VERSION "DNNBNNNYNNNNNNNNNNNNNNNNNNNNNNNNNNNNNNNNNN/4/%%%/4/'%**4NNN///"

NS_ :

BS_:

BU_: Vector__XXX xSolarWave xSolarSurveyor xSolarStorm xNova xMiata_SCP xMiata_AGS UI INV_CHG INV GATEWAY EMS DIAG CHG BMS BATTMON AGS

BO_ 2147554560 IntTempCfgUt: 223 AGS
 SG_ UtLvlMin : 88|32@1- (0.001,0) [-2.14748E+06|2.14748E+06] "°K" AGS,BATTMON,CHG,DIAG,GATEWAY,INV,INV_CHG,UI,xSolarSurveyor
 SG_ UtLvlMax : 120|32@1- (0.001,0) [-2.14748E+06|2.14748E+06] "°K" AGS,BATTMON,CHG,DIAG,GATEWAY,INV,INV_CHG,UI,xSolarSurveyor
 SG_ UtLvl : 56|32@1- (0.001,0) [-2.14748E+06|2.14748E+06] "°K" AGS,BATTMON,CHG,DIAG,GATEWAY,INV,INV_CHG,UI,xSolarSurveyor
 SG_ UtIntvlMin : 168|16@1+ (0.01,0) [0|655.32] "seconds" AGS,BATTMON,CHG,DIAG,GATEWAY,INV,INV_CHG,UI,xSolarSurveyor
 SG_ UtIntvlMax : 184|16@1+ (0.01,0) [0|655.32] "seconds" AGS,BATTMON,CHG,DIAG,GATEWAY,INV,INV_CHG,UI,xSolarSurveyor
 SG_ UtIntvl : 152|16@1+ (0.01,0) [0|655.32] "seconds" AGS,BATTMON,CHG,DIAG,GATEWAY,INV,INV_CHG,UI,xSolarSurveyor
 SG_ TempSensId : 16|8@1+ (1,0) [0|252] "" AGS,BATTMON,CHG,DIAG,GATEWAY,INV,INV_CHG,UI,xSolarSurveyor
 SG_ RefEvtId : 40|16@1+ (1,0) [0|65532] "" AGS,BATTMON,CHG,DIAG,GATEWAY,INV,INV_CHG,UI,xSolarSurveyor
 SG_ MsgCount : 2|6@1+ (1,0) [0|0] "" AGS,BATTMON,CHG,DIAG,GATEWAY,INV,INV_CHG,UI,xSolarSurveyor
 SG_ EvtId : 24|16@1+ (1,0) [0|65532] "" AGS,BATTMON,CHG,DIAG,GATEWAY,INV,INV_CHG,UI,xSolarSurveyor
 SG_ ConcurAccCtr : 8|8@1+ (1,0) [0|252] "" AGS,BATTMON,CHG,DIAG,GATEWAY,INV,INV_CHG,UI,xSolarSurveyor
 SG_ CfgType : 0|2@1+ (1,0) [0|0] "" AGS,BATTMON,CHG,DIAG,GATEWAY,INV,INV_CHG,UI,xSolarSurveyor

BO_ 2147554816 IntTempCfgOt: 223 AGS
 SG_ TempSensId : 16|8@1+ (1,0) [0|252] "" AGS,BATTMON,BMS,CHG,DIAG,GATEWAY,INV,INV_CHG,UI,xNova,xSolarSurveyor,xSolarWave
 SG_ RefEvtId : 40|16@1+ (1,0) [0|65532] "" AGS,BATTMON,BMS,CHG,DIAG,GATEWAY,INV,INV_CHG,UI,xNova,xSolarSurveyor,xSolarWave
 SG_ OtLvlMin : 88|32@1- (0.001,0) [-2.14748E+06|2.14748E+06] "°K" AGS,BATTMON,BMS,CHG,DIAG,GATEWAY,INV,INV_CHG,UI,xNova,xSolarSurveyor,xSolarWave
 SG_ OtLvlMax : 120|32@1- (0.001,0) [-2.14748E+06|2.14748E+06] "°K" AGS,BATTMON,BMS,CHG,DIAG,GATEWAY,INV,INV_CHG,UI,xNova,xSolarSurveyor,xSolarWave
 SG_ OtLvl : 56|32@1- (0.001,0) [-2.14748E+06|2.14748E+06] "°K" AGS,BATTMON,BMS,CHG,DIAG,GATEWAY,INV,INV_CHG,UI,xNova,xSolarSurveyor,xSolarWave
 SG_ OtIntvlMin : 168|16@1+ (0.01,0) [0|655.32] "seconds" AGS,BATTMON,BMS,CHG,DIAG,GATEWAY,INV,INV_CHG,UI,xNova,xSolarSurveyor,xSolarWave
 SG_ OtIntvlMax : 184|16@1+ (0.01,0) [0|655.32] "seconds" AGS,BATTMON,BMS,CHG,DIAG,GATEWAY,INV,INV_CHG,UI,xNova,xSolarSurveyor,xSolarWave
 SG_ OtIntvl : 152|16@1+ (0.01,0) [0|655.32] "seconds" AGS,BATTMON,BMS,CHG,DIAG,GATEWAY,INV,INV_CHG,UI,xNova,xSolarSurveyor,xSolarWave
 SG_ MsgCount : 2|6@1+ (1,0) [0|0] "" AGS,BATTMON,BMS,CHG,DIAG,GATEWAY,INV,INV_CHG,UI,xNova,xSolarSurveyor,xSolarWave
 SG_ EvtId : 24|16@1+ (1,0) [0|65532] "" AGS,BATTMON,BMS,CHG,DIAG,GATEWAY,INV,INV_CHG,UI,xNova,xSolarSurveyor,xSolarWave
 SG_ ConcurAccCtr : 8|8@1+ (1,0) [0|252] "" AGS,BATTMON,BMS,CHG,DIAG,GATEWAY,INV,INV_CHG,UI,xNova,xSolarSurveyor,xSolarWave
 SG_ CfgType : 0|2@1+ (1,0) [0|0] "" AGS,BATTMON,BMS,CHG,DIAG,GATEWAY,INV,INV_CHG,UI,xNova,xSolarSurveyor,xSolarWave

BO_ 2147612688 HwRevSts: 223 AGS
 SG_ RsvBits2 : 29|3@1+ (1,0) [0|0] "" DIAG,UI
 SG_ RsvBits1 : 0|2@1+ (1,0) [0|0] "" DIAG,UI
 SG_ MsgCount : 2|6@1+ (1,0) [0|0] "" DIAG,UI
 SG_ ModelNum : 8|16@1+ (1,0) [0|65532] "" DIAG,UI
 SG_ HwModSerNum : 48|128@1+ (1,0) [0|1785] "characters" DIAG,UI
 SG_ HwModRev : 32|16@1+ (1,0) [0|65532] "" DIAG,UI
 SG_ HwModInst : 24|5@1+ (1,0) [0|0] "" DIAG,UI

BO_ 2147610635 HvDcBusSts: 10 CHG
 SG_ Voltage : 16|32@1- (0.001,0) [-2.14748E+06|2.14748E+06] "V" CHG,DIAG,INV,INV_CHG
 SG_ RsvBits : 0|2@1+ (1,0) [0|0] "" CHG,DIAG,INV,INV_CHG
 SG_ OutputId : 8|8@1+ (1,0) [0|252] "" CHG,DIAG,INV,INV_CHG
 SG_ MsgCount : 2|6@1+ (1,0) [0|0] "" CHG,DIAG,INV,INV_CHG
 SG_ Current : 48|32@1- (0.001,0) [-2.14748E+06|2.14748E+06] "Amps" CHG,DIAG,INV,INV_CHG

BO_ 2147553536 HvDcBusCfgUv: 223 CHG
 SG_ UvLvlMin : 88|32@1- (0.001,0) [-2.14748E+06|2.14748E+06] "V" CHG,DIAG,INV,INV_CHG
 SG_ UvLvlMax : 120|32@1- (0.001,0) [-2.14748E+06|2.14748E+06] "V" CHG,DIAG,INV,INV_CHG
 SG_ UvLvl : 56|32@1- (0.001,0) [-2.14748E+06|2.14748E+06] "V" CHG,DIAG,INV,INV_CHG
 SG_ UvIntvlMin : 168|16@1+ (0.01,0) [0|655.32] "seconds" CHG,DIAG,INV,INV_CHG
 SG_ UvIntvlMax : 184|16@1+ (0.01,0) [0|655.32] "seconds" CHG,DIAG,INV,INV_CHG
 SG_ UvIntvl : 152|16@1+ (0.01,0) [0|655.32] "seconds" CHG,DIAG,INV,INV_CHG
 SG_ RefEvtId : 40|16@1+ (1,0) [0|65532] "" CHG,DIAG,INV,INV_CHG
 SG_ OutputId : 16|8@1+ (1,0) [0|252] "" CHG,DIAG,INV,INV_CHG
 SG_ MsgCount : 2|6@1+ (1,0) [0|0] "" CHG,DIAG,INV,INV_CHG
 SG_ EvtId : 24|16@1+ (1,0) [0|65532] "" CHG,DIAG,INV,INV_CHG
 SG_ ConcurAccCtr : 8|8@1+ (1,0) [0|252] "" CHG,DIAG,INV,INV_CHG
 SG_ CfgType : 0|2@1+ (1,0) [0|0] "" CHG,DIAG,INV,INV_CHG

BO_ 2147553792 HvDcBusCfgOv: 223 CHG
 SG_ RefEvtId : 40|16@1+ (1,0) [0|65532] "" CHG,DIAG,INV,INV_CHG
 SG_ OvLvlMin : 88|32@1- (0.001,0) [-2.14748E+06|2.14748E+06] "V" CHG,DIAG,INV,INV_CHG
 SG_ OvLvlMax : 120|32@1- (0.001,0) [-2.14748E+06|2.14748E+06] "V" CHG,DIAG,INV,INV_CHG
 SG_ OvLvl : 56|32@1- (0.001,0) [-2.14748E+06|2.14748E+06] "V" CHG,DIAG,INV,INV_CHG
 SG_ OvIntvlMin : 168|16@1+ (0.01,0) [0|655.32] "seconds" CHG,DIAG,INV,INV_CHG
 SG_ OvIntvlMax : 184|16@1+ (0.01,0) [0|655.32] "seconds" CHG,DIAG,INV,INV_CHG
 SG_ OvIntvl : 152|16@1+ (0.01,0) [0|655.32] "seconds" CHG,DIAG,INV,INV_CHG
 SG_ OutputId : 16|8@1+ (1,0) [0|252] "" CHG,DIAG,INV,INV_CHG
 SG_ MsgCount : 2|6@1+ (1,0) [0|0] "" CHG,DIAG,INV,INV_CHG
 SG_ EvtId : 24|16@1+ (1,0) [0|65532] "" CHG,DIAG,INV,INV_CHG
 SG_ ConcurAccCtr : 8|8@1+ (1,0) [0|252] "" CHG,DIAG,INV,INV_CHG
 SG_ CfgType : 0|2@1+ (1,0) [0|0] "" CHG,DIAG,INV,INV_CHG

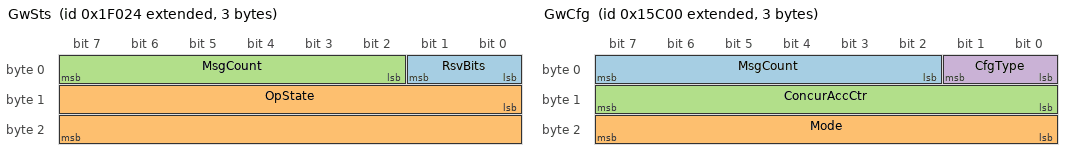
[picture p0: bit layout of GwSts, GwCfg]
BO_ 2147610660 GwSts: 3 GATEWAY
 SG_ RsvBits : 0|2@1+ (1,0) [0|0] "" DIAG,UI
 SG_ OpState : 8|16@1+ (1,0) [0|65532] "" DIAG,UI
 SG_ MsgCount : 2|6@1+ (1,0) [0|0] "" DIAG,UI

BO_ 2147610661 GwStats: 1 GATEWAY
 SG_ RsvBits : 0|2@1+ (1,0) [0|0] "" DIAG,UI
 SG_ MsgCount : 2|6@1+ (1,0) [0|0] "" DIAG,UI

BO_ 2147571968 GwCfgMsgFiltersXbIntf: 223 DIAG
 SG_ RsvBits : 42|6@1+ (1,0) [0|0] "" DIAG,GATEWAY
 SG_ Pgn : 16|24@1+ (1,0) [0|0] "" DIAG,GATEWAY
 SG_ MsgCount : 2|6@1+ (1,0) [0|0] "" DIAG,GATEWAY
 SG_ ConcurAccCtr : 8|8@1+ (1,0) [0|252] "" DIAG,GATEWAY
 SG_ CfgType : 0|2@1+ (1,0) [0|0] "" DIAG,GATEWAY
 SG_ AllowedEnDis : 40|2@1+ (1,0) [0|0] "" DIAG,GATEWAY

BO_ 2147572224 GwCfgMsgFiltersOthIntf: 223 DIAG
 SG_ RsvBits : 42|6@1+ (1,0) [0|0] "" DIAG,GATEWAY
 SG_ Pgn : 16|24@1+ (1,0) [0|0] "" DIAG,GATEWAY
 SG_ MsgCount : 2|6@1+ (1,0) [0|0] "" DIAG,GATEWAY
 SG_ ConcurAccCtr : 8|8@1+ (1,0) [0|252] "" DIAG,GATEWAY
 SG_ CfgType : 0|2@1+ (1,0) [0|0] "" DIAG,GATEWAY
 SG_ AllowedEnDis : 40|2@1+ (1,0) [0|0] "" DIAG,GATEWAY

BO_ 2147572992 GwCfgIdTrans: 223 DIAG
 SG_ XbId : 24|8@1+ (1,0) [0|252] "" DIAG,GATEWAY
 SG_ SrcType : 16|8@1+ (1,0) [0|252] "" DIAG,GATEWAY
 SG_ OthId : 32|8@1+ (1,0) [0|252] "" DIAG,GATEWAY
 SG_ MsgCount : 2|6@1+ (1,0) [0|0] "" DIAG,GATEWAY
 SG_ ConcurAccCtr : 8|8@1+ (1,0) [0|252] "" DIAG,GATEWAY
 SG_ CfgType : 0|2@1+ (1,0) [0|0] "" DIAG,GATEWAY

BO_ 2147571712 GwCfgAddrTransXbIntf: 223 DIAG
 SG_ XbSystemInstance : 40|4@1+ (1,0) [0|0] "" DIAG,GATEWAY
 SG_ XbDeviceInstanceUpper : 19|5@1+ (1,0) [0|0] "" DIAG,GATEWAY
 SG_ XbDeviceInstanceLower : 16|3@1+ (1,0) [0|0] "" DIAG,GATEWAY
 SG_ XbDeviceFunction : 24|8@1+ (1,0) [0|252] "" DIAG,GATEWAY
 SG_ XbDeviceClass : 33|7@1+ (1,0) [0|0] "" DIAG,GATEWAY
 SG_ RsvBits4 : 76|4@1+ (1,0) [0|0] "" DIAG,GATEWAY
 SG_ RsvBits3 : 64|1@1+ (1,0) [0|0] "" DIAG,GATEWAY
 SG_ RsvBits2 : 44|4@1+ (1,0) [0|0] "" DIAG,GATEWAY
 SG_ RsvBits1 : 32|1@1+ (1,0) [0|0] "" DIAG,GATEWAY
 SG_ OthSystemInstance : 72|4@1+ (1,0) [0|0] "" DIAG,GATEWAY
 SG_ OthDeviceInstanceUpper : 51|5@1+ (1,0) [0|0] "" DIAG,GATEWAY
 SG_ OthDeviceInstanceLower : 48|3@1+ (1,0) [0|0] "" DIAG,GATEWAY
 SG_ OthDeviceFunction : 56|8@1+ (1,0) [0|252] "" DIAG,GATEWAY
 SG_ OthDeviceClass : 65|7@1+ (1,0) [0|0] "" DIAG,GATEWAY
 SG_ MsgCount : 2|6@1+ (1,0) [0|0] "" DIAG,GATEWAY
 SG_ LoAddr : 80|8@1+ (1,0) [0|252] "" DIAG,GATEWAY
 SG_ HiAddr : 88|8@1+ (1,0) [0|252] "" DIAG,GATEWAY
 SG_ ConcurAccCtr : 8|8@1+ (1,0) [0|252] "" DIAG,GATEWAY
 SG_ CfgType : 0|2@1+ (1,0) [0|0] "" DIAG,GATEWAY

BO_ 2147572480 GwCfgAddrTransOthIntf: 223 DIAG
 SG_ XbSystemInstance : 72|4@1+ (1,0) [0|0] "" DIAG,GATEWAY
 SG_ XbDeviceInstanceUpper : 51|5@1+ (1,0) [0|0] "" DIAG,GATEWAY
 SG_ XbDeviceInstanceLower : 48|3@1+ (1,0) [0|0] "" DIAG,GATEWAY
 SG_ XbDeviceFunction : 56|8@1+ (1,0) [0|252] "" DIAG,GATEWAY
 SG_ XbDeviceClass : 65|7@1+ (1,0) [0|0] "" DIAG,GATEWAY
 SG_ RsvBits4 : 76|4@1+ (1,0) [0|0] "" DIAG,GATEWAY
 SG_ RsvBits3 : 64|1@1+ (1,0) [0|0] "" DIAG,GATEWAY
 SG_ RsvBits2 : 44|4@1+ (1,0) [0|0] "" DIAG,GATEWAY
 SG_ RsvBits1 : 32|1@1+ (1,0) [0|0] "" DIAG,GATEWAY
 SG_ OthSystemInstance : 40|4@1+ (1,0) [0|0] "" DIAG,GATEWAY
 SG_ OthDeviceInstanceUpper : 19|5@1+ (1,0) [0|0] "" DIAG,GATEWAY
 SG_ OthDeviceInstanceLower : 16|3@1+ (1,0) [0|0] "" DIAG,GATEWAY
 SG_ OthDeviceFunction : 24|8@1+ (1,0) [0|252] "" DIAG,GATEWAY
 SG_ OthDeviceClass : 33|7@1+ (1,0) [0|0] "" DIAG,GATEWAY
 SG_ MsgCount : 2|6@1+ (1,0) [0|0] "" DIAG,GATEWAY
 SG_ ConcurAccCtr : 8|8@1+ (1,0) [0|252] "" DIAG,GATEWAY
 SG_ CfgType : 0|2@1+ (1,0) [0|0] "" DIAG,GATEWAY

BO_ 2147572736 GwCfg: 3 DIAG
 SG_ MsgCount : 2|6@1+ (1,0) [0|0] "" DIAG,GATEWAY
 SG_ Mode : 16|8@1+ (1,0) [0|252] "" DIAG,GATEWAY
 SG_ ConcurAccCtr : 8|8@1+ (1,0) [0|252] "" DIAG,GATEWAY
 SG_ CfgType : 0|2@1+ (1,0) [0|0] "" DIAG,GATEWAY

BO_ 2147576320 GvsCfg: 52 DIAG
 SG_ VThresholdMin : 336|16@1+ (0.01,0) [0|655.32] "V" DIAG,UI,xSolarWave
 SG_ VThresholdMax : 352|16@1+ (0.01,0) [0|655.32] "V" DIAG,UI,xSolarWave
 SG_ VThreshold : 320|16@1+ (0.01,0) [0|655.32] "V" DIAG,UI,xSolarWave
 SG_ VSetLowMin : 288|16@1+ (0.01,0) [0|655.32] "V" DIAG,UI,xSolarWave
 SG_ VSetLowMax : 304|16@1+ (0.01,0) [0|655.32] "V" DIAG,UI,xSolarWave
 SG_ VSetLow : 272|16@1+ (0.01,0) [0|655.32] "V" DIAG,UI,xSolarWave
 SG_ VSetHighMin : 240|16@1+ (0.01,0) [0|655.32] "V" DIAG,UI,xSolarWave
 SG_ VSetHighMax : 256|16@1+ (0.01,0) [0|655.32] "V" DIAG,UI,xSolarWave
 SG_ VSetHigh : 224|16@1+ (0.01,0) [0|655.32] "V" DIAG,UI,xSolarWave
 SG_ RsvBits : 26|6@1+ (1,0) [0|0] "" DIAG,UI,xSolarWave
 SG_ MsgCount : 2|6@1+ (1,0) [0|0] "" DIAG,UI,xSolarWave
 SG_ MinVGridMin : 192|16@1+ (0.01,0) [0|655.32] "V" DIAG,UI,xSolarWave
 SG_ MinVGridMax : 208|16@1+ (0.01,0) [0|655.32] "V" DIAG,UI,xSolarWave
 SG_ MinVGrid : 176|16@1+ (0.01,0) [0|655.32] "V" DIAG,UI,xSolarWave
 SG_ MaxVGridMin : 144|16@1+ (0.01,0) [0|655.32] "V" DIAG,UI,xSolarWave
 SG_ MaxVGridMax : 160|16@1+ (0.01,0) [0|655.32] "V" DIAG,UI,xSolarWave
 SG_ MaxVGrid : 128|16@1+ (0.01,0) [0|655.32] "V" DIAG,UI,xSolarWave
 SG_ MaxQIndMin : 96|16@1+ (0.01,0) [0|655.32] "%" DIAG,UI,xSolarWave
 SG_ MaxQIndMax : 112|16@1+ (0.01,0) [0|655.32] "%" DIAG,UI,xSolarWave
 SG_ MaxQInd : 80|16@1+ (0.01,0) [0|655.32] "%" DIAG,UI,xSolarWave
 SG_ MaxQCapMin : 48|16@1+ (0.01,0) [0|655.32] "%" DIAG,UI,xSolarWave
 SG_ MaxQCapMax : 64|16@1+ (0.01,0) [0|655.32] "%" DIAG,UI,xSolarWave
 SG_ MaxQCap : 32|16@1+ (0.01,0) [0|655.32] "%" DIAG,UI,xSolarWave
 SG_ GvsEnDis : 24|2@1+ (1,0) [0|0] "" DIAG,UI,xSolarWave
 SG_ DelayTimeMin : 384|16@1+ (0.01,0) [0|655.32] "seconds" DIAG,UI,xSolarWave
 SG_ DelayTimeMax : 400|16@1+ (0.01,0) [0|655.32] "seconds" DIAG,UI,xSolarWave
 SG_ DelayTime : 368|16@1+ (0.01,0) [0|655.32] "seconds" DIAG,UI,xSolarWave
 SG_ ConcurAccCtr : 8|8@1+ (1,0) [0|252] "" DIAG,UI,xSolarWave
 SG_ CfgType : 0|2@1+ (1,0) [0|0] "" DIAG,UI,xSolarWave
 SG_ AcSrcId : 16|8@1+ (1,0) [0|252] "" DIAG,UI,xSolarWave

BO_ 2147575296 GridTieCtrlCmd: 3 DIAG
 SG_ MaxSellScalePrcnt : 8|16@1+ (0.01,0) [0|655.32] "%" INV,INV_CHG,xSolarWave
 SG_ AcSrcId : 0|8@1+ (1,0) [0|252] "" INV,INV_CHG,xSolarWave

BO_ 2147576576 GridTieCfgBattSoc: 22 DIAG
 SG_ TimeIntStopMin : 144|16@1+ (1,0) [0|65532] "seconds" DIAG,UI,xSolarWave
 SG_ TimeIntStopMax : 160|16@1+ (1,0) [0|65532] "seconds" DIAG,UI,xSolarWave
 SG_ TimeIntStop : 128|16@1+ (1,0) [0|65532] "seconds" DIAG,UI,xSolarWave
 SG_ TimeIntStartMin : 96|16@1+ (1,0) [0|65532] "seconds" DIAG,UI,xSolarWave
 SG_ TimeIntStartMax : 112|16@1+ (1,0) [0|65532] "seconds" DIAG,UI,xSolarWave
 SG_ TimeIntStart : 80|16@1+ (1,0) [0|65532] "seconds" DIAG,UI,xSolarWave
 SG_ SocLvlStopMin : 64|8@1+ (1,0) [0|252] "%" DIAG,UI,xSolarWave
 SG_ SocLvlStopMax : 72|8@1+ (1,0) [0|252] "%" DIAG,UI,xSolarWave
 SG_ SocLvlStop : 56|8@1+ (1,0) [0|252] "%" DIAG,UI,xSolarWave
 SG_ SocLvlStartMin : 40|8@1+ (1,0) [0|252] "%" DIAG,UI,xSolarWave
 SG_ SocLvlStartMax : 48|8@1+ (1,0) [0|252] "%" DIAG,UI,xSolarWave
 SG_ SocLvlStart : 32|8@1+ (1,0) [0|252] "%" DIAG,UI,xSolarWave
 SG_ RsvBits : 26|6@1+ (1,0) [0|0] "" DIAG,UI,xSolarWave
 SG_ MsgCount : 2|6@1+ (1,0) [0|0] "" DIAG,UI,xSolarWave
 SG_ GridTieSocEnDis : 24|2@1+ (1,0) [0|0] "" DIAG,UI,xSolarWave
 SG_ ConcurAccCtr : 8|8@1+ (1,0) [0|252] "" DIAG,UI,xSolarWave
 SG_ CfgType : 0|2@1+ (1,0) [0|0] "" DIAG,UI,xSolarWave
 SG_ AcSrcId : 16|8@1+ (1,0) [0|252] "" DIAG,UI,xSolarWave

BO_ 2147598336 GridTieCfg: 72 DIAG
 SG_ SellMode : 32|8@1+ (1,0) [0|252] "" DIAG,UI,xSolarWave
 SG_ SellDuration : 40|16@1+ (1,0) [0|65532] "minutes" DIAG,UI,xSolarWave
 SG_ RsvBits : 30|2@1+ (1,0) [0|0] "" DIAG,UI,xSolarWave
 SG_ PeakLoadShavingIMin : 192|32@1+ (0.001,0) [0|4.29497E+06] "Amps" DIAG,UI,xSolarWave
 SG_ PeakLoadShavingIMax : 224|32@1+ (0.001,0) [0|4.29497E+06] "Amps" DIAG,UI,xSolarWave
 SG_ PeakLoadShavingI : 160|32@1+ (0.001,0) [0|4.29497E+06] "Amps" DIAG,UI,xSolarWave
 SG_ PeakLoadShavingEnDis : 26|2@1+ (1,0) [0|0] "" DIAG,UI,xSolarWave
 SG_ MsgCount : 2|6@1+ (1,0) [0|0] "" DIAG,UI,xSolarWave
 SG_ MaxSellScalePrcnt : 56|8@1+ (1,0) [0|252] "%" DIAG,UI,xSolarWave
 SG_ MaxSellIMin : 96|32@1+ (0.001,0) [0|4.29497E+06] "Amps" DIAG,UI,xSolarWave
 SG_ MaxSellIMax : 128|32@1+ (0.001,0) [0|4.29497E+06] "Amps" DIAG,UI,xSolarWave
 SG_ MaxSellI : 64|32@1+ (0.001,0) [0|4.29497E+06] "Amps" DIAG,UI,xSolarWave
 SG_ GridTieEnDis : 28|2@1+ (1,0) [0|0] "" DIAG,UI,xSolarWave
 SG_ ConcurAccCtr : 8|8@1+ (1,0) [0|252] "" DIAG,UI,xSolarWave
 SG_ CfgType : 0|2@1+ (1,0) [0|0] "" DIAG,UI,xSolarWave
 SG_ AntiIslandingEnDis : 24|2@1+ (1,0) [0|0] "" DIAG,UI,xSolarWave
 SG_ AIReconnect : 256|16@1+ (1,0) [0|65532] "seconds" DIAG,UI,xSolarWave
 SG_ AIDisconUvLNSlow : 480|32@1+ (0.001,0) [0|4.29497E+06] "V" DIAG,UI,xSolarWave
 SG_ AIDisconUvLNFast : 448|32@1+ (0.001,0) [0|4.29497E+06] "V" DIAG,UI,xSolarWave
 SG_ AIDisconUvL1L2Slow : 512|32@1+ (0.001,0) [0|4.29497E+06] "V" DIAG,UI,xSolarWave
 SG_ AIDisconUvL1L2Fast : 544|32@1+ (0.001,0) [0|4.29497E+06] "V" DIAG,UI,xSolarWave
 SG_ AIDisconUf : 304|16@1+ (0.01,0) [0|655.32] "Hz" DIAG,UI,xSolarWave
 SG_ AIDisconSlowDelay : 272|16@1+ (0.001,0) [0|65.532] "seconds" DIAG,UI,xSolarWave
 SG_ AIDisconOvLNSlow : 352|32@1+ (0.001,0) [0|4.29497E+06] "V" DIAG,UI,xSolarWave
 SG_ AIDisconOvLNFast : 320|32@1+ (0.001,0) [0|4.29497E+06] "V" DIAG,UI,xSolarWave
 SG_ AIDisconOvL1L2Slow : 416|32@1+ (0.001,0) [0|4.29497E+06] "V" DIAG,UI,xSolarWave
 SG_ AIDisconOvL1L2Fast : 384|32@1+ (0.001,0) [0|4.29497E+06] "V" DIAG,UI,xSolarWave
 SG_ AIDisconOf : 288|16@1+ (0.01,0) [0|655.32] "Hz" DIAG,UI,xSolarWave
 SG_ AcSrcId : 16|8@1+ (1,0) [0|252] "" DIAG,UI,xSolarWave

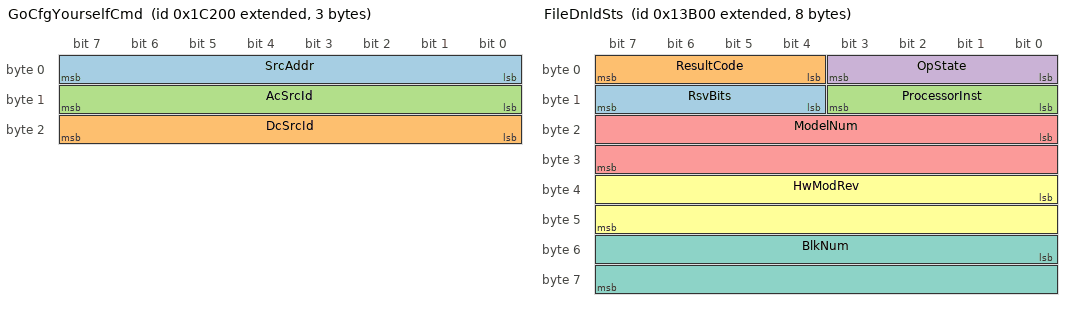
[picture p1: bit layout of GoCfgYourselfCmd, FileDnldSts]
BO_ 2147598848 GoCfgYourselfCmd: 3 DIAG
 SG_ SrcAddr : 0|8@1+ (1,0) [0|252] "" AGS,BATTMON,CHG,INV,INV_CHG,xSolarSurveyor,xSolarWave
 SG_ DcSrcId : 16|8@1+ (1,0) [0|252] "" AGS,BATTMON,CHG,INV,INV_CHG,xSolarSurveyor,xSolarWave
 SG_ AcSrcId : 8|8@1+ (1,0) [0|252] "" AGS,BATTMON,CHG,INV,INV_CHG,xSolarSurveyor,xSolarWave

BO_ 2147574016 GfsCfg: 58 DIAG
 SG_ RsvBits : 26|6@1+ (1,0) [0|0] "" DIAG,UI,xSolarWave
 SG_ MsgCount : 2|6@1+ (1,0) [0|0] "" DIAG,UI,xSolarWave
 SG_ GfsEnDis : 24|2@1+ (1,0) [0|0] "" DIAG,UI,xSolarWave
 SG_ ConcurAccCtr : 8|8@1+ (1,0) [0|252] "" DIAG,UI,xSolarWave
 SG_ CfgType : 0|2@1+ (1,0) [0|0] "" DIAG,UI,xSolarWave
 SG_ AprPtGradientMin : 432|16@1+ (1,0) [0|65532] "%" DIAG,UI,xSolarWave
 SG_ AprPtGradientMax : 448|16@1+ (1,0) [0|65532] "%" DIAG,UI,xSolarWave
 SG_ AprPtGradient : 416|16@1+ (1,0) [0|65532] "%" DIAG,UI,xSolarWave
 SG_ AprPfGradientMin : 384|16@1+ (1,0) [0|65532] "%" DIAG,UI,xSolarWave
 SG_ AprPfGradientMax : 400|16@1+ (1,0) [0|65532] "%" DIAG,UI,xSolarWave
 SG_ AprPfGradient : 368|16@1+ (1,0) [0|65532] "%" DIAG,UI,xSolarWave
 SG_ AprFreqStopLvlMin : 288|16@1+ (0.01,0) [0|655.32] "Hz" DIAG,UI,xSolarWave
 SG_ AprFreqStopLvlMax : 304|16@1+ (0.01,0) [0|655.32] "Hz" DIAG,UI,xSolarWave
 SG_ AprFreqStopLvl : 272|16@1+ (0.01,0) [0|655.32] "Hz" DIAG,UI,xSolarWave
 SG_ AprFreqStartLvlMin : 240|16@1+ (0.01,0) [0|655.32] "Hz" DIAG,UI,xSolarWave
 SG_ AprFreqStartLvlMax : 256|16@1+ (0.01,0) [0|655.32] "Hz" DIAG,UI,xSolarWave
 SG_ AprFreqStartLvl : 224|16@1+ (0.01,0) [0|655.32] "Hz" DIAG,UI,xSolarWave
 SG_ AprFreqRecoverLvlMin : 336|16@1+ (0.01,0) [0|655.32] "Hz" DIAG,UI,xSolarWave
 SG_ AprFreqRecoverLvlMax : 352|16@1+ (0.01,0) [0|655.32] "Hz" DIAG,UI,xSolarWave
 SG_ AprFreqRecoverLvl : 320|16@1+ (0.01,0) [0|655.32] "Hz" DIAG,UI,xSolarWave
 SG_ ApiPtGradientMin : 192|16@1+ (1,0) [0|65532] "%" DIAG,UI,xSolarWave
 SG_ ApiPtGradientMax : 208|16@1+ (1,0) [0|65532] "%" DIAG,UI,xSolarWave
 SG_ ApiPtGradient : 176|16@1+ (1,0) [0|65532] "%" DIAG,UI,xSolarWave
 SG_ ApiFreqStopLvlMin : 96|16@1+ (0.01,0) [0|655.32] "Hz" DIAG,UI,xSolarWave
 SG_ ApiFreqStopLvlMax : 112|16@1+ (0.01,0) [0|655.32] "Hz" DIAG,UI,xSolarWave
 SG_ ApiFreqStopLvl : 80|16@1+ (0.01,0) [0|655.32] "Hz" DIAG,UI,xSolarWave
 SG_ ApiFreqStartLvlMin : 48|16@1+ (0.01,0) [0|655.32] "Hz" DIAG,UI,xSolarWave
 SG_ ApiFreqStartLvlMax : 64|16@1+ (0.01,0) [0|655.32] "Hz" DIAG,UI,xSolarWave
 SG_ ApiFreqStartLvl : 32|16@1+ (0.01,0) [0|655.32] "Hz" DIAG,UI,xSolarWave
 SG_ ApiFreqRecoverLvlMin : 144|16@1+ (0.01,0) [0|655.32] "Hz" DIAG,UI,xSolarWave
 SG_ ApiFreqRecoverLvlMax : 160|16@1+ (0.01,0) [0|655.32] "Hz" DIAG,UI,xSolarWave
 SG_ ApiFreqRecoverLvl : 128|16@1+ (0.01,0) [0|655.32] "Hz" DIAG,UI,xSolarWave
 SG_ AcSrcId : 16|8@1+ (1,0) [0|252] "" DIAG,UI,xSolarWave

BO_ 2147564288 FileDnldSts: 8 Vector__XXX
 SG_ RsvBits : 12|4@1+ (1,0) [0|0] "" DIAG,UI
 SG_ ResultCode : 4|4@1+ (1,0) [0|0] "" DIAG,UI
 SG_ ProcessorInst : 8|4@1+ (1,0) [0|0] "" DIAG,UI
 SG_ OpState : 0|4@1+ (1,0) [0|0] "" DIAG,UI
 SG_ ModelNum : 16|16@1+ (1,0) [0|65532] "" DIAG,UI
 SG_ HwModRev : 32|16@1+ (1,0) [0|65532] "" DIAG,UI
 SG_ BlkNum : 48|16@1+ (1,0) [0|65532] "" DIAG,UI

BO_ 2147561984 FileDnldInf: 15 DIAG
 SG_ SwVer : 24|32@1+ (1,0) [0|4.29497E+09] "" Vector__XXX
 SG_ SwModId : 16|8@1+ (1,0) [0|252] "" Vector__XXX
 SG_ RsvBits : 12|4@1+ (1,0) [0|0] "" Vector__XXX
 SG_ ProcessorInst : 8|4@1+ (1,0) [0|0] "" Vector__XXX
 SG_ FileSz : 56|32@1+ (1,0) [0|4.29497E+09] "" Vector__XXX
 SG_ ExpectNumBlks : 104|16@1+ (1,0) [0|65532] "" Vector__XXX
 SG_ DeviceFunction : 0|8@1+ (1,0) [0|252] "" Vector__XXX
 SG_ Crc : 88|16@1+ (1,0) [0|65532] "" Vector__XXX

BO_ 2147561728 FileDnldBlk: 1785 DIAG
 SG_ BlkSz : 16|16@1+ (1,0) [0|65532] "" Vector__XXX
 SG_ BlkNum : 0|16@1+ (1,0) [0|65532] "" Vector__XXX
 SG_ BlkData : 32|8@1+ (1,0) [0|1785] "8-Bit Bytes" Vector__XXX

BO_ 2147567872 FeatureEnDisCfg: 223 AGS
 SG_ RsvBits : 26|6@1+ (1,0) [0|0] "" AGS,BATTMON,BMS,CHG,DIAG,GATEWAY,INV,INV_CHG,UI,xMiata_AGS,xNova,xSolarSurveyor,xSolarWave
 SG_ MsgCount : 2|6@1+ (1,0) [0|0] "" AGS,BATTMON,BMS,CHG,DIAG,GATEWAY,INV,INV_CHG,UI,xMiata_AGS,xNova,xSolarSurveyor,xSolarWave
 SG_ FeatureName : 32|128@1+ (1,0) [0|1785] "characters" AGS,BATTMON,BMS,CHG,DIAG,GATEWAY,INV,INV_CHG,UI,xMiata_AGS,xNova,xSolarSurveyor,xSolarWave
 SG_ FeatureId : 16|8@1+ (1,0) [0|252] "" AGS,BATTMON,BMS,CHG,DIAG,GATEWAY,INV,INV_CHG,UI,xMiata_AGS,xNova,xSolarSurveyor,xSolarWave
 SG_ FeatureEnDis : 24|2@1+ (1,0) [0|0] "" AGS,BATTMON,BMS,CHG,DIAG,GATEWAY,INV,INV_CHG,UI,xMiata_AGS,xNova,xSolarSurveyor,xSolarWave
 SG_ ConcurAccCtr : 8|8@1+ (1,0) [0|252] "" AGS,BATTMON,BMS,CHG,DIAG,GATEWAY,INV,INV_CHG,UI,xMiata_AGS,xNova,xSolarSurveyor,xSolarWave
 SG_ CfgType : 0|2@1+ (1,0) [0|0] "" AGS,BATTMON,BMS,CHG,DIAG,GATEWAY,INV,INV_CHG,UI,xMiata_AGS,xNova,xSolarSurveyor,xSolarWave

BO_ 2147612872 FaultLogSts2: 223 AGS
 SG_ StringId : 56|16@1+ (1,0) [0|65532] "" DIAG,UI
 SG_ RsvBits : 0|2@1+ (1,0) [0|0] "" DIAG,UI
 SG_ MsgCount : 2|6@1+ (1,0) [0|0] "" DIAG,UI
 SG_ FaultType : 8|3@1+ (1,0) [0|0] "" DIAG,UI
 SG_ FaultTime : 24|32@1+ (1,0) [0|4.29497E+09] "seconds" DIAG,UI
 SG_ FaultId : 11|13@1+ (1,0) [0|0] "" DIAG,UI

BO_ 2147610643 FaultLogSts: 223 AGS
 SG_ RsvBits : 0|2@1+ (1,0) [0|0] "" DIAG,UI
 SG_ MsgCount : 2|6@1+ (1,0) [0|0] "" DIAG,UI
 SG_ FaultType : 8|3@1+ (1,0) [0|0] "" DIAG,UI
 SG_ FaultTime : 24|32@1+ (1,0) [0|4.29497E+09] "seconds" DIAG,UI
 SG_ FaultId : 11|13@1+ (1,0) [0|0] "" DIAG,UI

BO_ 2147610827 FanSts: 223 CHG
 SG_ RsvBits : 0|2@1+ (1,0) [0|0] "" DIAG,GATEWAY,UI
 SG_ MsgCount : 2|6@1+ (1,0) [0|0] "" DIAG,GATEWAY,UI
 SG_ FanSpeed : 16|8@1+ (1,0) [0|252] "%" DIAG,GATEWAY,UI
 SG_ FanId : 8|8@1+ (1,0) [0|252] "" DIAG,GATEWAY,UI

BO_ 2147610828 FanStats: 223 CHG
 SG_ RsvBits : 0|2@1+ (1,0) [0|0] "" DIAG,GATEWAY,UI
 SG_ MsgCount : 2|6@1+ (1,0) [0|0] "" DIAG,GATEWAY,UI
 SG_ FanRunTimeMin : 16|32@1+ (1,0) [0|4.29497E+09] "" DIAG,GATEWAY,UI
 SG_ FanId : 8|8@1+ (1,0) [0|252] "" DIAG,GATEWAY,UI

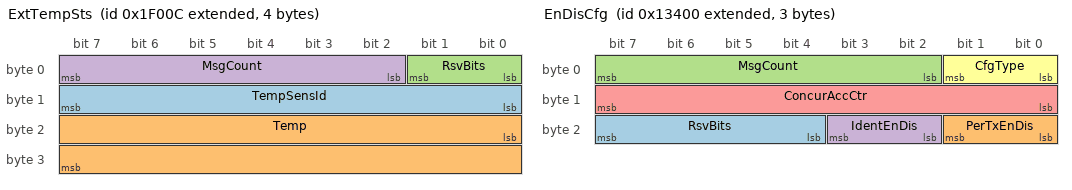
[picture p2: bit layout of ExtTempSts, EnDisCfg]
BO_ 2147610636 ExtTempSts: 4 AGS
 SG_ TempSensId : 8|8@1+ (1,0) [0|252] "" AGS,BATTMON,CHG,DIAG,INV,INV_CHG,UI
 SG_ Temp : 16|16@1+ (0.01,0) [0|655.32] "°K" AGS,BATTMON,CHG,DIAG,INV,INV_CHG,UI
 SG_ RsvBits : 0|2@1+ (1,0) [0|0] "" AGS,BATTMON,CHG,DIAG,INV,INV_CHG,UI
 SG_ MsgCount : 2|6@1+ (1,0) [0|0] "" AGS,BATTMON,CHG,DIAG,INV,INV_CHG,UI

BO_ 2147610823 ExtTempStats2: 223 AGS
 SG_ TempSensId : 8|8@1+ (1,0) [0|252] "" DIAG,UI
 SG_ TempMin : 24|16@1+ (0.01,0) [0|655.32] "°K" DIAG,UI
 SG_ TempMax : 40|16@1+ (0.01,0) [0|655.32] "°K" DIAG,UI
 SG_ RsvBits : 0|2@1+ (1,0) [0|0] "" DIAG,UI
 SG_ PreviousPeriodCount : 19|5@1+ (1,0) [0|0] "" DIAG,UI
 SG_ PreviousPeriod : 16|3@1+ (1,0) [0|0] "" DIAG,UI
 SG_ MsgCount : 2|6@1+ (1,0) [0|0] "" DIAG,UI

BO_ 2147554048 ExtTempCfgUt: 223 AGS
 SG_ UtLvlMin : 88|32@1- (0.001,0) [-2.14748E+06|2.14748E+06] "°K" AGS,BATTMON,BMS,CHG,DIAG,INV,INV_CHG,UI,xNova,xSolarSurveyor,xSolarWave
 SG_ UtLvlMax : 120|32@1- (0.001,0) [-2.14748E+06|2.14748E+06] "°K" AGS,BATTMON,BMS,CHG,DIAG,INV,INV_CHG,UI,xNova,xSolarSurveyor,xSolarWave
 SG_ UtLvl : 56|32@1- (0.001,0) [-2.14748E+06|2.14748E+06] "°K" AGS,BATTMON,BMS,CHG,DIAG,INV,INV_CHG,UI,xNova,xSolarSurveyor,xSolarWave
 SG_ UtIntvlMin : 168|16@1+ (0.01,0) [0|655.32] "seconds" AGS,BATTMON,BMS,CHG,DIAG,INV,INV_CHG,UI,xNova,xSolarSurveyor,xSolarWave
 SG_ UtIntvlMax : 184|16@1+ (0.01,0) [0|655.32] "seconds" AGS,BATTMON,BMS,CHG,DIAG,INV,INV_CHG,UI,xNova,xSolarSurveyor,xSolarWave
 SG_ UtIntvl : 152|16@1+ (0.01,0) [0|655.32] "seconds" AGS,BATTMON,BMS,CHG,DIAG,INV,INV_CHG,UI,xNova,xSolarSurveyor,xSolarWave
 SG_ TempSensId : 16|8@1+ (1,0) [0|252] "" AGS,BATTMON,BMS,CHG,DIAG,INV,INV_CHG,UI,xNova,xSolarSurveyor,xSolarWave
 SG_ RefEvtId : 40|16@1+ (1,0) [0|65532] "" AGS,BATTMON,BMS,CHG,DIAG,INV,INV_CHG,UI,xNova,xSolarSurveyor,xSolarWave
 SG_ MsgCount : 2|6@1+ (1,0) [0|0] "" AGS,BATTMON,BMS,CHG,DIAG,INV,INV_CHG,UI,xNova,xSolarSurveyor,xSolarWave
 SG_ EvtId : 24|16@1+ (1,0) [0|65532] "" AGS,BATTMON,BMS,CHG,DIAG,INV,INV_CHG,UI,xNova,xSolarSurveyor,xSolarWave
 SG_ ConcurAccCtr : 8|8@1+ (1,0) [0|252] "" AGS,BATTMON,BMS,CHG,DIAG,INV,INV_CHG,UI,xNova,xSolarSurveyor,xSolarWave
 SG_ CfgType : 0|2@1+ (1,0) [0|0] "" AGS,BATTMON,BMS,CHG,DIAG,INV,INV_CHG,UI,xNova,xSolarSurveyor,xSolarWave

BO_ 2147554304 ExtTempCfgOt: 223 AGS
 SG_ TempSensId : 16|8@1+ (1,0) [0|252] "" AGS,BATTMON,BMS,CHG,DIAG,INV,INV_CHG,UI,xNova,xSolarSurveyor,xSolarWave
 SG_ RefEvtId : 40|16@1+ (1,0) [0|65532] "" AGS,BATTMON,BMS,CHG,DIAG,INV,INV_CHG,UI,xNova,xSolarSurveyor,xSolarWave
 SG_ OtLvlMin : 88|32@1- (0.001,0) [-2.14748E+06|2.14748E+06] "°K" AGS,BATTMON,BMS,CHG,DIAG,INV,INV_CHG,UI,xNova,xSolarSurveyor,xSolarWave
 SG_ OtLvlMax : 120|32@1- (0.001,0) [-2.14748E+06|2.14748E+06] "°K" AGS,BATTMON,BMS,CHG,DIAG,INV,INV_CHG,UI,xNova,xSolarSurveyor,xSolarWave
 SG_ OtLvl : 56|32@1- (0.001,0) [-2.14748E+06|2.14748E+06] "°K" AGS,BATTMON,BMS,CHG,DIAG,INV,INV_CHG,UI,xNova,xSolarSurveyor,xSolarWave
 SG_ OtIntvlMin : 168|16@1+ (0.01,0) [0|655.32] "seconds" AGS,BATTMON,BMS,CHG,DIAG,INV,INV_CHG,UI,xNova,xSolarSurveyor,xSolarWave
 SG_ OtIntvlMax : 184|16@1+ (0.01,0) [0|655.32] "seconds" AGS,BATTMON,BMS,CHG,DIAG,INV,INV_CHG,UI,xNova,xSolarSurveyor,xSolarWave
 SG_ OtIntvl : 152|16@1+ (0.01,0) [0|655.32] "seconds" AGS,BATTMON,BMS,CHG,DIAG,INV,INV_CHG,UI,xNova,xSolarSurveyor,xSolarWave
 SG_ MsgCount : 2|6@1+ (1,0) [0|0] "" AGS,BATTMON,BMS,CHG,DIAG,INV,INV_CHG,UI,xNova,xSolarSurveyor,xSolarWave
 SG_ EvtId : 24|16@1+ (1,0) [0|65532] "" AGS,BATTMON,BMS,CHG,DIAG,INV,INV_CHG,UI,xNova,xSolarSurveyor,xSolarWave
 SG_ ConcurAccCtr : 8|8@1+ (1,0) [0|252] "" AGS,BATTMON,BMS,CHG,DIAG,INV,INV_CHG,UI,xNova,xSolarSurveyor,xSolarWave
 SG_ CfgType : 0|2@1+ (1,0) [0|0] "" AGS,BATTMON,BMS,CHG,DIAG,INV,INV_CHG,UI,xNova,xSolarSurveyor,xSolarWave

BO_ 2147598592 EnDisCfgTod: 223 DIAG
 SG_ TodEnd : 48|16@1+ (1,0) [0|65532] "minutes" DIAG,UI,xSolarWave
 SG_ TodBeg : 32|16@1+ (1,0) [0|65532] "minutes" DIAG,UI,xSolarWave
 SG_ MsgCount : 2|6@1+ (1,0) [0|0] "" DIAG,UI,xSolarWave
 SG_ FeatureOverride : 16|8@1+ (1,0) [0|252] "" DIAG,UI,xSolarWave
 SG_ EvtDowMask : 24|8@1+ (1,0) [0|252] "" DIAG,UI,xSolarWave
 SG_ ConcurAccCtr : 8|8@1+ (1,0) [0|252] "" DIAG,UI,xSolarWave
 SG_ CfgType : 0|2@1+ (1,0) [0|0] "" DIAG,UI,xSolarWave

BO_ 2147562496 EnDisCfg: 3 AGS
 SG_ RsvBits : 20|4@1+ (1,0) [0|0] "" AGS,BATTMON,BMS,CHG,DIAG,EMS,GATEWAY,INV,INV_CHG,UI,xMiata_AGS,xNova,xSolarSurveyor,xSolarWave
 SG_ PerTxEnDis : 16|2@1+ (1,0) [0|0] "" AGS,BATTMON,BMS,CHG,DIAG,EMS,GATEWAY,INV,INV_CHG,UI,xMiata_AGS,xNova,xSolarSurveyor,xSolarWave
 SG_ MsgCount : 2|6@1+ (1,0) [0|0] "" AGS,BATTMON,BMS,CHG,DIAG,EMS,GATEWAY,INV,INV_CHG,UI,xMiata_AGS,xNova,xSolarSurveyor,xSolarWave
 SG_ IdentEnDis : 18|2@1+ (1,0) [0|0] "" AGS,BATTMON,BMS,CHG,DIAG,EMS,GATEWAY,INV,INV_CHG,UI,xMiata_AGS,xNova,xSolarSurveyor,xSolarWave
 SG_ ConcurAccCtr : 8|8@1+ (1,0) [0|252] "" AGS,BATTMON,BMS,CHG,DIAG,EMS,GATEWAY,INV,INV_CHG,UI,xMiata_AGS,xNova,xSolarSurveyor,xSolarWave
 SG_ CfgType : 0|2@1+ (1,0) [0|0] "" AGS,BATTMON,BMS,CHG,DIAG,EMS,GATEWAY,INV,INV_CHG,UI,xMiata_AGS,xNova,xSolarSurveyor,xSolarWave

BO_ 2147610663 EmsSts: 223 DIAG
 SG_ RsvBits2 : 42|6@1+ (1,0) [0|0] "" DIAG,EMS,INV_CHG,UI,xSolarWave
 SG_ RsvBits1 : 0|2@1+ (1,0) [0|0] "" DIAG,EMS,INV_CHG,UI,xSolarWave
 SG_ RequestAcDisqualify : 40|2@1+ (1,0) [0|0] "" DIAG,EMS,INV_CHG,UI,xSolarWave
 SG_ MsgCount : 2|6@1+ (1,0) [0|0] "" DIAG,EMS,INV_CHG,UI,xSolarWave
 SG_ AvailableCapacity : 24|16@1- (0.01,0) [-327.68|327.68] "A" DIAG,EMS,INV_CHG,UI,xSolarWave
 SG_ AcSrcType : 8|8@1+ (1,0) [0|252] "" DIAG,EMS,INV_CHG,UI,xSolarWave
 SG_ AcLine : 16|8@1+ (1,0) [0|252] "" DIAG,EMS,INV_CHG,UI,xSolarWave

BO_ 2147610664 EmsCktSts: 223 DIAG
 SG_ RsvBits2 : 21|3@1+ (1,0) [0|0] "" DIAG,EMS,INV_CHG,UI,xSolarWave
 SG_ RsvBits1 : 0|2@1+ (1,0) [0|0] "" DIAG,EMS,INV_CHG,UI,xSolarWave
 SG_ Priority : 48|8@1+ (1,0) [0|252] "" DIAG,EMS,INV_CHG,UI,xSolarWave
 SG_ MsgCount : 2|6@1+ (1,0) [0|0] "" DIAG,EMS,INV_CHG,UI,xSolarWave
 SG_ LastLoadShed : 72|16@1+ (0.01,0) [0|655.32] "A" DIAG,EMS,INV_CHG,UI,xSolarWave
 SG_ EnDisSts : 16|2@1+ (1,0) [0|0] "" DIAG,EMS,INV_CHG,UI,xSolarWave
 SG_ DcSrcId : 40|8@1+ (1,0) [0|252] "" DIAG,EMS,INV_CHG,UI,xSolarWave
 SG_ CurrentDraw : 56|16@1+ (0.01,0) [0|655.32] "A" DIAG,EMS,INV_CHG,UI,xSolarWave
 SG_ CircuitId : 8|8@1+ (1,0) [0|252] "" DIAG,EMS,INV_CHG,UI,xSolarWave
 SG_ AssocType : 18|3@1+ (1,0) [0|0] "" DIAG,EMS,INV_CHG,UI,xSolarWave
 SG_ AcSrcId : 32|8@1+ (1,0) [0|252] "" DIAG,EMS,INV_CHG,UI,xSolarWave
 SG_ AcLine : 24|8@1+ (1,0) [0|252] "" DIAG,EMS,INV_CHG,UI,xSolarWave

BO_ 2147573504 EmsCktCfg: 50 DIAG
 SG_ StringId : 24|16@1+ (1,0) [0|65532] "" DIAG,EMS,UI
 SG_ RsvBits2 : 82|6@1+ (1,0) [0|0] "" DIAG,EMS,UI
 SG_ RsvBits1 : 45|3@1+ (1,0) [0|0] "" DIAG,EMS,UI
 SG_ RelayTimeoutMin : 152|16@1+ (1,0) [0|65532] "minutes" DIAG,EMS,UI
 SG_ RelayTimeoutMax : 168|16@1+ (1,0) [0|65532] "minutes" DIAG,EMS,UI
 SG_ RelayTimeout : 136|16@1+ (1,0) [0|65532] "minutes" DIAG,EMS,UI
 SG_ ReconnectMarginMin : 384|8@1+ (1,0) [0|252] "%" DIAG,EMS,UI
 SG_ ReconnectMarginMax : 392|8@1+ (1,0) [0|252] "%" DIAG,EMS,UI
 SG_ ReconnectMargin : 376|8@1+ (1,0) [0|252] "%" DIAG,EMS,UI
 SG_ ReconnectDelayMin : 96|8@1+ (1,0) [0|252] "seconds" DIAG,EMS,UI
 SG_ ReconnectDelayMax : 104|8@1+ (1,0) [0|252] "seconds" DIAG,EMS,UI
 SG_ ReconnectDelay : 88|8@1+ (1,0) [0|252] "seconds" DIAG,EMS,UI
 SG_ Priority : 72|8@1+ (1,0) [0|252] "" DIAG,EMS,UI
 SG_ MsgCount : 2|6@1+ (1,0) [0|0] "" DIAG,EMS,UI
 SG_ GenSoftStart : 80|2@1+ (1,0) [0|0] "" DIAG,EMS,UI
 SG_ EnDisCircuit : 40|2@1+ (1,0) [0|0] "" DIAG,EMS,UI
 SG_ DisconnectDelayMin : 120|8@1+ (1,0) [0|252] "seconds" DIAG,EMS,UI
 SG_ DisconnectDelayMax : 128|8@1+ (1,0) [0|252] "seconds" DIAG,EMS,UI
 SG_ DisconnectDelay : 112|8@1+ (1,0) [0|252] "seconds" DIAG,EMS,UI
 SG_ DcSrcId : 64|8@1+ (1,0) [0|252] "" DIAG,EMS,UI
 SG_ ConcurAccCtr : 8|8@1+ (1,0) [0|252] "" DIAG,EMS,UI
 SG_ CircuitId : 16|8@1+ (1,0) [0|252] "" DIAG,EMS,UI
 SG_ CfgType : 0|2@1+ (1,0) [0|0] "" DIAG,EMS,UI
 SG_ BattLowVTrigSetMin : 200|16@1+ (0.001,0) [0|65.532] "V" DIAG,EMS,UI
 SG_ BattLowVTrigSetMax : 216|16@1+ (0.001,0) [0|65.532] "V" DIAG,EMS,UI
 SG_ BattLowVTrigSet : 184|16@1+ (0.001,0) [0|65.532] "V" DIAG,EMS,UI
 SG_ BattLowVTrigClearMin : 248|16@1+ (0.001,0) [0|65.532] "V" DIAG,EMS,UI
 SG_ BattLowVTrigClearMax : 264|16@1+ (0.001,0) [0|65.532] "V" DIAG,EMS,UI
 SG_ BattLowVTrigClear : 232|16@1+ (0.001,0) [0|65.532] "V" DIAG,EMS,UI
 SG_ BattHighVTrigSetMin : 296|16@1+ (0.001,0) [0|65.532] "V" DIAG,EMS,UI
 SG_ BattHighVTrigSetMax : 312|16@1+ (0.001,0) [0|65.532] "V" DIAG,EMS,UI
 SG_ BattHighVTrigSet : 280|16@1+ (0.001,0) [0|65.532] "V" DIAG,EMS,UI
 SG_ BattHighVTrigClearMin : 344|16@1+ (0.001,0) [0|65.532] "V" DIAG,EMS,UI
 SG_ BattHighVTrigClearMax : 360|16@1+ (0.001,0) [0|65.532] "V" DIAG,EMS,UI
 SG_ BattHighVTrigClear : 328|16@1+ (0.001,0) [0|65.532] "V" DIAG,EMS,UI
 SG_ AssocType : 42|3@1+ (1,0) [0|0] "" DIAG,EMS,UI
 SG_ AcSrcId : 56|8@1+ (1,0) [0|252] "" DIAG,EMS,UI
 SG_ AcLine : 48|8@1+ (1,0) [0|252] "" DIAG,EMS,UI

BO_TX_BU_ 2147554560 : BATTMON,AGS,INV,CHG,UI,INV_CHG,DIAG,GATEWAY,xSolarSurveyor;
BO_TX_BU_ 2147554816 : xSolarWave,BATTMON,AGS,INV,CHG,UI,INV_CHG,DIAG,GATEWAY,xNova,xSolarSurveyor,BMS;
BO_TX_BU_ 2147612688 : xMiata_AGS,xSolarWave,BATTMON,AGS,INV,CHG,UI,INV_CHG,DIAG,GATEWAY,xNova,xSolarSurveyor,EMS,BMS;
BO_TX_BU_ 2147610635 : INV,CHG,INV_CHG,DIAG;
BO_TX_BU_ 2147553536 : INV,CHG,INV_CHG,DIAG;
BO_TX_BU_ 2147553792 : INV,CHG,INV_CHG,DIAG;
BO_TX_BU_ 2147571968 : DIAG,GATEWAY;
BO_TX_BU_ 2147572224 : DIAG,GATEWAY;
BO_TX_BU_ 2147572992 : DIAG,GATEWAY;
BO_TX_BU_ 2147571712 : DIAG,GATEWAY;
BO_TX_BU_ 2147572480 : DIAG,GATEWAY;
BO_TX_BU_ 2147572736 : DIAG,GATEWAY;
BO_TX_BU_ 2147576320 : xSolarWave,UI,DIAG;
BO_TX_BU_ 2147575296 : UI,DIAG,GATEWAY;
BO_TX_BU_ 2147576576 : xSolarWave,UI,DIAG;
BO_TX_BU_ 2147598336 : xSolarWave,UI,DIAG;
BO_TX_BU_ 2147598848 : UI,DIAG;
BO_TX_BU_ 2147574016 : xSolarWave,UI,DIAG;
BO_TX_BU_ 2147567872 : xMiata_AGS,xSolarWave,BATTMON,AGS,INV,CHG,UI,INV_CHG,DIAG,GATEWAY,xNova,xSolarSurveyor,BMS;
BO_TX_BU_ 2147612872 : xSolarWave,BATTMON,AGS,INV,CHG,UI,INV_CHG,DIAG,GATEWAY,xSolarSurveyor,EMS,BMS;
BO_TX_BU_ 2147610643 : xMiata_AGS,BATTMON,AGS,INV,CHG,UI,INV_CHG,DIAG,GATEWAY,xNova;
BO_TX_BU_ 2147610827 : xSolarWave,INV,CHG,INV_CHG,xSolarSurveyor;
BO_TX_BU_ 2147610828 : xSolarWave,INV,CHG,INV_CHG,xSolarSurveyor;
BO_TX_BU_ 2147610636 : xSolarWave,BATTMON,AGS,INV,CHG,UI,INV_CHG,DIAG,xNova;
BO_TX_BU_ 2147610823 : BATTMON,AGS,INV,CHG,UI,INV_CHG;
BO_TX_BU_ 2147554048 : xSolarWave,BATTMON,AGS,INV,CHG,UI,INV_CHG,DIAG,xNova,xSolarSurveyor,BMS;
BO_TX_BU_ 2147554304 : xSolarWave,BATTMON,AGS,INV,CHG,UI,INV_CHG,DIAG,xNova,xSolarSurveyor,BMS;
BO_TX_BU_ 2147598592 : xSolarWave,UI,DIAG;
BO_TX_BU_ 2147562496 : xMiata_AGS,xSolarWave,BATTMON,AGS,INV,CHG,UI,INV_CHG,DIAG,GATEWAY,xNova,xSolarSurveyor,EMS,BMS;
BO_TX_BU_ 2147610663 : DIAG,EMS;
BO_TX_BU_ 2147610664 : DIAG,EMS;
BO_TX_BU_ 2147573504 : UI,DIAG,EMS;
CM_ BO_ 2147554560 "Internal Temperature Configuration - Under Temp";
CM_ SG_ 2147554560 UtLvlMin "Under Temperature Level - Minimum";
CM_ SG_ 2147554560 UtLvlMax "Under Temperature Level - Maximum";
CM_ SG_ 2147554560 UtLvl "Under Temperature Level";
CM_ SG_ 2147554560 UtIntvlMin "Under Temperature Interval - Minimum";
CM_ SG_ 2147554560 UtIntvlMax "Under Temperature Interval - Maximum";
CM_ SG_ 2147554560 UtIntvl "Under Temperature Interval";
CM_ SG_ 2147554560 TempSensId "Temperature Sensor Identifier";
CM_ SG_ 2147554560 RefEvtId "Reference Event Identifier";
CM_ SG_ 2147554560 MsgCount "Message Count";
CM_ SG_ 2147554560 EvtId "Event Identifier";
CM_ SG_ 2147554560 ConcurAccCtr "Concurrent Access Counter";
CM_ SG_ 2147554560 CfgType "Configuration Type";
CM_ BO_ 2147554816 "Internal Temperature Configuration - Over Temp";
CM_ SG_ 2147554816 TempSensId "Temperature Sensor Identifier";
CM_ SG_ 2147554816 RefEvtId "Reference Event Identifier";
CM_ SG_ 2147554816 OtLvlMin "Over Temperature Level - Minimum";
CM_ SG_ 2147554816 OtLvlMax "Over Temperature Level - Maximum";
CM_ SG_ 2147554816 OtLvl "Over Temperature Level";
CM_ SG_ 2147554816 OtIntvlMin "Over Temperature Interval - Minimum";
CM_ SG_ 2147554816 OtIntvlMax "Over Temperature Interval - Maximum";
CM_ SG_ 2147554816 OtIntvl "Over Temperature Interval";
CM_ SG_ 2147554816 MsgCount "Message Count";
CM_ SG_ 2147554816 EvtId "Event Identifier";
CM_ SG_ 2147554816 ConcurAccCtr "Concurrent Access Counter";
CM_ SG_ 2147554816 CfgType "Configuration Type";
CM_ BO_ 2147612688 "Hardware Revision Status";
CM_ SG_ 2147612688 RsvBits2 "Reserved Bits 2";
CM_ SG_ 2147612688 RsvBits1 "Reserved Bits 1";
CM_ SG_ 2147612688 MsgCount "Message Count";
CM_ SG_ 2147612688 ModelNum "Model Number";
CM_ SG_ 2147612688 HwModSerNum "Hardware Module Serial Number";
CM_ SG_ 2147612688 HwModRev "Hardware Module Revision";
CM_ SG_ 2147612688 HwModInst "Hardware Module Instance";
CM_ BO_ 2147610635 "High Voltage DC Bus Status";
CM_ SG_ 2147610635 Voltage "Voltage";
CM_ SG_ 2147610635 RsvBits "Reserved Bits";
CM_ SG_ 2147610635 OutputId "Output Instance";
CM_ SG_ 2147610635 MsgCount "Message Count";
CM_ SG_ 2147610635 Current "Current";
CM_ BO_ 2147553536 "High Voltage DC Bus Configuration - Under Voltage";
CM_ SG_ 2147553536 UvLvlMin "Under Voltage Level - Minimum";
CM_ SG_ 2147553536 UvLvlMax "Under Voltage Level - Maximum";
CM_ SG_ 2147553536 UvLvl "Under Voltage Level";
CM_ SG_ 2147553536 UvIntvlMin "Under Voltage Interval - Minimum";
CM_ SG_ 2147553536 UvIntvlMax "Under Voltage Interval - Maximum";
CM_ SG_ 2147553536 UvIntvl "Under Voltage Interval";
CM_ SG_ 2147553536 RefEvtId "Reference Event Identifier";
CM_ SG_ 2147553536 OutputId "Output Identifier";
CM_ SG_ 2147553536 MsgCount "Message Count";
CM_ SG_ 2147553536 EvtId "Event Identifier";
CM_ SG_ 2147553536 ConcurAccCtr "Concurrent Access Counter";
CM_ SG_ 2147553536 CfgType "Configuration Type";
CM_ BO_ 2147553792 "High Voltage DC Bus Configuration - Over Voltage";
CM_ SG_ 2147553792 RefEvtId "Reference Event Identifier";
CM_ SG_ 2147553792 OvLvlMin "Over Voltage Level - Minimum";
CM_ SG_ 2147553792 OvLvlMax "Over Voltage Level - Maximum";
CM_ SG_ 2147553792 OvLvl "Over Voltage Level";
CM_ SG_ 2147553792 OvIntvlMin "Over Voltage Interval - Minimum";
CM_ SG_ 2147553792 OvIntvlMax "Over Voltage Interval - Maximum";
CM_ SG_ 2147553792 OvIntvl "Over Voltage Interval";
CM_ SG_ 2147553792 OutputId "Output Identifier";
CM_ SG_ 2147553792 MsgCount "Message Count";
CM_ SG_ 2147553792 EvtId "Event Identifier";
CM_ SG_ 2147553792 ConcurAccCtr "Concurrent Access Counter";
CM_ SG_ 2147553792 CfgType "Configuration Type";
CM_ BO_ 2147610660 "Gateway Status";
CM_ SG_ 2147610660 RsvBits "Reserved Bits";
CM_ SG_ 2147610660 OpState "Operating State";
CM_ SG_ 2147610660 MsgCount "Message Count";
CM_ BO_ 2147610661 "Gateway Statistics";
CM_ SG_ 2147610661 RsvBits "Reserved Bits";
CM_ SG_ 2147610661 MsgCount "Message Count";
CM_ BO_ 2147571968 "Gateway Configuration - Message Filters - XanBus I";
CM_ SG_ 2147571968 RsvBits "Reserved Bits";
CM_ SG_ 2147571968 Pgn "PGN";
CM_ SG_ 2147571968 MsgCount "Message Count";
CM_ SG_ 2147571968 ConcurAccCtr "Concurrent Access Counter";
CM_ SG_ 2147571968 CfgType "Configuration Type";
CM_ SG_ 2147571968 AllowedEnDis "Allowed Enable/Disable";
CM_ BO_ 2147572224 "Gateway Configuration - Message Filters - Other In";
CM_ SG_ 2147572224 RsvBits "Reserved Bits";
CM_ SG_ 2147572224 Pgn "PGN";
CM_ SG_ 2147572224 MsgCount "Message Count";
CM_ SG_ 2147572224 ConcurAccCtr "Concurrent Access Counter";
CM_ SG_ 2147572224 CfgType "Configuration Type";
CM_ SG_ 2147572224 AllowedEnDis "Allowed Enable/Disable";
CM_ BO_ 2147572992 "Gateway Configuration - Identifier Translation";
CM_ SG_ 2147572992 XbId "XanBus Identifier";
CM_ SG_ 2147572992 SrcType "Source Type";
CM_ SG_ 2147572992 OthId "Other Identifier";
CM_ SG_ 2147572992 MsgCount "Message Count";
CM_ SG_ 2147572992 ConcurAccCtr "Concurrent Access Counter";
CM_ SG_ 2147572992 CfgType "Configuration Type";
CM_ BO_ 2147571712 "Gateway Configuration - Address Translation - XanB";
CM_ SG_ 2147571712 XbSystemInstance "System Instance (ISO Device Class Instance)";
CM_ SG_ 2147571712 XbDeviceInstanceUpper "Device Instance Upper (ISO Function Instance)";
CM_ SG_ 2147571712 XbDeviceInstanceLower "Device Instance Lower (ISO ECU Instance)";
CM_ SG_ 2147571712 XbDeviceFunction "Device Function (ISO Function)";
CM_ SG_ 2147571712 XbDeviceClass "Device Class";
CM_ SG_ 2147571712 RsvBits4 "Reserved Bits 4";
CM_ SG_ 2147571712 RsvBits3 "Reserved Bits 3";
CM_ SG_ 2147571712 RsvBits2 "Reserved Bits 2";
CM_ SG_ 2147571712 RsvBits1 "Reserved Bits 1";
CM_ SG_ 2147571712 OthSystemInstance "System Instance (ISO Device Class Instance)";
CM_ SG_ 2147571712 OthDeviceInstanceUpper "Device Instance Upper (ISO Function Instance)";
CM_ SG_ 2147571712 OthDeviceInstanceLower "Device Instance Lower (ISO ECU Instance)";
CM_ SG_ 2147571712 OthDeviceFunction "Device Function (ISO Function)";
CM_ SG_ 2147571712 OthDeviceClass "Device Class";
CM_ SG_ 2147571712 MsgCount "Message Count";
CM_ SG_ 2147571712 LoAddr "Lo Address";
CM_ SG_ 2147571712 HiAddr "Hi Address";
CM_ SG_ 2147571712 ConcurAccCtr "Concurrent Access Counter";
CM_ SG_ 2147571712 CfgType "Configuration Type";
CM_ BO_ 2147572480 "Gateway Configuration - Address Translation - Othe";
CM_ SG_ 2147572480 XbSystemInstance "System Instance (ISO Device Class Instance)";
CM_ SG_ 2147572480 XbDeviceInstanceUpper "Device Instance Upper (ISO Function Instance)";
CM_ SG_ 2147572480 XbDeviceInstanceLower "Device Instance Lower (ISO ECU Instance)";
CM_ SG_ 2147572480 XbDeviceFunction "Device Function (ISO Function)";
CM_ SG_ 2147572480 XbDeviceClass "Device Class";
CM_ SG_ 2147572480 RsvBits4 "Reserved Bits 4";
CM_ SG_ 2147572480 RsvBits3 "Reserved Bits 3";
CM_ SG_ 2147572480 RsvBits2 "Reserved Bits 2";
CM_ SG_ 2147572480 RsvBits1 "Reserved Bits 1";
CM_ SG_ 2147572480 OthSystemInstance "System Instance (ISO Device Class Instance)";
CM_ SG_ 2147572480 OthDeviceInstanceUpper "Device Instance Upper (ISO Function Instance)";
CM_ SG_ 2147572480 OthDeviceInstanceLower "Device Instance Lower (ISO ECU Instance)";
CM_ SG_ 2147572480 OthDeviceFunction "Device Function (ISO Function)";
CM_ SG_ 2147572480 OthDeviceClass "Device Class";
CM_ SG_ 2147572480 MsgCount "Message Count";
CM_ SG_ 2147572480 ConcurAccCtr "Concurrent Access Counter";
CM_ SG_ 2147572480 CfgType "Configuration Type";
CM_ BO_ 2147572736 "Gateway Configuration";
CM_ SG_ 2147572736 MsgCount "Message Count";
CM_ SG_ 2147572736 Mode "Gateway Mode";
CM_ SG_ 2147572736 ConcurAccCtr "Concurrent Access Counter";
CM_ SG_ 2147572736 CfgType "Configuration Type";
CM_ BO_ 2147576320 "Grid Voltage Support Configuration";
CM_ SG_ 2147576320 VThresholdMin "Voltage Threshold to start/stop excitation - Minimum";
CM_ SG_ 2147576320 VThresholdMax "Voltage Threshold to start/stop excitation - Maximum";
CM_ SG_ 2147576320 VThreshold "Voltage Threshold to start/stop excitation";
CM_ SG_ 2147576320 VSetLowMin "Capacitive Voltage Set Point - Minimum";
CM_ SG_ 2147576320 VSetLowMax "Capacitive Voltage Set Point - Maximum";
CM_ SG_ 2147576320 VSetLow "Capacitive Voltage Set Point";
CM_ SG_ 2147576320 VSetHighMin "Inductive Voltage Set Point - Minimum";
CM_ SG_ 2147576320 VSetHighMax "Inductive Voltage Set Point - Maximum";
CM_ SG_ 2147576320 VSetHigh "Inductive Voltage Set Point";
CM_ SG_ 2147576320 RsvBits "Reserved Bits";
CM_ SG_ 2147576320 MsgCount "Message Count";
CM_ SG_ 2147576320 MinVGridMin "Minimum Reactive Power Grid Voltage - Minimum";
CM_ SG_ 2147576320 MinVGridMax "Minimum Reactive Power Grid Voltage - Maximum";
CM_ SG_ 2147576320 MinVGrid "Minimum Reactive Power Grid Voltage";
CM_ SG_ 2147576320 MaxVGridMin "Maximum Reactive Power Grid Voltage - Minimum";
CM_ SG_ 2147576320 MaxVGridMax "Maximum Reactive Power Grid Voltage - Maximum";
CM_ SG_ 2147576320 MaxVGrid "Maximum Reactive Power Grid Voltage";
CM_ SG_ 2147576320 MaxQIndMin "Maximum Reactive Inductive Power - Minimum";
CM_ SG_ 2147576320 MaxQIndMax "Maximum Reactive Inductive Power - Maximum";
CM_ SG_ 2147576320 MaxQInd "Maximum Reactive Inductive Power";
CM_ SG_ 2147576320 MaxQCapMin "Maximum Reactive Capacitive Power - Minimum";
CM_ SG_ 2147576320 MaxQCapMax "Maximum Reactive Capacitive Power - Maximum";
CM_ SG_ 2147576320 MaxQCap "Maximum Reactive Capacitive Power";
CM_ SG_ 2147576320 GvsEnDis "GVS Enable/Disable";
CM_ SG_ 2147576320 DelayTimeMin "Excitation Control Delay Time - Minimum";
CM_ SG_ 2147576320 DelayTimeMax "Excitation Control Delay Time - Maximum";
CM_ SG_ 2147576320 DelayTime "Excitation Control Delay Time";
CM_ SG_ 2147576320 ConcurAccCtr "Concurrent Access Counter";
CM_ SG_ 2147576320 CfgType "Configuration Type";
CM_ SG_ 2147576320 AcSrcId "AC Source Identifer";
CM_ BO_ 2147575296 "Grid Tie Control Command";
CM_ SG_ 2147575296 MaxSellScalePrcnt "Maximum Sell Scale Percentage";
CM_ SG_ 2147575296 AcSrcId "AC Source Identifier";
CM_ BO_ 2147576576 "Grid Tie Configuration - Battery SOC";
CM_ SG_ 2147576576 TimeIntStopMin "Time Interval to Stop - Min";
CM_ SG_ 2147576576 TimeIntStopMax "Time Interval to Stop - Max";
CM_ SG_ 2147576576 TimeIntStop "Time Interval to Stop";
CM_ SG_ 2147576576 TimeIntStartMin "Time Interval to Start - Min";
CM_ SG_ 2147576576 TimeIntStartMax "Time Interval to Start - Max";
CM_ SG_ 2147576576 TimeIntStart "Time Interval to Start";
CM_ SG_ 2147576576 SocLvlStopMin "State of Charge Level to Stop - Min";
CM_ SG_ 2147576576 SocLvlStopMax "State of Charge Level to Stop - Max";
CM_ SG_ 2147576576 SocLvlStop "State of Charge Level to Stop";
CM_ SG_ 2147576576 SocLvlStartMin "State of Charge Level to Start - Min";
CM_ SG_ 2147576576 SocLvlStartMax "State of Charge Level to Start - Max";
CM_ SG_ 2147576576 SocLvlStart "State of Charge Level to Start";
CM_ SG_ 2147576576 RsvBits "Reserved Bits";
CM_ SG_ 2147576576 MsgCount "Message Count";
CM_ SG_ 2147576576 GridTieSocEnDis "Grid Tie State of Charge Enable/Disable";
CM_ SG_ 2147576576 ConcurAccCtr "Concurrent Access Counter";
CM_ SG_ 2147576576 CfgType "Configuration Type";
CM_ SG_ 2147576576 AcSrcId "AC Source Identifer";
CM_ BO_ 2147598336 "Grid Tie Configuration";
CM_ SG_ 2147598336 SellMode "Grid-Tie Sell Mode";
CM_ SG_ 2147598336 SellDuration "Grid Tie Sell Duration";
CM_ SG_ 2147598336 RsvBits "Reserved Bits";
CM_ SG_ 2147598336 PeakLoadShavingIMin "Peak Load Shaving Current Minimum";
CM_ SG_ 2147598336 PeakLoadShavingIMax "Peak Load Shaving Current Maximum";
CM_ SG_ 2147598336 PeakLoadShavingI "Peak Load Shaving Current";
CM_ SG_ 2147598336 PeakLoadShavingEnDis "Peak Load Shaving Enable/Disable";
CM_ SG_ 2147598336 MsgCount "Message Count";
CM_ SG_ 2147598336 MaxSellScalePrcnt "Maximum Sell Scale Percentage";
CM_ SG_ 2147598336 MaxSellIMin "Max Sell Current Minimum";
CM_ SG_ 2147598336 MaxSellIMax "Max Sell Current Maximum";
CM_ SG_ 2147598336 MaxSellI "Max Sell Current";
CM_ SG_ 2147598336 GridTieEnDis "Grid Tie Enable/Disable";
CM_ SG_ 2147598336 ConcurAccCtr "Concurrent Access Counter";
CM_ SG_ 2147598336 CfgType "Configuration Type";
CM_ SG_ 2147598336 AntiIslandingEnDis "AntiIslanding Enable/Disable";
CM_ SG_ 2147598336 AIReconnect "Anti Islanding Reconnect";
CM_ SG_ 2147598336 AIDisconUvLNSlow "Anti Islanding Disconnect Under Voltage LN Slow";
CM_ SG_ 2147598336 AIDisconUvLNFast "Anti Islanding Disconnect Under Voltage LN Fast";
CM_ SG_ 2147598336 AIDisconUvL1L2Slow "Anti Islanding Disconnect Under Voltage L1L2 Slow";
CM_ SG_ 2147598336 AIDisconUvL1L2Fast "Anti Islanding Disconnect Under Voltage L1L2 Fast";
CM_ SG_ 2147598336 AIDisconUf "Anti Islanding Disconnect Under Frequency";
CM_ SG_ 2147598336 AIDisconSlowDelay "Anti Islanding Disconnect Slow Delay";
CM_ SG_ 2147598336 AIDisconOvLNSlow "Anti Islanding Disconnect Over Voltage LN Slow";
CM_ SG_ 2147598336 AIDisconOvLNFast "Anti Islanding Disconnect Over Voltage LN Fast";
CM_ SG_ 2147598336 AIDisconOvL1L2Slow "Anti Islanding Disconnect Over Voltage L1L2 Slow";
CM_ SG_ 2147598336 AIDisconOvL1L2Fast "Anti Islanding Disconnect Over Voltage L1L2 Fast";
CM_ SG_ 2147598336 AIDisconOf "Anti Islanding Disconnect Over Frequency";
CM_ SG_ 2147598336 AcSrcId "AC Source Identifer";
CM_ BO_ 2147598848 "Go Configure Yourself Command";
CM_ SG_ 2147598848 SrcAddr "Source Address";
CM_ SG_ 2147598848 DcSrcId "DC Source Identifier";
CM_ SG_ 2147598848 AcSrcId "AC Source Identifier";
CM_ BO_ 2147574016 "Grid Frequency Stabilization Configuration";
CM_ SG_ 2147574016 RsvBits "Reserved Bits";
CM_ SG_ 2147574016 MsgCount "Message Count";
CM_ SG_ 2147574016 GfsEnDis "GFS Enable/Disable";
CM_ SG_ 2147574016 ConcurAccCtr "Concurrent Access Counter";
CM_ SG_ 2147574016 CfgType "Configuration Type";
CM_ SG_ 2147574016 AprPtGradientMin "APR Active Power Gradient with Time - Minimum";
CM_ SG_ 2147574016 AprPtGradientMax "APR Active Power Gradient with Time - Maximum";
CM_ SG_ 2147574016 AprPtGradient "APR Active Power Gradient with Time";
CM_ SG_ 2147574016 AprPfGradientMin "APR Active Power Gradient with Frequency - Minimum";
CM_ SG_ 2147574016 AprPfGradientMax "APR Active Power Gradient with Frequency - Maximum";
CM_ SG_ 2147574016 AprPfGradient "APR Active Power Gradient with Frequency";
CM_ SG_ 2147574016 AprFreqStopLvlMin "APR Frequency Stop Level - Minimum";
CM_ SG_ 2147574016 AprFreqStopLvlMax "APR Frequency Stop Level - Maximum";
CM_ SG_ 2147574016 AprFreqStopLvl "APR Frequency Stop Level";
CM_ SG_ 2147574016 AprFreqStartLvlMin "APR Frequency Start Level - Minimum";
CM_ SG_ 2147574016 AprFreqStartLvlMax "APR Frequency Start Level - Maximum";
CM_ SG_ 2147574016 AprFreqStartLvl "APR Frequency Start Level";
CM_ SG_ 2147574016 AprFreqRecoverLvlMin "APR Frequency Recover Level - Minimum";
CM_ SG_ 2147574016 AprFreqRecoverLvlMax "APR Frequency Recover Level - Maximum";
CM_ SG_ 2147574016 AprFreqRecoverLvl "APR Frequency Recover Level";
CM_ SG_ 2147574016 ApiPtGradientMin "API Active Power Gradient with Time - Minimum";
CM_ SG_ 2147574016 ApiPtGradientMax "API Active Power Gradient with Time - Maximum";
CM_ SG_ 2147574016 ApiPtGradient "API Active Power Gradient with Time";
CM_ SG_ 2147574016 ApiFreqStopLvlMin "API Frequency Stop Level - Minimum";
CM_ SG_ 2147574016 ApiFreqStopLvlMax "API Frequency Stop Level - Maximum";
CM_ SG_ 2147574016 ApiFreqStopLvl "API Frequency Stop Level";
CM_ SG_ 2147574016 ApiFreqStartLvlMin "API Frequency Start Level - Minimum";
CM_ SG_ 2147574016 ApiFreqStartLvlMax "API Frequency Start Level - Maximum";
CM_ SG_ 2147574016 ApiFreqStartLvl "API Frequency Start Level";
CM_ SG_ 2147574016 ApiFreqRecoverLvlMin "API Frequency Recover Level - Minimum";
CM_ SG_ 2147574016 ApiFreqRecoverLvlMax "API Frequency Recover Level - Maximum";
CM_ SG_ 2147574016 ApiFreqRecoverLvl "API Frequency Recover Level";
CM_ SG_ 2147574016 AcSrcId "AC Source Identifer";
CM_ BO_ 2147564288 "File Download Status";
CM_ SG_ 2147564288 RsvBits "Reserved Bits";
CM_ SG_ 2147564288 ResultCode "Result Code";
CM_ SG_ 2147564288 ProcessorInst "Controller Instance";
CM_ SG_ 2147564288 OpState "Operating State";
CM_ SG_ 2147564288 ModelNum "Model Number";
CM_ SG_ 2147564288 HwModRev "Hardware Module Revision";
CM_ SG_ 2147564288 BlkNum "Block Number";
CM_ BO_ 2147561984 "File Download Information";
CM_ SG_ 2147561984 SwVer "Software Version";
CM_ SG_ 2147561984 SwModId "Software Module Identifier";
CM_ SG_ 2147561984 RsvBits "Reserved Bits";
CM_ SG_ 2147561984 ProcessorInst "Controller Instance";
CM_ SG_ 2147561984 FileSz "File Size";
CM_ SG_ 2147561984 ExpectNumBlks "Expected Number of Blocks";
CM_ SG_ 2147561984 DeviceFunction "Device Function";
CM_ SG_ 2147561984 Crc "CRC";
CM_ BO_ 2147561728 "File Download Block";
CM_ SG_ 2147561728 BlkSz "Block Size";
CM_ SG_ 2147561728 BlkNum "Block Number";
CM_ SG_ 2147561728 BlkData "Block Data";
CM_ BO_ 2147567872 "Feature Enable/Disable Configuration";
CM_ SG_ 2147567872 RsvBits "Reserved Bits";
CM_ SG_ 2147567872 MsgCount "Message Count";
CM_ SG_ 2147567872 FeatureName "Feature Name String";
CM_ SG_ 2147567872 FeatureId "Feature Identifier";
CM_ SG_ 2147567872 FeatureEnDis "Feature Enable/Disable";
CM_ SG_ 2147567872 ConcurAccCtr "Concurrent Access Counter";
CM_ SG_ 2147567872 CfgType "Configuration Type";
CM_ BO_ 2147612872 "Fault Log Status (Deux)";
CM_ SG_ 2147612872 StringId "String Identifier";
CM_ SG_ 2147612872 RsvBits "Reserved Bits";
CM_ SG_ 2147612872 MsgCount "Message Count";
CM_ SG_ 2147612872 FaultType "Fault Type";
CM_ SG_ 2147612872 FaultTime "Fault Time";
CM_ SG_ 2147612872 FaultId "Fault Identifier";
CM_ BO_ 2147610643 "Fault Log Status";
CM_ SG_ 2147610643 RsvBits "Reserved Bits";
CM_ SG_ 2147610643 MsgCount "Message Count";
CM_ SG_ 2147610643 FaultType "Fault Type";
CM_ SG_ 2147610643 FaultTime "Fault Time";
CM_ SG_ 2147610643 FaultId "Fault Identifier";
CM_ BO_ 2147610827 "Fan Status";
CM_ SG_ 2147610827 RsvBits "Reserved Bits";
CM_ SG_ 2147610827 MsgCount "Messgae Count";
CM_ SG_ 2147610827 FanSpeed "Fan Speed";
CM_ SG_ 2147610827 FanId "Fan Identifier";
CM_ BO_ 2147610828 "Fan Statistics";
CM_ SG_ 2147610828 RsvBits "Reserved Bits";
CM_ SG_ 2147610828 MsgCount "Message Count";
CM_ SG_ 2147610828 FanRunTimeMin "Fan Run Time in minute";
CM_ SG_ 2147610828 FanId "Fan Identifier";
CM_ BO_ 2147610636 "External Temperature Status";
CM_ SG_ 2147610636 TempSensId "Temperature Sensor Identifier";
CM_ SG_ 2147610636 Temp "Temperature";
CM_ SG_ 2147610636 RsvBits "Reserved Bits";
CM_ SG_ 2147610636 MsgCount "Message Count";
CM_ BO_ 2147610823 "External Temperature Statistics (Deux)";
CM_ SG_ 2147610823 TempSensId "Temperature Sensor Identifier";
CM_ SG_ 2147610823 TempMin "Temperature Minimum";
CM_ SG_ 2147610823 TempMax "Temperature Maximum";
CM_ SG_ 2147610823 RsvBits "Reserved Bits";
CM_ SG_ 2147610823 PreviousPeriodCount "Previous Period Count";
CM_ SG_ 2147610823 PreviousPeriod "Previous Period";
CM_ SG_ 2147610823 MsgCount "Message Count";
CM_ BO_ 2147554048 "External Temperature Configuration - Under Temp";
CM_ SG_ 2147554048 UtLvlMin "Under Temperature Level - Minimum";
CM_ SG_ 2147554048 UtLvlMax "Under Temperature Level - Maximum";
CM_ SG_ 2147554048 UtLvl "Under Temperature Level";
CM_ SG_ 2147554048 UtIntvlMin "Under Temperature Interval - Minimum";
CM_ SG_ 2147554048 UtIntvlMax "Under Temperature Interval - Maximum";
CM_ SG_ 2147554048 UtIntvl "Under Temperature Interval";
CM_ SG_ 2147554048 TempSensId "Temperature Sensor Identifier";
CM_ SG_ 2147554048 RefEvtId "Reference Event Identifier";
CM_ SG_ 2147554048 MsgCount "Message Count";
CM_ SG_ 2147554048 EvtId "Event Identifier";
CM_ SG_ 2147554048 ConcurAccCtr "Concurrent Access Counter";
CM_ SG_ 2147554048 CfgType "Configuration Type";
CM_ BO_ 2147554304 "External Temperature Configuration - Over Temp";
CM_ SG_ 2147554304 TempSensId "Temperature Sensor Identifier";
CM_ SG_ 2147554304 RefEvtId "Reference Event Identifier";
CM_ SG_ 2147554304 OtLvlMin "Over Temperature Level - Minimum";
CM_ SG_ 2147554304 OtLvlMax "Over Temperature Level - Maximum";
CM_ SG_ 2147554304 OtLvl "Over Temperature Level";
CM_ SG_ 2147554304 OtIntvlMin "Over Temperature Interval - Minimum";
CM_ SG_ 2147554304 OtIntvlMax "Over Temperature Interval - Maximum";
CM_ SG_ 2147554304 OtIntvl "Over Temperature Interval";
CM_ SG_ 2147554304 MsgCount "Message Count";
CM_ SG_ 2147554304 EvtId "Event Identifier";
CM_ SG_ 2147554304 ConcurAccCtr "Concurrent Access Counter";
CM_ SG_ 2147554304 CfgType "Configuration Type";
CM_ BO_ 2147598592 "Enable/Disable Configuration - Time-of-Day";
CM_ SG_ 2147598592 TodEnd "Period End";
CM_ SG_ 2147598592 TodBeg "Period Begin";
CM_ SG_ 2147598592 MsgCount "Message Count";
CM_ SG_ 2147598592 FeatureOverride "Feature Override";
CM_ SG_ 2147598592 EvtDowMask "Event Day-of-Week Mask";
CM_ SG_ 2147598592 ConcurAccCtr "Concurrent Access Counter";
CM_ SG_ 2147598592 CfgType "Configuration Type";
CM_ BO_ 2147562496 "Enable/Disable Configuration";
CM_ SG_ 2147562496 RsvBits "Reserved Bits";
CM_ SG_ 2147562496 PerTxEnDis "Periodic Transmit Enable/Disable";
CM_ SG_ 2147562496 MsgCount "Message Count";
CM_ SG_ 2147562496 IdentEnDis "Identify Enable/Disable";
CM_ SG_ 2147562496 ConcurAccCtr "Concurrent Access Counter";
CM_ SG_ 2147562496 CfgType "Configuration Type";
CM_ BO_ 2147610663 "EMS Status";
CM_ SG_ 2147610663 RsvBits2 "Reserved Bits 2";
CM_ SG_ 2147610663 RsvBits1 "Reserved Bits 1";
CM_ SG_ 2147610663 RequestAcDisqualify "AC Disqualify Request";
CM_ SG_ 2147610663 MsgCount "Message Count";
CM_ SG_ 2147610663 AvailableCapacity "Available Capacity";
CM_ SG_ 2147610663 AcSrcType "AC Source Type";
CM_ SG_ 2147610663 AcLine "AC Line";
CM_ BO_ 2147610664 "EMS Circuit Status";
CM_ SG_ 2147610664 RsvBits2 "Reserved Bits 2";
CM_ SG_ 2147610664 RsvBits1 "Reserved Bits 1";
CM_ SG_ 2147610664 Priority "Priority";
CM_ SG_ 2147610664 MsgCount "Message Count";
CM_ SG_ 2147610664 LastLoadShed "Last Load Shed";
CM_ SG_ 2147610664 EnDisSts "Enable/Disable Status";
CM_ SG_ 2147610664 DcSrcId "DC Source Identifier";
CM_ SG_ 2147610664 CurrentDraw "Current Draw";
CM_ SG_ 2147610664 CircuitId "Circuit Identifier";
CM_ SG_ 2147610664 AssocType "Association Type";
CM_ SG_ 2147610664 AcSrcId "AC Source Identifier";
CM_ SG_ 2147610664 AcLine "AC Line";
CM_ BO_ 2147573504 "EMS Circuit Configuration";
CM_ SG_ 2147573504 StringId "String Identifier";
CM_ SG_ 2147573504 RsvBits2 "Reserved Bits 2";
CM_ SG_ 2147573504 RsvBits1 "Reserved Bits 1";
CM_ SG_ 2147573504 RelayTimeoutMin "Relay Timeout - Minimum";
CM_ SG_ 2147573504 RelayTimeoutMax "Relay Timeout - Maximum";
CM_ SG_ 2147573504 RelayTimeout "Relay Timeout";
CM_ SG_ 2147573504 ReconnectMarginMin "Reconnect Margin - Minimum";
CM_ SG_ 2147573504 ReconnectMarginMax "Reconnect Margin - Maximum";
CM_ SG_ 2147573504 ReconnectMargin "Reconnect Margin";
CM_ SG_ 2147573504 ReconnectDelayMin "Reconnect Delay - Minimum";
CM_ SG_ 2147573504 ReconnectDelayMax "Reconnect Delay - Maximum";
CM_ SG_ 2147573504 ReconnectDelay "Reconnect Delay";
CM_ SG_ 2147573504 Priority "Priority";
CM_ SG_ 2147573504 MsgCount "Message Count";
CM_ SG_ 2147573504 GenSoftStart "Generator Soft Start";
CM_ SG_ 2147573504 EnDisCircuit "Enable/Disable Circuit";
CM_ SG_ 2147573504 DisconnectDelayMin "Disconnect Delay - Minimum";
CM_ SG_ 2147573504 DisconnectDelayMax "Disconnect Delay - Maximum";
CM_ SG_ 2147573504 DisconnectDelay "Disconnect Delay";
CM_ SG_ 2147573504 DcSrcId "DC Source Identifier";
CM_ SG_ 2147573504 ConcurAccCtr "Concurrent Access Counter";
CM_ SG_ 2147573504 CircuitId "Circuit Identifier";
CM_ SG_ 2147573504 CfgType "Configuration Type";
CM_ SG_ 2147573504 BattLowVTrigSetMin "Battery Low Voltage Trigger Set - Minimum";
CM_ SG_ 2147573504 BattLowVTrigSetMax "Battery Low Voltage Trigger Set - Maximum";
CM_ SG_ 2147573504 BattLowVTrigSet "Battery Low Voltage Trigger Set";
CM_ SG_ 2147573504 BattLowVTrigClearMin "Battery Low Voltage Trigger Clear - Minimum";
CM_ SG_ 2147573504 BattLowVTrigClearMax "Battery Low Voltage Trigger Clear - Maximum";
CM_ SG_ 2147573504 BattLowVTrigClear "Battery Low Voltage Trigger Clear";
CM_ SG_ 2147573504 BattHighVTrigSetMin "Battery High Voltage Trigger Set - Minimum";
CM_ SG_ 2147573504 BattHighVTrigSetMax "Battery High Voltage Trigger Set - Maximum";
CM_ SG_ 2147573504 BattHighVTrigSet "Battery High Voltage Trigger Set";
CM_ SG_ 2147573504 BattHighVTrigClearMin "Battery High Voltage Trigger Clear - Minimum";
CM_ SG_ 2147573504 BattHighVTrigClearMax "Battery High Voltage Trigger Clear - Maximum";
CM_ SG_ 2147573504 BattHighVTrigClear "Battery High Voltage Trigger Clear";
CM_ SG_ 2147573504 AssocType "Association Type";
CM_ SG_ 2147573504 AcSrcId "AC Source Identifier";
CM_ SG_ 2147573504 AcLine "AC Line";
BA_DEF_ BO_  "J1939PGPrio" INT 0 7;
BA_DEF_ BO_  "J1939PGR1" INT 0 1;
BA_DEF_ BO_  "J1939PGDest" INT 0 255;
BA_DEF_ BO_  "J1939PGSrc" INT 0 255;
BA_DEF_ BO_  "CycleTime" INT 5 1000;
BA_DEF_ BO_  "SingleFrame" INT 0 1;
BA_DEF_DEF_  "J1939PGPrio" 0;
BA_DEF_DEF_  "J1939PGR1" 0;
BA_DEF_DEF_  "J1939PGDest" 0;
BA_DEF_DEF_  "J1939PGSrc" 0;
BA_DEF_DEF_  "CycleTime" 100;
BA_DEF_DEF_  "SingleFrame" 0;
BA_ "J1939PGPrio" BO_ 2147554560 6;
BA_ "J1939PGDest" BO_ 2147554560 255;
BA_ "J1939PGPrio" BO_ 2147554816 6;
BA_ "J1939PGDest" BO_ 2147554816 255;
BA_ "J1939PGPrio" BO_ 2147612688 6;
BA_ "J1939PGDest" BO_ 2147612688 255;
BA_ "J1939PGPrio" BO_ 2147610635 6;
BA_ "J1939PGDest" BO_ 2147610635 255;
BA_ "J1939PGPrio" BO_ 2147553536 6;
BA_ "J1939PGDest" BO_ 2147553536 255;
BA_ "J1939PGPrio" BO_ 2147553792 6;
BA_ "J1939PGDest" BO_ 2147553792 255;
BA_ "J1939PGPrio" BO_ 2147610660 6;
BA_ "J1939PGDest" BO_ 2147610660 255;
BA_ "CycleTime" BO_ 2147610660 500;
BA_ "SingleFrame" BO_ 2147610660 1;
BA_ "J1939PGPrio" BO_ 2147610661 6;
BA_ "J1939PGDest" BO_ 2147610661 255;
BA_ "SingleFrame" BO_ 2147610661 1;
BA_ "J1939PGPrio" BO_ 2147571968 6;
BA_ "J1939PGDest" BO_ 2147571968 255;
BA_ "J1939PGPrio" BO_ 2147572224 6;
BA_ "J1939PGDest" BO_ 2147572224 255;
BA_ "J1939PGPrio" BO_ 2147572992 6;
BA_ "J1939PGDest" BO_ 2147572992 255;
BA_ "J1939PGPrio" BO_ 2147571712 6;
BA_ "J1939PGDest" BO_ 2147571712 255;
BA_ "J1939PGPrio" BO_ 2147572480 6;
BA_ "J1939PGDest" BO_ 2147572480 255;
BA_ "J1939PGPrio" BO_ 2147572736 6;
BA_ "J1939PGDest" BO_ 2147572736 255;
BA_ "SingleFrame" BO_ 2147572736 1;
BA_ "J1939PGPrio" BO_ 2147576320 6;
BA_ "J1939PGDest" BO_ 2147576320 255;
BA_ "CycleTime" BO_ 2147576320 5;
BA_ "J1939PGPrio" BO_ 2147575296 6;
BA_ "J1939PGDest" BO_ 2147575296 255;
BA_ "CycleTime" BO_ 2147575296 5;
BA_ "J1939PGPrio" BO_ 2147576576 6;
BA_ "J1939PGDest" BO_ 2147576576 255;
BA_ "CycleTime" BO_ 2147576576 5;
BA_ "J1939PGPrio" BO_ 2147598336 6;
BA_ "J1939PGDest" BO_ 2147598336 255;
BA_ "J1939PGPrio" BO_ 2147598848 6;
BA_ "J1939PGDest" BO_ 2147598848 255;
BA_ "SingleFrame" BO_ 2147598848 1;
BA_ "J1939PGPrio" BO_ 2147574016 6;
BA_ "J1939PGDest" BO_ 2147574016 255;
BA_ "CycleTime" BO_ 2147574016 5;
BA_ "J1939PGPrio" BO_ 2147564288 6;
BA_ "J1939PGDest" BO_ 2147564288 255;
BA_ "CycleTime" BO_ 2147564288 1000;
BA_ "SingleFrame" BO_ 2147564288 1;
BA_ "J1939PGPrio" BO_ 2147561984 6;
BA_ "J1939PGDest" BO_ 2147561984 255;
BA_ "J1939PGPrio" BO_ 2147561728 6;
BA_ "J1939PGDest" BO_ 2147561728 255;
BA_ "SingleFrame" BO_ 2147561728 1;
BA_ "J1939PGPrio" BO_ 2147567872 6;
BA_ "J1939PGDest" BO_ 2147567872 255;
BA_ "J1939PGPrio" BO_ 2147612872 6;
BA_ "J1939PGDest" BO_ 2147612872 255;
BA_ "J1939PGPrio" BO_ 2147610643 6;
BA_ "J1939PGDest" BO_ 2147610643 255;
BA_ "J1939PGPrio" BO_ 2147610827 6;
BA_ "J1939PGDest" BO_ 2147610827 255;
BA_ "CycleTime" BO_ 2147610827 5;
BA_ "J1939PGPrio" BO_ 2147610828 6;
BA_ "J1939PGDest" BO_ 2147610828 255;
BA_ "CycleTime" BO_ 2147610828 5;
BA_ "J1939PGPrio" BO_ 2147610636 6;
BA_ "J1939PGDest" BO_ 2147610636 255;
BA_ "SingleFrame" BO_ 2147610636 1;
BA_ "J1939PGPrio" BO_ 2147610823 6;
BA_ "J1939PGDest" BO_ 2147610823 255;
BA_ "J1939PGPrio" BO_ 2147554048 6;
BA_ "J1939PGDest" BO_ 2147554048 255;
BA_ "J1939PGPrio" BO_ 2147554304 6;
BA_ "J1939PGDest" BO_ 2147554304 255;
BA_ "J1939PGPrio" BO_ 2147598592 6;
BA_ "J1939PGDest" BO_ 2147598592 255;
BA_ "J1939PGPrio" BO_ 2147562496 6;
BA_ "J1939PGDest" BO_ 2147562496 255;
BA_ "SingleFrame" BO_ 2147562496 1;
BA_ "J1939PGPrio" BO_ 2147610663 6;
BA_ "J1939PGDest" BO_ 2147610663 255;
BA_ "CycleTime" BO_ 2147610663 500;
BA_ "J1939PGPrio" BO_ 2147610664 6;
BA_ "J1939PGDest" BO_ 2147610664 255;
BA_ "CycleTime" BO_ 2147610664 500;
BA_ "J1939PGPrio" BO_ 2147573504 6;
BA_ "J1939PGDest" BO_ 2147573504 255;
VAL_ 2147554560 TempSensId 0 "Transistor 1" 1 "Transistor 2" 2 "Transistor 3" 3 "Transistor 4" 10 "Capacitor 1" 11 "Capacitor 2" 12 "Capacitor 3" 13 "Capacitor 4" 20 "Transformer 1" 21 "Transformer 2" 22 "Transformer 3" 23 "Transformer 4" 30 "Ambient 1" 31 "Ambient 2" 32 "Ambient 3" 33 "Ambient 4" 34 "Shunt 1" 35 "Shunt 2" 36 "Shunt 3" 37 "Shunt 4" 38 "Heatsink 1" 39 "Heatsink 2" 40 "Heatsink 3" 41 "Heatsink 4" 253 "Reserved" 254 "Out of Range" 255 "Data Not Available Do Not Change" ;
VAL_ 2147554560 RefEvtId 436 "SPS Auto Off Array V Low" 437 "SPS Auto On Array V Low" 438 "SPS Auto Off Ground Flt" 439 "SPS Auto On Ground Flt" 440 "SPS Auto Off External Shutdown Flt" 0 "None" 10 "Control Command Hibernate" 11 "Control Command Safe" 12 "Control Command Power Save" 13 "Control Command Operating" 14 "Control Command Diagnostic" 15 "Control Command Last Mode" 20 "Reset Command Reboot" 21 "Reset Command Download" 22 "Reset Command Oem" 23 "Reset Command Factory" 24 "Reset Command Reboot Clear Nv" 25 "Powered Up" 30 "Clear Command Active Faults" 31 "Clear Command Fault Log" 32 "Clear Command Active Warns" 33 "Clear Command Warn Log" 34 "Clear Command State Event Log" 35 "Clear Command Comm Stats" 36 "Clear Command Stats" 37 "Clear Command All" 40 "Date Time Configured" 50 "Warn Cleared" 51 "Fault Cleared" 52 "Fault Set" 60 "User Cfg Changed" 61 "Oem Cfg Changed" 70 "Triggered Fault" 250 "Shutdown Threshold" 251 "Shutdown Hysteresis" 252 "Warning Threshold" 253 "Warning Hysteresis" 254 "Transfer Threshold" 255 "Fan 0 Threshold" 256 "Fan 10 Threshold" 257 "Fan 20 Threshold" 258 "Fan 30 Threshold" 259 "Fan 40 Threshold" 260 "Fan 50 Threshold" 261 "Fan 60 Threshold" 262 "Fan 70 Threshold" 263 "Fan 80 Threshold" 264 "Fan 90 Threshold" 265 "Fan 100 Threshold" 266 "Relay Open Threshold" 267 "Relay Close Threshold" 268 "Charger Derating Ac In V" 269 "Charger Derating Ac In I" 270 "Charger Derating Ext Temp" 271 "Charger Derating Int Temp" 272 "Charger Derating Ripple V" 273 "Lost Ac Threshold" 274 "Lost Ac Hysteresis" 275 "Imm Shutdown Threshold" 276 "Imm Shutdown Hysteresis" 277 "Charger Shutdown Threshold" 278 "Charger Shutdown Hysteresis" 279 "Charger Warning Threshold" 280 "Charger Warning Hysteresis" 281 "Inverter Shutdown Threshold" 282 "Inverter Shutdown Hysteresis" 283 "Inverter Warning Threshold" 284 "Inverter Warning Hysteresis" 285 "Charger Derating Temp Start Point" 286 "Charger Derating Temp End Point" 287 "Charger Recharge Threshold" 300 "Ags Exercise Start" 301 "Ags Exercise Stop" 302 "Ags Quiet Time Begin" 303 "Ags Quiet Time End" 304 "Ags Battery Soc Start" 305 "Ags Battery Soc Stop" 306 "Ags Dc V Start" 307 "Ags Dc V Stop" 308 "Ags Ac I Start" 309 "Ags Ac I Stop" 310 "Ags Contact Start" 311 "Ags Contact Stop" 312 "Ags Float Stop" 313 "Ags Absorp Stop" 314 "Ags Manual On" 315 "Ags Manual Off" 316 "Ags Auto" 317 "Ags External On" 318 "Ags External Off" 319 "Gen External On" 320 "Gen External Off" 321 "Ags External Shutdown" 322 "Ags Auto Off" 323 "Ags Dc I Start" 324 "Ags Dc I Stop" 325 "Ags Ac Power Start" 326 "Ags Ac Power Stop" 400 "Sps Manual Off" 401 "Sps Manual On" 410 "Sps Auto Off" 411 "Sps Auto On" 420 "Sps Auto Off Batt V Low" 421 "Sps Auto On Batt V Low" 422 "Sps Auto Off Batt V High" 423 "Sps Auto On Batt V High" 424 "Sps Auto Off Array V High" 425 "Sps Auto On Array V High" 426 "Sps Auto Off Batt Temp Low" 427 "Sps Auto On Batt Temp Low" 428 "Sps Auto Off Batt Temp High" 429 "Sps Auto On Batt Temp High" 430 "Sps Auto Off Heat Sink Temp High" 431 "Sps Auto On Heat Sink Temp High" 432 "Sps Auto Off Fault" 433 "Sps Auto On Fault" 434 "Aps Check Timeout" 435 "Aps Qualify Timeout" 512 "Resume From Safe" 513 "AC Fault Set" 514 "Invert Fault Set" 515 "Charge Fault Set" 516 "Charger Enable" 517 "Charger Disable" 518 "Inverter Enable" 519 "Inverter Disable" 520 "Charge Suspend On" 521 "Charge Suspend Off" 522 "AC Good" 523 "AC Bad" 524 "Load Sense Enable" 525 "Load Sense Active" 526 "Invert Active" 527 "Bulk Exit" 528 "Absorption Exit" 529 "Float Exit" 530 "Float 3-Stage Set" 531 "Float 2-Stage Set" 532 "Equalize Enable" 533 "Equalize Disable" 534 "Equalize Exit" 535 "Load Sense Disable" 536 "Sell To Grid Enabled" 537 "Sell To Grid Disabled" 538 "Grid Support Enable" 539 "Grid Support Disable" 540 "Gen Support Enable" 541 "Gen Support Disable" 542 "Peak Load Shaving Enable" 543 "Peak Load Shaving Disable" 544 "Peak Load Shaving Tod Start" 545 "Peak Load Shaving Tod Stop" 546 "Unit Off" 547 "System Absorption Exit" 548 "System Inverter Enable" 549 "System AC Good" 550 "Anti Islanding Condition" 551 "Hibernate Timeout" 552 "External Sync Error" 553 "External Suspend Request" 554 "Engaging Charger" 555 "Engaging Gen Support" 556 "Grid Tie Engage Timeout" 557 "Gen Support Engage Timeout" 558 "Charge Engage Timeout" 559 "Inverter Engage Timeout" 560 "Charge Exit Timeout" 561 "Grid Support Entry Amps" 562 "Grid Support Exit Amps" 563 "Gen Support Entry Amps" 564 "Gen Support Exit Amps" 565 "Grid Support Entry Vdc" 566 "Grid Support Exit Vdc" 567 "Low Batt Cut Off Entry Vdc" 568 "Low Batt Recharge Vdc" 569 "Low Batt Cut Off Exit Vdc" 570 "Invert To Bypass Timeout" 571 "Force Charge" 572 "System Engage Bulk Charge" 441 "SPS Auto On External Shutdown Flt" 442 "SPS Auto Off Input Over Volt Flt" 443 "SPS Auto On Input Over Volt Flt" 444 "SPS Auto Off Input Over Volt Err" 445 "SPS Auto On Input Over Volt Err" 446 "SPS Auto Off Input Over Volt Wrn" 447 "SPS Auto On Input Over Volt Wrn" 448 "SPS Auto Off Output Over Volt Err" 449 "SPS Auto On Output Over Volt Err" 450 "SPS Auto Off Output Over Volt Wrn" 451 "SPS Auto On Output Over Volt Wrn" 452 "SPS Auto Off Output Under Volt Err" 453 "SPS Auto On Output Under Volt Err" 454 "SPS Auto Off Output Under Volt Wrn" 455 "SPS Auto On Output Under Volt Wrn" 456 "SPS Auto Off Output Over Curr Err" 457 "SPS Auto On Output Over Curr Err" 458 "SPS Auto Off Batt Over Temp Err" 459 "SPS Auto On Batt Over Temp Err" 460 "SPS Auto Off Batt Over Temp Wrn" 461 "SPS Auto On Batt Over Temp Wrn" 462 "SPS Auto Off Batt Under Temp Wrn" 463 "SPS Auto On Batt Under Temp Wrn" 464 "SPS Auto Off Heatsink Over Temp Err" 465 "SPS Auto On Heatsink Over Temp Err" 466 "SPS Auto Off Heatsink Over Temp Wrn" 467 "SPS Auto On Heatsink Over Temp Wrn" 468 "SPS Auto Off Ambient Over Temp Err" 469 "SPS Auto On Ambient Over Temp Err" 470 "SPS Auto Off Ambient Over Temp Wrn" 471 "SPS Auto On Ambient Over Temp Wrn" 472 "SPS Auto Off Capacitor Over Temp Err" 473 "SPS Auto On Capacitor Over Temp Err" 474 "SPS Auto Off Fan Flt" 475 "SPS Auto On Fan Flt" 476 "SPS Auto Off Fan Err" 477 "SPS Auto On Fan Err" 478 "SPS Auto Off Input Over Curr Err" 479 "SPS Auto On Input Over Curr Err" 480 "SPS Auto Off Output Over Curr Flt" 481 "SPS Auto On Output Over Curr Flt" 482 "SPS Auto Off Network PS Flt" 483 "SPS Auto On Network PS Flt" 484 "SPS Auto Off Setup Flt" 485 "SPS Auto On Setup Flt" 38 "Clear Command User Stats" 573 "AC Good Pending" 574 "Grid Safe" 585 "PLS Time In Float Ready" 575 "Power Conversion Fault" 576 "Low Battery Support Exit" 577 "Grid Support Exit" 578 "GFS Enable" 579 "GFS Disable" 580 "Force Sell" 486 "SPS Auto On Bulk Exit" 487 "SPS Auto Off Bulk Exit" 488 "SPS Auto On Absorption Exit" 489 "SPS Auto Off Absorption Exit" 490 "SPS Auto On State Of Charge Low" 491 "SPS Auto Off State Of Charge Low" 492 "SPS Auto On Time Of Day" 493 "SPS Auto Off Time Of Day" 581 "Sell Time Of Day Start" 582 "Sell Time Of Day Stop" 583 "Aux Port Time Of Day Start" 584 "Aux Port Time Of Day Stop" ;
VAL_ 2147554560 EvtId 436 "SPS Auto Off Array V Low" 437 "SPS Auto On Array V Low" 438 "SPS Auto Off Ground Flt" 439 "SPS Auto On Ground Flt" 440 "SPS Auto Off External Shutdown Flt" 0 "None" 10 "Control Command Hibernate" 11 "Control Command Safe" 12 "Control Command Power Save" 13 "Control Command Operating" 14 "Control Command Diagnostic" 15 "Control Command Last Mode" 20 "Reset Command Reboot" 21 "Reset Command Download" 22 "Reset Command Oem" 23 "Reset Command Factory" 24 "Reset Command Reboot Clear Nv" 25 "Powered Up" 30 "Clear Command Active Faults" 31 "Clear Command Fault Log" 32 "Clear Command Active Warns" 33 "Clear Command Warn Log" 34 "Clear Command State Event Log" 35 "Clear Command Comm Stats" 36 "Clear Command Stats" 37 "Clear Command All" 40 "Date Time Configured" 50 "Warn Cleared" 51 "Fault Cleared" 52 "Fault Set" 60 "User Cfg Changed" 61 "Oem Cfg Changed" 70 "Triggered Fault" 250 "Shutdown Threshold" 251 "Shutdown Hysteresis" 252 "Warning Threshold" 253 "Warning Hysteresis" 254 "Transfer Threshold" 255 "Fan 0 Threshold" 256 "Fan 10 Threshold" 257 "Fan 20 Threshold" 258 "Fan 30 Threshold" 259 "Fan 40 Threshold" 260 "Fan 50 Threshold" 261 "Fan 60 Threshold" 262 "Fan 70 Threshold" 263 "Fan 80 Threshold" 264 "Fan 90 Threshold" 265 "Fan 100 Threshold" 266 "Relay Open Threshold" 267 "Relay Close Threshold" 268 "Charger Derating Ac In V" 269 "Charger Derating Ac In I" 270 "Charger Derating Ext Temp" 271 "Charger Derating Int Temp" 272 "Charger Derating Ripple V" 273 "Lost Ac Threshold" 274 "Lost Ac Hysteresis" 275 "Imm Shutdown Threshold" 276 "Imm Shutdown Hysteresis" 277 "Charger Shutdown Threshold" 278 "Charger Shutdown Hysteresis" 279 "Charger Warning Threshold" 280 "Charger Warning Hysteresis" 281 "Inverter Shutdown Threshold" 282 "Inverter Shutdown Hysteresis" 283 "Inverter Warning Threshold" 284 "Inverter Warning Hysteresis" 285 "Charger Derating Temp Start Point" 286 "Charger Derating Temp End Point" 287 "Charger Recharge Threshold" 300 "Ags Exercise Start" 301 "Ags Exercise Stop" 302 "Ags Quiet Time Begin" 303 "Ags Quiet Time End" 304 "Ags Battery Soc Start" 305 "Ags Battery Soc Stop" 306 "Ags Dc V Start" 307 "Ags Dc V Stop" 308 "Ags Ac I Start" 309 "Ags Ac I Stop" 310 "Ags Contact Start" 311 "Ags Contact Stop" 312 "Ags Float Stop" 313 "Ags Absorp Stop" 314 "Ags Manual On" 315 "Ags Manual Off" 316 "Ags Auto" 317 "Ags External On" 318 "Ags External Off" 319 "Gen External On" 320 "Gen External Off" 321 "Ags External Shutdown" 322 "Ags Auto Off" 323 "Ags Dc I Start" 324 "Ags Dc I Stop" 325 "Ags Ac Power Start" 326 "Ags Ac Power Stop" 400 "Sps Manual Off" 401 "Sps Manual On" 410 "Sps Auto Off" 411 "Sps Auto On" 420 "Sps Auto Off Batt V Low" 421 "Sps Auto On Batt V Low" 422 "Sps Auto Off Batt V High" 423 "Sps Auto On Batt V High" 424 "Sps Auto Off Array V High" 425 "Sps Auto On Array V High" 426 "Sps Auto Off Batt Temp Low" 427 "Sps Auto On Batt Temp Low" 428 "Sps Auto Off Batt Temp High" 429 "Sps Auto On Batt Temp High" 430 "Sps Auto Off Heat Sink Temp High" 431 "Sps Auto On Heat Sink Temp High" 432 "Sps Auto Off Fault" 433 "Sps Auto On Fault" 434 "Aps Check Timeout" 435 "Aps Qualify Timeout" 512 "Resume From Safe" 513 "AC Fault Set" 514 "Invert Fault Set" 515 "Charge Fault Set" 516 "Charger Enable" 517 "Charger Disable" 518 "Inverter Enable" 519 "Inverter Disable" 520 "Charge Suspend On" 521 "Charge Suspend Off" 522 "AC Good" 523 "AC Bad" 524 "Load Sense Enable" 525 "Load Sense Active" 526 "Invert Active" 527 "Bulk Exit" 528 "Absorption Exit" 529 "Float Exit" 530 "Float 3-Stage Set" 531 "Float 2-Stage Set" 532 "Equalize Enable" 533 "Equalize Disable" 534 "Equalize Exit" 535 "Load Sense Disable" 536 "Sell To Grid Enabled" 537 "Sell To Grid Disabled" 538 "Grid Support Enable" 539 "Grid Support Disable" 540 "Gen Support Enable" 541 "Gen Support Disable" 542 "Peak Load Shaving Enable" 543 "Peak Load Shaving Disable" 544 "Peak Load Shaving Tod Start" 545 "Peak Load Shaving Tod Stop" 546 "Unit Off" 547 "System Absorption Exit" 548 "System Inverter Enable" 549 "System AC Good" 550 "Anti Islanding Condition" 551 "Hibernate Timeout" 552 "External Sync Error" 553 "External Suspend Request" 554 "Engaging Charger" 555 "Engaging Gen Support" 556 "Grid Tie Engage Timeout" 557 "Gen Support Engage Timeout" 558 "Charge Engage Timeout" 559 "Inverter Engage Timeout" 560 "Charge Exit Timeout" 561 "Grid Support Entry Amps" 562 "Grid Support Exit Amps" 563 "Gen Support Entry Amps" 564 "Gen Support Exit Amps" 565 "Grid Support Entry Vdc" 566 "Grid Support Exit Vdc" 567 "Low Batt Cut Off Entry Vdc" 568 "Low Batt Recharge Vdc" 569 "Low Batt Cut Off Exit Vdc" 570 "Invert To Bypass Timeout" 571 "Force Charge" 572 "System Engage Bulk Charge" 441 "SPS Auto On External Shutdown Flt" 442 "SPS Auto Off Input Over Volt Flt" 443 "SPS Auto On Input Over Volt Flt" 444 "SPS Auto Off Input Over Volt Err" 445 "SPS Auto On Input Over Volt Err" 446 "SPS Auto Off Input Over Volt Wrn" 447 "SPS Auto On Input Over Volt Wrn" 448 "SPS Auto Off Output Over Volt Err" 449 "SPS Auto On Output Over Volt Err" 450 "SPS Auto Off Output Over Volt Wrn" 451 "SPS Auto On Output Over Volt Wrn" 452 "SPS Auto Off Output Under Volt Err" 453 "SPS Auto On Output Under Volt Err" 454 "SPS Auto Off Output Under Volt Wrn" 455 "SPS Auto On Output Under Volt Wrn" 456 "SPS Auto Off Output Over Curr Err" 457 "SPS Auto On Output Over Curr Err" 458 "SPS Auto Off Batt Over Temp Err" 459 "SPS Auto On Batt Over Temp Err" 460 "SPS Auto Off Batt Over Temp Wrn" 461 "SPS Auto On Batt Over Temp Wrn" 462 "SPS Auto Off Batt Under Temp Wrn" 463 "SPS Auto On Batt Under Temp Wrn" 464 "SPS Auto Off Heatsink Over Temp Err" 465 "SPS Auto On Heatsink Over Temp Err" 466 "SPS Auto Off Heatsink Over Temp Wrn" 467 "SPS Auto On Heatsink Over Temp Wrn" 468 "SPS Auto Off Ambient Over Temp Err" 469 "SPS Auto On Ambient Over Temp Err" 470 "SPS Auto Off Ambient Over Temp Wrn" 471 "SPS Auto On Ambient Over Temp Wrn" 472 "SPS Auto Off Capacitor Over Temp Err" 473 "SPS Auto On Capacitor Over Temp Err" 474 "SPS Auto Off Fan Flt" 475 "SPS Auto On Fan Flt" 476 "SPS Auto Off Fan Err" 477 "SPS Auto On Fan Err" 478 "SPS Auto Off Input Over Curr Err" 479 "SPS Auto On Input Over Curr Err" 480 "SPS Auto Off Output Over Curr Flt" 481 "SPS Auto On Output Over Curr Flt" 482 "SPS Auto Off Network PS Flt" 483 "SPS Auto On Network PS Flt" 484 "SPS Auto Off Setup Flt" 485 "SPS Auto On Setup Flt" 38 "Clear Command User Stats" 573 "AC Good Pending" 574 "Grid Safe" 585 "PLS Time In Float Ready" 575 "Power Conversion Fault" 576 "Low Battery Support Exit" 577 "Grid Support Exit" 578 "GFS Enable" 579 "GFS Disable" 580 "Force Sell" 486 "SPS Auto On Bulk Exit" 487 "SPS Auto Off Bulk Exit" 488 "SPS Auto On Absorption Exit" 489 "SPS Auto Off Absorption Exit" 490 "SPS Auto On State Of Charge Low" 491 "SPS Auto Off State Of Charge Low" 492 "SPS Auto On Time Of Day" 493 "SPS Auto Off Time Of Day" 581 "Sell Time Of Day Start" 582 "Sell Time Of Day Stop" 583 "Aux Port Time Of Day Start" 584 "Aux Port Time Of Day Stop" ;
VAL_ 2147554560 CfgType 0 "User" 1 "OEM" 2 "Factory" 3 "Reserved" ;
VAL_ 2147554816 TempSensId 0 "Transistor 1" 1 "Transistor 2" 2 "Transistor 3" 3 "Transistor 4" 10 "Capacitor 1" 11 "Capacitor 2" 12 "Capacitor 3" 13 "Capacitor 4" 20 "Transformer 1" 21 "Transformer 2" 22 "Transformer 3" 23 "Transformer 4" 30 "Ambient 1" 31 "Ambient 2" 32 "Ambient 3" 33 "Ambient 4" 34 "Shunt 1" 35 "Shunt 2" 36 "Shunt 3" 37 "Shunt 4" 38 "Heatsink 1" 39 "Heatsink 2" 40 "Heatsink 3" 41 "Heatsink 4" 253 "Reserved" 254 "Out of Range" 255 "Data Not Available Do Not Change" ;
VAL_ 2147554816 RefEvtId 436 "SPS Auto Off Array V Low" 437 "SPS Auto On Array V Low" 438 "SPS Auto Off Ground Flt" 439 "SPS Auto On Ground Flt" 440 "SPS Auto Off External Shutdown Flt" 0 "None" 10 "Control Command Hibernate" 11 "Control Command Safe" 12 "Control Command Power Save" 13 "Control Command Operating" 14 "Control Command Diagnostic" 15 "Control Command Last Mode" 20 "Reset Command Reboot" 21 "Reset Command Download" 22 "Reset Command Oem" 23 "Reset Command Factory" 24 "Reset Command Reboot Clear Nv" 25 "Powered Up" 30 "Clear Command Active Faults" 31 "Clear Command Fault Log" 32 "Clear Command Active Warns" 33 "Clear Command Warn Log" 34 "Clear Command State Event Log" 35 "Clear Command Comm Stats" 36 "Clear Command Stats" 37 "Clear Command All" 40 "Date Time Configured" 50 "Warn Cleared" 51 "Fault Cleared" 52 "Fault Set" 60 "User Cfg Changed" 61 "Oem Cfg Changed" 70 "Triggered Fault" 250 "Shutdown Threshold" 251 "Shutdown Hysteresis" 252 "Warning Threshold" 253 "Warning Hysteresis" 254 "Transfer Threshold" 255 "Fan 0 Threshold" 256 "Fan 10 Threshold" 257 "Fan 20 Threshold" 258 "Fan 30 Threshold" 259 "Fan 40 Threshold" 260 "Fan 50 Threshold" 261 "Fan 60 Threshold" 262 "Fan 70 Threshold" 263 "Fan 80 Threshold" 264 "Fan 90 Threshold" 265 "Fan 100 Threshold" 266 "Relay Open Threshold" 267 "Relay Close Threshold" 268 "Charger Derating Ac In V" 269 "Charger Derating Ac In I" 270 "Charger Derating Ext Temp" 271 "Charger Derating Int Temp" 272 "Charger Derating Ripple V" 273 "Lost Ac Threshold" 274 "Lost Ac Hysteresis" 275 "Imm Shutdown Threshold" 276 "Imm Shutdown Hysteresis" 277 "Charger Shutdown Threshold" 278 "Charger Shutdown Hysteresis" 279 "Charger Warning Threshold" 280 "Charger Warning Hysteresis" 281 "Inverter Shutdown Threshold" 282 "Inverter Shutdown Hysteresis" 283 "Inverter Warning Threshold" 284 "Inverter Warning Hysteresis" 285 "Charger Derating Temp Start Point" 286 "Charger Derating Temp End Point" 287 "Charger Recharge Threshold" 300 "Ags Exercise Start" 301 "Ags Exercise Stop" 302 "Ags Quiet Time Begin" 303 "Ags Quiet Time End" 304 "Ags Battery Soc Start" 305 "Ags Battery Soc Stop" 306 "Ags Dc V Start" 307 "Ags Dc V Stop" 308 "Ags Ac I Start" 309 "Ags Ac I Stop" 310 "Ags Contact Start" 311 "Ags Contact Stop" 312 "Ags Float Stop" 313 "Ags Absorp Stop" 314 "Ags Manual On" 315 "Ags Manual Off" 316 "Ags Auto" 317 "Ags External On" 318 "Ags External Off" 319 "Gen External On" 320 "Gen External Off" 321 "Ags External Shutdown" 322 "Ags Auto Off" 323 "Ags Dc I Start" 324 "Ags Dc I Stop" 325 "Ags Ac Power Start" 326 "Ags Ac Power Stop" 400 "Sps Manual Off" 401 "Sps Manual On" 410 "Sps Auto Off" 411 "Sps Auto On" 420 "Sps Auto Off Batt V Low" 421 "Sps Auto On Batt V Low" 422 "Sps Auto Off Batt V High" 423 "Sps Auto On Batt V High" 424 "Sps Auto Off Array V High" 425 "Sps Auto On Array V High" 426 "Sps Auto Off Batt Temp Low" 427 "Sps Auto On Batt Temp Low" 428 "Sps Auto Off Batt Temp High" 429 "Sps Auto On Batt Temp High" 430 "Sps Auto Off Heat Sink Temp High" 431 "Sps Auto On Heat Sink Temp High" 432 "Sps Auto Off Fault" 433 "Sps Auto On Fault" 434 "Aps Check Timeout" 435 "Aps Qualify Timeout" 512 "Resume From Safe" 513 "AC Fault Set" 514 "Invert Fault Set" 515 "Charge Fault Set" 516 "Charger Enable" 517 "Charger Disable" 518 "Inverter Enable" 519 "Inverter Disable" 520 "Charge Suspend On" 521 "Charge Suspend Off" 522 "AC Good" 523 "AC Bad" 524 "Load Sense Enable" 525 "Load Sense Active" 526 "Invert Active" 527 "Bulk Exit" 528 "Absorption Exit" 529 "Float Exit" 530 "Float 3-Stage Set" 531 "Float 2-Stage Set" 532 "Equalize Enable" 533 "Equalize Disable" 534 "Equalize Exit" 535 "Load Sense Disable" 536 "Sell To Grid Enabled" 537 "Sell To Grid Disabled" 538 "Grid Support Enable" 539 "Grid Support Disable" 540 "Gen Support Enable" 541 "Gen Support Disable" 542 "Peak Load Shaving Enable" 543 "Peak Load Shaving Disable" 544 "Peak Load Shaving Tod Start" 545 "Peak Load Shaving Tod Stop" 546 "Unit Off" 547 "System Absorption Exit" 548 "System Inverter Enable" 549 "System AC Good" 550 "Anti Islanding Condition" 551 "Hibernate Timeout" 552 "External Sync Error" 553 "External Suspend Request" 554 "Engaging Charger" 555 "Engaging Gen Support" 556 "Grid Tie Engage Timeout" 557 "Gen Support Engage Timeout" 558 "Charge Engage Timeout" 559 "Inverter Engage Timeout" 560 "Charge Exit Timeout" 561 "Grid Support Entry Amps" 562 "Grid Support Exit Amps" 563 "Gen Support Entry Amps" 564 "Gen Support Exit Amps" 565 "Grid Support Entry Vdc" 566 "Grid Support Exit Vdc" 567 "Low Batt Cut Off Entry Vdc" 568 "Low Batt Recharge Vdc" 569 "Low Batt Cut Off Exit Vdc" 570 "Invert To Bypass Timeout" 571 "Force Charge" 572 "System Engage Bulk Charge" 441 "SPS Auto On External Shutdown Flt" 442 "SPS Auto Off Input Over Volt Flt" 443 "SPS Auto On Input Over Volt Flt" 444 "SPS Auto Off Input Over Volt Err" 445 "SPS Auto On Input Over Volt Err" 446 "SPS Auto Off Input Over Volt Wrn" 447 "SPS Auto On Input Over Volt Wrn" 448 "SPS Auto Off Output Over Volt Err" 449 "SPS Auto On Output Over Volt Err" 450 "SPS Auto Off Output Over Volt Wrn" 451 "SPS Auto On Output Over Volt Wrn" 452 "SPS Auto Off Output Under Volt Err" 453 "SPS Auto On Output Under Volt Err" 454 "SPS Auto Off Output Under Volt Wrn" 455 "SPS Auto On Output Under Volt Wrn" 456 "SPS Auto Off Output Over Curr Err" 457 "SPS Auto On Output Over Curr Err" 458 "SPS Auto Off Batt Over Temp Err" 459 "SPS Auto On Batt Over Temp Err" 460 "SPS Auto Off Batt Over Temp Wrn" 461 "SPS Auto On Batt Over Temp Wrn" 462 "SPS Auto Off Batt Under Temp Wrn" 463 "SPS Auto On Batt Under Temp Wrn" 464 "SPS Auto Off Heatsink Over Temp Err" 465 "SPS Auto On Heatsink Over Temp Err" 466 "SPS Auto Off Heatsink Over Temp Wrn" 467 "SPS Auto On Heatsink Over Temp Wrn" 468 "SPS Auto Off Ambient Over Temp Err" 469 "SPS Auto On Ambient Over Temp Err" 470 "SPS Auto Off Ambient Over Temp Wrn" 471 "SPS Auto On Ambient Over Temp Wrn" 472 "SPS Auto Off Capacitor Over Temp Err" 473 "SPS Auto On Capacitor Over Temp Err" 474 "SPS Auto Off Fan Flt" 475 "SPS Auto On Fan Flt" 476 "SPS Auto Off Fan Err" 477 "SPS Auto On Fan Err" 478 "SPS Auto Off Input Over Curr Err" 479 "SPS Auto On Input Over Curr Err" 480 "SPS Auto Off Output Over Curr Flt" 481 "SPS Auto On Output Over Curr Flt" 482 "SPS Auto Off Network PS Flt" 483 "SPS Auto On Network PS Flt" 484 "SPS Auto Off Setup Flt" 485 "SPS Auto On Setup Flt" 38 "Clear Command User Stats" 573 "AC Good Pending" 574 "Grid Safe" 585 "PLS Time In Float Ready" 575 "Power Conversion Fault" 576 "Low Battery Support Exit" 577 "Grid Support Exit" 578 "GFS Enable" 579 "GFS Disable" 580 "Force Sell" 486 "SPS Auto On Bulk Exit" 487 "SPS Auto Off Bulk Exit" 488 "SPS Auto On Absorption Exit" 489 "SPS Auto Off Absorption Exit" 490 "SPS Auto On State Of Charge Low" 491 "SPS Auto Off State Of Charge Low" 492 "SPS Auto On Time Of Day" 493 "SPS Auto Off Time Of Day" 581 "Sell Time Of Day Start" 582 "Sell Time Of Day Stop" 583 "Aux Port Time Of Day Start" 584 "Aux Port Time Of Day Stop" ;
VAL_ 2147554816 EvtId 436 "SPS Auto Off Array V Low" 437 "SPS Auto On Array V Low" 438 "SPS Auto Off Ground Flt" 439 "SPS Auto On Ground Flt" 440 "SPS Auto Off External Shutdown Flt" 0 "None" 10 "Control Command Hibernate" 11 "Control Command Safe" 12 "Control Command Power Save" 13 "Control Command Operating" 14 "Control Command Diagnostic" 15 "Control Command Last Mode" 20 "Reset Command Reboot" 21 "Reset Command Download" 22 "Reset Command Oem" 23 "Reset Command Factory" 24 "Reset Command Reboot Clear Nv" 25 "Powered Up" 30 "Clear Command Active Faults" 31 "Clear Command Fault Log" 32 "Clear Command Active Warns" 33 "Clear Command Warn Log" 34 "Clear Command State Event Log" 35 "Clear Command Comm Stats" 36 "Clear Command Stats" 37 "Clear Command All" 40 "Date Time Configured" 50 "Warn Cleared" 51 "Fault Cleared" 52 "Fault Set" 60 "User Cfg Changed" 61 "Oem Cfg Changed" 70 "Triggered Fault" 250 "Shutdown Threshold" 251 "Shutdown Hysteresis" 252 "Warning Threshold" 253 "Warning Hysteresis" 254 "Transfer Threshold" 255 "Fan 0 Threshold" 256 "Fan 10 Threshold" 257 "Fan 20 Threshold" 258 "Fan 30 Threshold" 259 "Fan 40 Threshold" 260 "Fan 50 Threshold" 261 "Fan 60 Threshold" 262 "Fan 70 Threshold" 263 "Fan 80 Threshold" 264 "Fan 90 Threshold" 265 "Fan 100 Threshold" 266 "Relay Open Threshold" 267 "Relay Close Threshold" 268 "Charger Derating Ac In V" 269 "Charger Derating Ac In I" 270 "Charger Derating Ext Temp" 271 "Charger Derating Int Temp" 272 "Charger Derating Ripple V" 273 "Lost Ac Threshold" 274 "Lost Ac Hysteresis" 275 "Imm Shutdown Threshold" 276 "Imm Shutdown Hysteresis" 277 "Charger Shutdown Threshold" 278 "Charger Shutdown Hysteresis" 279 "Charger Warning Threshold" 280 "Charger Warning Hysteresis" 281 "Inverter Shutdown Threshold" 282 "Inverter Shutdown Hysteresis" 283 "Inverter Warning Threshold" 284 "Inverter Warning Hysteresis" 285 "Charger Derating Temp Start Point" 286 "Charger Derating Temp End Point" 287 "Charger Recharge Threshold" 300 "Ags Exercise Start" 301 "Ags Exercise Stop" 302 "Ags Quiet Time Begin" 303 "Ags Quiet Time End" 304 "Ags Battery Soc Start" 305 "Ags Battery Soc Stop" 306 "Ags Dc V Start" 307 "Ags Dc V Stop" 308 "Ags Ac I Start" 309 "Ags Ac I Stop" 310 "Ags Contact Start" 311 "Ags Contact Stop" 312 "Ags Float Stop" 313 "Ags Absorp Stop" 314 "Ags Manual On" 315 "Ags Manual Off" 316 "Ags Auto" 317 "Ags External On" 318 "Ags External Off" 319 "Gen External On" 320 "Gen External Off" 321 "Ags External Shutdown" 322 "Ags Auto Off" 323 "Ags Dc I Start" 324 "Ags Dc I Stop" 325 "Ags Ac Power Start" 326 "Ags Ac Power Stop" 400 "Sps Manual Off" 401 "Sps Manual On" 410 "Sps Auto Off" 411 "Sps Auto On" 420 "Sps Auto Off Batt V Low" 421 "Sps Auto On Batt V Low" 422 "Sps Auto Off Batt V High" 423 "Sps Auto On Batt V High" 424 "Sps Auto Off Array V High" 425 "Sps Auto On Array V High" 426 "Sps Auto Off Batt Temp Low" 427 "Sps Auto On Batt Temp Low" 428 "Sps Auto Off Batt Temp High" 429 "Sps Auto On Batt Temp High" 430 "Sps Auto Off Heat Sink Temp High" 431 "Sps Auto On Heat Sink Temp High" 432 "Sps Auto Off Fault" 433 "Sps Auto On Fault" 434 "Aps Check Timeout" 435 "Aps Qualify Timeout" 512 "Resume From Safe" 513 "AC Fault Set" 514 "Invert Fault Set" 515 "Charge Fault Set" 516 "Charger Enable" 517 "Charger Disable" 518 "Inverter Enable" 519 "Inverter Disable" 520 "Charge Suspend On" 521 "Charge Suspend Off" 522 "AC Good" 523 "AC Bad" 524 "Load Sense Enable" 525 "Load Sense Active" 526 "Invert Active" 527 "Bulk Exit" 528 "Absorption Exit" 529 "Float Exit" 530 "Float 3-Stage Set" 531 "Float 2-Stage Set" 532 "Equalize Enable" 533 "Equalize Disable" 534 "Equalize Exit" 535 "Load Sense Disable" 536 "Sell To Grid Enabled" 537 "Sell To Grid Disabled" 538 "Grid Support Enable" 539 "Grid Support Disable" 540 "Gen Support Enable" 541 "Gen Support Disable" 542 "Peak Load Shaving Enable" 543 "Peak Load Shaving Disable" 544 "Peak Load Shaving Tod Start" 545 "Peak Load Shaving Tod Stop" 546 "Unit Off" 547 "System Absorption Exit" 548 "System Inverter Enable" 549 "System AC Good" 550 "Anti Islanding Condition" 551 "Hibernate Timeout" 552 "External Sync Error" 553 "External Suspend Request" 554 "Engaging Charger" 555 "Engaging Gen Support" 556 "Grid Tie Engage Timeout" 557 "Gen Support Engage Timeout" 558 "Charge Engage Timeout" 559 "Inverter Engage Timeout" 560 "Charge Exit Timeout" 561 "Grid Support Entry Amps" 562 "Grid Support Exit Amps" 563 "Gen Support Entry Amps" 564 "Gen Support Exit Amps" 565 "Grid Support Entry Vdc" 566 "Grid Support Exit Vdc" 567 "Low Batt Cut Off Entry Vdc" 568 "Low Batt Recharge Vdc" 569 "Low Batt Cut Off Exit Vdc" 570 "Invert To Bypass Timeout" 571 "Force Charge" 572 "System Engage Bulk Charge" 441 "SPS Auto On External Shutdown Flt" 442 "SPS Auto Off Input Over Volt Flt" 443 "SPS Auto On Input Over Volt Flt" 444 "SPS Auto Off Input Over Volt Err" 445 "SPS Auto On Input Over Volt Err" 446 "SPS Auto Off Input Over Volt Wrn" 447 "SPS Auto On Input Over Volt Wrn" 448 "SPS Auto Off Output Over Volt Err" 449 "SPS Auto On Output Over Volt Err" 450 "SPS Auto Off Output Over Volt Wrn" 451 "SPS Auto On Output Over Volt Wrn" 452 "SPS Auto Off Output Under Volt Err" 453 "SPS Auto On Output Under Volt Err" 454 "SPS Auto Off Output Under Volt Wrn" 455 "SPS Auto On Output Under Volt Wrn" 456 "SPS Auto Off Output Over Curr Err" 457 "SPS Auto On Output Over Curr Err" 458 "SPS Auto Off Batt Over Temp Err" 459 "SPS Auto On Batt Over Temp Err" 460 "SPS Auto Off Batt Over Temp Wrn" 461 "SPS Auto On Batt Over Temp Wrn" 462 "SPS Auto Off Batt Under Temp Wrn" 463 "SPS Auto On Batt Under Temp Wrn" 464 "SPS Auto Off Heatsink Over Temp Err" 465 "SPS Auto On Heatsink Over Temp Err" 466 "SPS Auto Off Heatsink Over Temp Wrn" 467 "SPS Auto On Heatsink Over Temp Wrn" 468 "SPS Auto Off Ambient Over Temp Err" 469 "SPS Auto On Ambient Over Temp Err" 470 "SPS Auto Off Ambient Over Temp Wrn" 471 "SPS Auto On Ambient Over Temp Wrn" 472 "SPS Auto Off Capacitor Over Temp Err" 473 "SPS Auto On Capacitor Over Temp Err" 474 "SPS Auto Off Fan Flt" 475 "SPS Auto On Fan Flt" 476 "SPS Auto Off Fan Err" 477 "SPS Auto On Fan Err" 478 "SPS Auto Off Input Over Curr Err" 479 "SPS Auto On Input Over Curr Err" 480 "SPS Auto Off Output Over Curr Flt" 481 "SPS Auto On Output Over Curr Flt" 482 "SPS Auto Off Network PS Flt" 483 "SPS Auto On Network PS Flt" 484 "SPS Auto Off Setup Flt" 485 "SPS Auto On Setup Flt" 38 "Clear Command User Stats" 573 "AC Good Pending" 574 "Grid Safe" 585 "PLS Time In Float Ready" 575 "Power Conversion Fault" 576 "Low Battery Support Exit" 577 "Grid Support Exit" 578 "GFS Enable" 579 "GFS Disable" 580 "Force Sell" 486 "SPS Auto On Bulk Exit" 487 "SPS Auto Off Bulk Exit" 488 "SPS Auto On Absorption Exit" 489 "SPS Auto Off Absorption Exit" 490 "SPS Auto On State Of Charge Low" 491 "SPS Auto Off State Of Charge Low" 492 "SPS Auto On Time Of Day" 493 "SPS Auto Off Time Of Day" 581 "Sell Time Of Day Start" 582 "Sell Time Of Day Stop" 583 "Aux Port Time Of Day Start" 584 "Aux Port Time Of Day Stop" ;
VAL_ 2147554816 CfgType 0 "User" 1 "OEM" 2 "Factory" 3 "Reserved" ;
VAL_ 2147553536 RefEvtId 436 "SPS Auto Off Array V Low" 437 "SPS Auto On Array V Low" 438 "SPS Auto Off Ground Flt" 439 "SPS Auto On Ground Flt" 440 "SPS Auto Off External Shutdown Flt" 0 "None" 10 "Control Command Hibernate" 11 "Control Command Safe" 12 "Control Command Power Save" 13 "Control Command Operating" 14 "Control Command Diagnostic" 15 "Control Command Last Mode" 20 "Reset Command Reboot" 21 "Reset Command Download" 22 "Reset Command Oem" 23 "Reset Command Factory" 24 "Reset Command Reboot Clear Nv" 25 "Powered Up" 30 "Clear Command Active Faults" 31 "Clear Command Fault Log" 32 "Clear Command Active Warns" 33 "Clear Command Warn Log" 34 "Clear Command State Event Log" 35 "Clear Command Comm Stats" 36 "Clear Command Stats" 37 "Clear Command All" 40 "Date Time Configured" 50 "Warn Cleared" 51 "Fault Cleared" 52 "Fault Set" 60 "User Cfg Changed" 61 "Oem Cfg Changed" 70 "Triggered Fault" 250 "Shutdown Threshold" 251 "Shutdown Hysteresis" 252 "Warning Threshold" 253 "Warning Hysteresis" 254 "Transfer Threshold" 255 "Fan 0 Threshold" 256 "Fan 10 Threshold" 257 "Fan 20 Threshold" 258 "Fan 30 Threshold" 259 "Fan 40 Threshold" 260 "Fan 50 Threshold" 261 "Fan 60 Threshold" 262 "Fan 70 Threshold" 263 "Fan 80 Threshold" 264 "Fan 90 Threshold" 265 "Fan 100 Threshold" 266 "Relay Open Threshold" 267 "Relay Close Threshold" 268 "Charger Derating Ac In V" 269 "Charger Derating Ac In I" 270 "Charger Derating Ext Temp" 271 "Charger Derating Int Temp" 272 "Charger Derating Ripple V" 273 "Lost Ac Threshold" 274 "Lost Ac Hysteresis" 275 "Imm Shutdown Threshold" 276 "Imm Shutdown Hysteresis" 277 "Charger Shutdown Threshold" 278 "Charger Shutdown Hysteresis" 279 "Charger Warning Threshold" 280 "Charger Warning Hysteresis" 281 "Inverter Shutdown Threshold" 282 "Inverter Shutdown Hysteresis" 283 "Inverter Warning Threshold" 284 "Inverter Warning Hysteresis" 285 "Charger Derating Temp Start Point" 286 "Charger Derating Temp End Point" 287 "Charger Recharge Threshold" 300 "Ags Exercise Start" 301 "Ags Exercise Stop" 302 "Ags Quiet Time Begin" 303 "Ags Quiet Time End" 304 "Ags Battery Soc Start" 305 "Ags Battery Soc Stop" 306 "Ags Dc V Start" 307 "Ags Dc V Stop" 308 "Ags Ac I Start" 309 "Ags Ac I Stop" 310 "Ags Contact Start" 311 "Ags Contact Stop" 312 "Ags Float Stop" 313 "Ags Absorp Stop" 314 "Ags Manual On" 315 "Ags Manual Off" 316 "Ags Auto" 317 "Ags External On" 318 "Ags External Off" 319 "Gen External On" 320 "Gen External Off" 321 "Ags External Shutdown" 322 "Ags Auto Off" 323 "Ags Dc I Start" 324 "Ags Dc I Stop" 325 "Ags Ac Power Start" 326 "Ags Ac Power Stop" 400 "Sps Manual Off" 401 "Sps Manual On" 410 "Sps Auto Off" 411 "Sps Auto On" 420 "Sps Auto Off Batt V Low" 421 "Sps Auto On Batt V Low" 422 "Sps Auto Off Batt V High" 423 "Sps Auto On Batt V High" 424 "Sps Auto Off Array V High" 425 "Sps Auto On Array V High" 426 "Sps Auto Off Batt Temp Low" 427 "Sps Auto On Batt Temp Low" 428 "Sps Auto Off Batt Temp High" 429 "Sps Auto On Batt Temp High" 430 "Sps Auto Off Heat Sink Temp High" 431 "Sps Auto On Heat Sink Temp High" 432 "Sps Auto Off Fault" 433 "Sps Auto On Fault" 434 "Aps Check Timeout" 435 "Aps Qualify Timeout" 512 "Resume From Safe" 513 "AC Fault Set" 514 "Invert Fault Set" 515 "Charge Fault Set" 516 "Charger Enable" 517 "Charger Disable" 518 "Inverter Enable" 519 "Inverter Disable" 520 "Charge Suspend On" 521 "Charge Suspend Off" 522 "AC Good" 523 "AC Bad" 524 "Load Sense Enable" 525 "Load Sense Active" 526 "Invert Active" 527 "Bulk Exit" 528 "Absorption Exit" 529 "Float Exit" 530 "Float 3-Stage Set" 531 "Float 2-Stage Set" 532 "Equalize Enable" 533 "Equalize Disable" 534 "Equalize Exit" 535 "Load Sense Disable" 536 "Sell To Grid Enabled" 537 "Sell To Grid Disabled" 538 "Grid Support Enable" 539 "Grid Support Disable" 540 "Gen Support Enable" 541 "Gen Support Disable" 542 "Peak Load Shaving Enable" 543 "Peak Load Shaving Disable" 544 "Peak Load Shaving Tod Start" 545 "Peak Load Shaving Tod Stop" 546 "Unit Off" 547 "System Absorption Exit" 548 "System Inverter Enable" 549 "System AC Good" 550 "Anti Islanding Condition" 551 "Hibernate Timeout" 552 "External Sync Error" 553 "External Suspend Request" 554 "Engaging Charger" 555 "Engaging Gen Support" 556 "Grid Tie Engage Timeout" 557 "Gen Support Engage Timeout" 558 "Charge Engage Timeout" 559 "Inverter Engage Timeout" 560 "Charge Exit Timeout" 561 "Grid Support Entry Amps" 562 "Grid Support Exit Amps" 563 "Gen Support Entry Amps" 564 "Gen Support Exit Amps" 565 "Grid Support Entry Vdc" 566 "Grid Support Exit Vdc" 567 "Low Batt Cut Off Entry Vdc" 568 "Low Batt Recharge Vdc" 569 "Low Batt Cut Off Exit Vdc" 570 "Invert To Bypass Timeout" 571 "Force Charge" 572 "System Engage Bulk Charge" 441 "SPS Auto On External Shutdown Flt" 442 "SPS Auto Off Input Over Volt Flt" 443 "SPS Auto On Input Over Volt Flt" 444 "SPS Auto Off Input Over Volt Err" 445 "SPS Auto On Input Over Volt Err" 446 "SPS Auto Off Input Over Volt Wrn" 447 "SPS Auto On Input Over Volt Wrn" 448 "SPS Auto Off Output Over Volt Err" 449 "SPS Auto On Output Over Volt Err" 450 "SPS Auto Off Output Over Volt Wrn" 451 "SPS Auto On Output Over Volt Wrn" 452 "SPS Auto Off Output Under Volt Err" 453 "SPS Auto On Output Under Volt Err" 454 "SPS Auto Off Output Under Volt Wrn" 455 "SPS Auto On Output Under Volt Wrn" 456 "SPS Auto Off Output Over Curr Err" 457 "SPS Auto On Output Over Curr Err" 458 "SPS Auto Off Batt Over Temp Err" 459 "SPS Auto On Batt Over Temp Err" 460 "SPS Auto Off Batt Over Temp Wrn" 461 "SPS Auto On Batt Over Temp Wrn" 462 "SPS Auto Off Batt Under Temp Wrn" 463 "SPS Auto On Batt Under Temp Wrn" 464 "SPS Auto Off Heatsink Over Temp Err" 465 "SPS Auto On Heatsink Over Temp Err" 466 "SPS Auto Off Heatsink Over Temp Wrn" 467 "SPS Auto On Heatsink Over Temp Wrn" 468 "SPS Auto Off Ambient Over Temp Err" 469 "SPS Auto On Ambient Over Temp Err" 470 "SPS Auto Off Ambient Over Temp Wrn" 471 "SPS Auto On Ambient Over Temp Wrn" 472 "SPS Auto Off Capacitor Over Temp Err" 473 "SPS Auto On Capacitor Over Temp Err" 474 "SPS Auto Off Fan Flt" 475 "SPS Auto On Fan Flt" 476 "SPS Auto Off Fan Err" 477 "SPS Auto On Fan Err" 478 "SPS Auto Off Input Over Curr Err" 479 "SPS Auto On Input Over Curr Err" 480 "SPS Auto Off Output Over Curr Flt" 481 "SPS Auto On Output Over Curr Flt" 482 "SPS Auto Off Network PS Flt" 483 "SPS Auto On Network PS Flt" 484 "SPS Auto Off Setup Flt" 485 "SPS Auto On Setup Flt" 38 "Clear Command User Stats" 573 "AC Good Pending" 574 "Grid Safe" 585 "PLS Time In Float Ready" 575 "Power Conversion Fault" 576 "Low Battery Support Exit" 577 "Grid Support Exit" 578 "GFS Enable" 579 "GFS Disable" 580 "Force Sell" 486 "SPS Auto On Bulk Exit" 487 "SPS Auto Off Bulk Exit" 488 "SPS Auto On Absorption Exit" 489 "SPS Auto Off Absorption Exit" 490 "SPS Auto On State Of Charge Low" 491 "SPS Auto Off State Of Charge Low" 492 "SPS Auto On Time Of Day" 493 "SPS Auto Off Time Of Day" 581 "Sell Time Of Day Start" 582 "Sell Time Of Day Stop" 583 "Aux Port Time Of Day Start" 584 "Aux Port Time Of Day Stop" ;
VAL_ 2147553536 EvtId 436 "SPS Auto Off Array V Low" 437 "SPS Auto On Array V Low" 438 "SPS Auto Off Ground Flt" 439 "SPS Auto On Ground Flt" 440 "SPS Auto Off External Shutdown Flt" 0 "None" 10 "Control Command Hibernate" 11 "Control Command Safe" 12 "Control Command Power Save" 13 "Control Command Operating" 14 "Control Command Diagnostic" 15 "Control Command Last Mode" 20 "Reset Command Reboot" 21 "Reset Command Download" 22 "Reset Command Oem" 23 "Reset Command Factory" 24 "Reset Command Reboot Clear Nv" 25 "Powered Up" 30 "Clear Command Active Faults" 31 "Clear Command Fault Log" 32 "Clear Command Active Warns" 33 "Clear Command Warn Log" 34 "Clear Command State Event Log" 35 "Clear Command Comm Stats" 36 "Clear Command Stats" 37 "Clear Command All" 40 "Date Time Configured" 50 "Warn Cleared" 51 "Fault Cleared" 52 "Fault Set" 60 "User Cfg Changed" 61 "Oem Cfg Changed" 70 "Triggered Fault" 250 "Shutdown Threshold" 251 "Shutdown Hysteresis" 252 "Warning Threshold" 253 "Warning Hysteresis" 254 "Transfer Threshold" 255 "Fan 0 Threshold" 256 "Fan 10 Threshold" 257 "Fan 20 Threshold" 258 "Fan 30 Threshold" 259 "Fan 40 Threshold" 260 "Fan 50 Threshold" 261 "Fan 60 Threshold" 262 "Fan 70 Threshold" 263 "Fan 80 Threshold" 264 "Fan 90 Threshold" 265 "Fan 100 Threshold" 266 "Relay Open Threshold" 267 "Relay Close Threshold" 268 "Charger Derating Ac In V" 269 "Charger Derating Ac In I" 270 "Charger Derating Ext Temp" 271 "Charger Derating Int Temp" 272 "Charger Derating Ripple V" 273 "Lost Ac Threshold" 274 "Lost Ac Hysteresis" 275 "Imm Shutdown Threshold" 276 "Imm Shutdown Hysteresis" 277 "Charger Shutdown Threshold" 278 "Charger Shutdown Hysteresis" 279 "Charger Warning Threshold" 280 "Charger Warning Hysteresis" 281 "Inverter Shutdown Threshold" 282 "Inverter Shutdown Hysteresis" 283 "Inverter Warning Threshold" 284 "Inverter Warning Hysteresis" 285 "Charger Derating Temp Start Point" 286 "Charger Derating Temp End Point" 287 "Charger Recharge Threshold" 300 "Ags Exercise Start" 301 "Ags Exercise Stop" 302 "Ags Quiet Time Begin" 303 "Ags Quiet Time End" 304 "Ags Battery Soc Start" 305 "Ags Battery Soc Stop" 306 "Ags Dc V Start" 307 "Ags Dc V Stop" 308 "Ags Ac I Start" 309 "Ags Ac I Stop" 310 "Ags Contact Start" 311 "Ags Contact Stop" 312 "Ags Float Stop" 313 "Ags Absorp Stop" 314 "Ags Manual On" 315 "Ags Manual Off" 316 "Ags Auto" 317 "Ags External On" 318 "Ags External Off" 319 "Gen External On" 320 "Gen External Off" 321 "Ags External Shutdown" 322 "Ags Auto Off" 323 "Ags Dc I Start" 324 "Ags Dc I Stop" 325 "Ags Ac Power Start" 326 "Ags Ac Power Stop" 400 "Sps Manual Off" 401 "Sps Manual On" 410 "Sps Auto Off" 411 "Sps Auto On" 420 "Sps Auto Off Batt V Low" 421 "Sps Auto On Batt V Low" 422 "Sps Auto Off Batt V High" 423 "Sps Auto On Batt V High" 424 "Sps Auto Off Array V High" 425 "Sps Auto On Array V High" 426 "Sps Auto Off Batt Temp Low" 427 "Sps Auto On Batt Temp Low" 428 "Sps Auto Off Batt Temp High" 429 "Sps Auto On Batt Temp High" 430 "Sps Auto Off Heat Sink Temp High" 431 "Sps Auto On Heat Sink Temp High" 432 "Sps Auto Off Fault" 433 "Sps Auto On Fault" 434 "Aps Check Timeout" 435 "Aps Qualify Timeout" 512 "Resume From Safe" 513 "AC Fault Set" 514 "Invert Fault Set" 515 "Charge Fault Set" 516 "Charger Enable" 517 "Charger Disable" 518 "Inverter Enable" 519 "Inverter Disable" 520 "Charge Suspend On" 521 "Charge Suspend Off" 522 "AC Good" 523 "AC Bad" 524 "Load Sense Enable" 525 "Load Sense Active" 526 "Invert Active" 527 "Bulk Exit" 528 "Absorption Exit" 529 "Float Exit" 530 "Float 3-Stage Set" 531 "Float 2-Stage Set" 532 "Equalize Enable" 533 "Equalize Disable" 534 "Equalize Exit" 535 "Load Sense Disable" 536 "Sell To Grid Enabled" 537 "Sell To Grid Disabled" 538 "Grid Support Enable" 539 "Grid Support Disable" 540 "Gen Support Enable" 541 "Gen Support Disable" 542 "Peak Load Shaving Enable" 543 "Peak Load Shaving Disable" 544 "Peak Load Shaving Tod Start" 545 "Peak Load Shaving Tod Stop" 546 "Unit Off" 547 "System Absorption Exit" 548 "System Inverter Enable" 549 "System AC Good" 550 "Anti Islanding Condition" 551 "Hibernate Timeout" 552 "External Sync Error" 553 "External Suspend Request" 554 "Engaging Charger" 555 "Engaging Gen Support" 556 "Grid Tie Engage Timeout" 557 "Gen Support Engage Timeout" 558 "Charge Engage Timeout" 559 "Inverter Engage Timeout" 560 "Charge Exit Timeout" 561 "Grid Support Entry Amps" 562 "Grid Support Exit Amps" 563 "Gen Support Entry Amps" 564 "Gen Support Exit Amps" 565 "Grid Support Entry Vdc" 566 "Grid Support Exit Vdc" 567 "Low Batt Cut Off Entry Vdc" 568 "Low Batt Recharge Vdc" 569 "Low Batt Cut Off Exit Vdc" 570 "Invert To Bypass Timeout" 571 "Force Charge" 572 "System Engage Bulk Charge" 441 "SPS Auto On External Shutdown Flt" 442 "SPS Auto Off Input Over Volt Flt" 443 "SPS Auto On Input Over Volt Flt" 444 "SPS Auto Off Input Over Volt Err" 445 "SPS Auto On Input Over Volt Err" 446 "SPS Auto Off Input Over Volt Wrn" 447 "SPS Auto On Input Over Volt Wrn" 448 "SPS Auto Off Output Over Volt Err" 449 "SPS Auto On Output Over Volt Err" 450 "SPS Auto Off Output Over Volt Wrn" 451 "SPS Auto On Output Over Volt Wrn" 452 "SPS Auto Off Output Under Volt Err" 453 "SPS Auto On Output Under Volt Err" 454 "SPS Auto Off Output Under Volt Wrn" 455 "SPS Auto On Output Under Volt Wrn" 456 "SPS Auto Off Output Over Curr Err" 457 "SPS Auto On Output Over Curr Err" 458 "SPS Auto Off Batt Over Temp Err" 459 "SPS Auto On Batt Over Temp Err" 460 "SPS Auto Off Batt Over Temp Wrn" 461 "SPS Auto On Batt Over Temp Wrn" 462 "SPS Auto Off Batt Under Temp Wrn" 463 "SPS Auto On Batt Under Temp Wrn" 464 "SPS Auto Off Heatsink Over Temp Err" 465 "SPS Auto On Heatsink Over Temp Err" 466 "SPS Auto Off Heatsink Over Temp Wrn" 467 "SPS Auto On Heatsink Over Temp Wrn" 468 "SPS Auto Off Ambient Over Temp Err" 469 "SPS Auto On Ambient Over Temp Err" 470 "SPS Auto Off Ambient Over Temp Wrn" 471 "SPS Auto On Ambient Over Temp Wrn" 472 "SPS Auto Off Capacitor Over Temp Err" 473 "SPS Auto On Capacitor Over Temp Err" 474 "SPS Auto Off Fan Flt" 475 "SPS Auto On Fan Flt" 476 "SPS Auto Off Fan Err" 477 "SPS Auto On Fan Err" 478 "SPS Auto Off Input Over Curr Err" 479 "SPS Auto On Input Over Curr Err" 480 "SPS Auto Off Output Over Curr Flt" 481 "SPS Auto On Output Over Curr Flt" 482 "SPS Auto Off Network PS Flt" 483 "SPS Auto On Network PS Flt" 484 "SPS Auto Off Setup Flt" 485 "SPS Auto On Setup Flt" 38 "Clear Command User Stats" 573 "AC Good Pending" 574 "Grid Safe" 585 "PLS Time In Float Ready" 575 "Power Conversion Fault" 576 "Low Battery Support Exit" 577 "Grid Support Exit" 578 "GFS Enable" 579 "GFS Disable" 580 "Force Sell" 486 "SPS Auto On Bulk Exit" 487 "SPS Auto Off Bulk Exit" 488 "SPS Auto On Absorption Exit" 489 "SPS Auto Off Absorption Exit" 490 "SPS Auto On State Of Charge Low" 491 "SPS Auto Off State Of Charge Low" 492 "SPS Auto On Time Of Day" 493 "SPS Auto Off Time Of Day" 581 "Sell Time Of Day Start" 582 "Sell Time Of Day Stop" 583 "Aux Port Time Of Day Start" 584 "Aux Port Time Of Day Stop" ;
VAL_ 2147553536 CfgType 0 "User" 1 "OEM" 2 "Factory" 3 "Reserved" ;
VAL_ 2147553792 RefEvtId 436 "SPS Auto Off Array V Low" 437 "SPS Auto On Array V Low" 438 "SPS Auto Off Ground Flt" 439 "SPS Auto On Ground Flt" 440 "SPS Auto Off External Shutdown Flt" 0 "None" 10 "Control Command Hibernate" 11 "Control Command Safe" 12 "Control Command Power Save" 13 "Control Command Operating" 14 "Control Command Diagnostic" 15 "Control Command Last Mode" 20 "Reset Command Reboot" 21 "Reset Command Download" 22 "Reset Command Oem" 23 "Reset Command Factory" 24 "Reset Command Reboot Clear Nv" 25 "Powered Up" 30 "Clear Command Active Faults" 31 "Clear Command Fault Log" 32 "Clear Command Active Warns" 33 "Clear Command Warn Log" 34 "Clear Command State Event Log" 35 "Clear Command Comm Stats" 36 "Clear Command Stats" 37 "Clear Command All" 40 "Date Time Configured" 50 "Warn Cleared" 51 "Fault Cleared" 52 "Fault Set" 60 "User Cfg Changed" 61 "Oem Cfg Changed" 70 "Triggered Fault" 250 "Shutdown Threshold" 251 "Shutdown Hysteresis" 252 "Warning Threshold" 253 "Warning Hysteresis" 254 "Transfer Threshold" 255 "Fan 0 Threshold" 256 "Fan 10 Threshold" 257 "Fan 20 Threshold" 258 "Fan 30 Threshold" 259 "Fan 40 Threshold" 260 "Fan 50 Threshold" 261 "Fan 60 Threshold" 262 "Fan 70 Threshold" 263 "Fan 80 Threshold" 264 "Fan 90 Threshold" 265 "Fan 100 Threshold" 266 "Relay Open Threshold" 267 "Relay Close Threshold" 268 "Charger Derating Ac In V" 269 "Charger Derating Ac In I" 270 "Charger Derating Ext Temp" 271 "Charger Derating Int Temp" 272 "Charger Derating Ripple V" 273 "Lost Ac Threshold" 274 "Lost Ac Hysteresis" 275 "Imm Shutdown Threshold" 276 "Imm Shutdown Hysteresis" 277 "Charger Shutdown Threshold" 278 "Charger Shutdown Hysteresis" 279 "Charger Warning Threshold" 280 "Charger Warning Hysteresis" 281 "Inverter Shutdown Threshold" 282 "Inverter Shutdown Hysteresis" 283 "Inverter Warning Threshold" 284 "Inverter Warning Hysteresis" 285 "Charger Derating Temp Start Point" 286 "Charger Derating Temp End Point" 287 "Charger Recharge Threshold" 300 "Ags Exercise Start" 301 "Ags Exercise Stop" 302 "Ags Quiet Time Begin" 303 "Ags Quiet Time End" 304 "Ags Battery Soc Start" 305 "Ags Battery Soc Stop" 306 "Ags Dc V Start" 307 "Ags Dc V Stop" 308 "Ags Ac I Start" 309 "Ags Ac I Stop" 310 "Ags Contact Start" 311 "Ags Contact Stop" 312 "Ags Float Stop" 313 "Ags Absorp Stop" 314 "Ags Manual On" 315 "Ags Manual Off" 316 "Ags Auto" 317 "Ags External On" 318 "Ags External Off" 319 "Gen External On" 320 "Gen External Off" 321 "Ags External Shutdown" 322 "Ags Auto Off" 323 "Ags Dc I Start" 324 "Ags Dc I Stop" 325 "Ags Ac Power Start" 326 "Ags Ac Power Stop" 400 "Sps Manual Off" 401 "Sps Manual On" 410 "Sps Auto Off" 411 "Sps Auto On" 420 "Sps Auto Off Batt V Low" 421 "Sps Auto On Batt V Low" 422 "Sps Auto Off Batt V High" 423 "Sps Auto On Batt V High" 424 "Sps Auto Off Array V High" 425 "Sps Auto On Array V High" 426 "Sps Auto Off Batt Temp Low" 427 "Sps Auto On Batt Temp Low" 428 "Sps Auto Off Batt Temp High" 429 "Sps Auto On Batt Temp High" 430 "Sps Auto Off Heat Sink Temp High" 431 "Sps Auto On Heat Sink Temp High" 432 "Sps Auto Off Fault" 433 "Sps Auto On Fault" 434 "Aps Check Timeout" 435 "Aps Qualify Timeout" 512 "Resume From Safe" 513 "AC Fault Set" 514 "Invert Fault Set" 515 "Charge Fault Set" 516 "Charger Enable" 517 "Charger Disable" 518 "Inverter Enable" 519 "Inverter Disable" 520 "Charge Suspend On" 521 "Charge Suspend Off" 522 "AC Good" 523 "AC Bad" 524 "Load Sense Enable" 525 "Load Sense Active" 526 "Invert Active" 527 "Bulk Exit" 528 "Absorption Exit" 529 "Float Exit" 530 "Float 3-Stage Set" 531 "Float 2-Stage Set" 532 "Equalize Enable" 533 "Equalize Disable" 534 "Equalize Exit" 535 "Load Sense Disable" 536 "Sell To Grid Enabled" 537 "Sell To Grid Disabled" 538 "Grid Support Enable" 539 "Grid Support Disable" 540 "Gen Support Enable" 541 "Gen Support Disable" 542 "Peak Load Shaving Enable" 543 "Peak Load Shaving Disable" 544 "Peak Load Shaving Tod Start" 545 "Peak Load Shaving Tod Stop" 546 "Unit Off" 547 "System Absorption Exit" 548 "System Inverter Enable" 549 "System AC Good" 550 "Anti Islanding Condition" 551 "Hibernate Timeout" 552 "External Sync Error" 553 "External Suspend Request" 554 "Engaging Charger" 555 "Engaging Gen Support" 556 "Grid Tie Engage Timeout" 557 "Gen Support Engage Timeout" 558 "Charge Engage Timeout" 559 "Inverter Engage Timeout" 560 "Charge Exit Timeout" 561 "Grid Support Entry Amps" 562 "Grid Support Exit Amps" 563 "Gen Support Entry Amps" 564 "Gen Support Exit Amps" 565 "Grid Support Entry Vdc" 566 "Grid Support Exit Vdc" 567 "Low Batt Cut Off Entry Vdc" 568 "Low Batt Recharge Vdc" 569 "Low Batt Cut Off Exit Vdc" 570 "Invert To Bypass Timeout" 571 "Force Charge" 572 "System Engage Bulk Charge" 441 "SPS Auto On External Shutdown Flt" 442 "SPS Auto Off Input Over Volt Flt" 443 "SPS Auto On Input Over Volt Flt" 444 "SPS Auto Off Input Over Volt Err" 445 "SPS Auto On Input Over Volt Err" 446 "SPS Auto Off Input Over Volt Wrn" 447 "SPS Auto On Input Over Volt Wrn" 448 "SPS Auto Off Output Over Volt Err" 449 "SPS Auto On Output Over Volt Err" 450 "SPS Auto Off Output Over Volt Wrn" 451 "SPS Auto On Output Over Volt Wrn" 452 "SPS Auto Off Output Under Volt Err" 453 "SPS Auto On Output Under Volt Err" 454 "SPS Auto Off Output Under Volt Wrn" 455 "SPS Auto On Output Under Volt Wrn" 456 "SPS Auto Off Output Over Curr Err" 457 "SPS Auto On Output Over Curr Err" 458 "SPS Auto Off Batt Over Temp Err" 459 "SPS Auto On Batt Over Temp Err" 460 "SPS Auto Off Batt Over Temp Wrn" 461 "SPS Auto On Batt Over Temp Wrn" 462 "SPS Auto Off Batt Under Temp Wrn" 463 "SPS Auto On Batt Under Temp Wrn" 464 "SPS Auto Off Heatsink Over Temp Err" 465 "SPS Auto On Heatsink Over Temp Err" 466 "SPS Auto Off Heatsink Over Temp Wrn" 467 "SPS Auto On Heatsink Over Temp Wrn" 468 "SPS Auto Off Ambient Over Temp Err" 469 "SPS Auto On Ambient Over Temp Err" 470 "SPS Auto Off Ambient Over Temp Wrn" 471 "SPS Auto On Ambient Over Temp Wrn" 472 "SPS Auto Off Capacitor Over Temp Err" 473 "SPS Auto On Capacitor Over Temp Err" 474 "SPS Auto Off Fan Flt" 475 "SPS Auto On Fan Flt" 476 "SPS Auto Off Fan Err" 477 "SPS Auto On Fan Err" 478 "SPS Auto Off Input Over Curr Err" 479 "SPS Auto On Input Over Curr Err" 480 "SPS Auto Off Output Over Curr Flt" 481 "SPS Auto On Output Over Curr Flt" 482 "SPS Auto Off Network PS Flt" 483 "SPS Auto On Network PS Flt" 484 "SPS Auto Off Setup Flt" 485 "SPS Auto On Setup Flt" 38 "Clear Command User Stats" 573 "AC Good Pending" 574 "Grid Safe" 585 "PLS Time In Float Ready" 575 "Power Conversion Fault" 576 "Low Battery Support Exit" 577 "Grid Support Exit" 578 "GFS Enable" 579 "GFS Disable" 580 "Force Sell" 486 "SPS Auto On Bulk Exit" 487 "SPS Auto Off Bulk Exit" 488 "SPS Auto On Absorption Exit" 489 "SPS Auto Off Absorption Exit" 490 "SPS Auto On State Of Charge Low" 491 "SPS Auto Off State Of Charge Low" 492 "SPS Auto On Time Of Day" 493 "SPS Auto Off Time Of Day" 581 "Sell Time Of Day Start" 582 "Sell Time Of Day Stop" 583 "Aux Port Time Of Day Start" 584 "Aux Port Time Of Day Stop" ;
VAL_ 2147553792 EvtId 436 "SPS Auto Off Array V Low" 437 "SPS Auto On Array V Low" 438 "SPS Auto Off Ground Flt" 439 "SPS Auto On Ground Flt" 440 "SPS Auto Off External Shutdown Flt" 0 "None" 10 "Control Command Hibernate" 11 "Control Command Safe" 12 "Control Command Power Save" 13 "Control Command Operating" 14 "Control Command Diagnostic" 15 "Control Command Last Mode" 20 "Reset Command Reboot" 21 "Reset Command Download" 22 "Reset Command Oem" 23 "Reset Command Factory" 24 "Reset Command Reboot Clear Nv" 25 "Powered Up" 30 "Clear Command Active Faults" 31 "Clear Command Fault Log" 32 "Clear Command Active Warns" 33 "Clear Command Warn Log" 34 "Clear Command State Event Log" 35 "Clear Command Comm Stats" 36 "Clear Command Stats" 37 "Clear Command All" 40 "Date Time Configured" 50 "Warn Cleared" 51 "Fault Cleared" 52 "Fault Set" 60 "User Cfg Changed" 61 "Oem Cfg Changed" 70 "Triggered Fault" 250 "Shutdown Threshold" 251 "Shutdown Hysteresis" 252 "Warning Threshold" 253 "Warning Hysteresis" 254 "Transfer Threshold" 255 "Fan 0 Threshold" 256 "Fan 10 Threshold" 257 "Fan 20 Threshold" 258 "Fan 30 Threshold" 259 "Fan 40 Threshold" 260 "Fan 50 Threshold" 261 "Fan 60 Threshold" 262 "Fan 70 Threshold" 263 "Fan 80 Threshold" 264 "Fan 90 Threshold" 265 "Fan 100 Threshold" 266 "Relay Open Threshold" 267 "Relay Close Threshold" 268 "Charger Derating Ac In V" 269 "Charger Derating Ac In I" 270 "Charger Derating Ext Temp" 271 "Charger Derating Int Temp" 272 "Charger Derating Ripple V" 273 "Lost Ac Threshold" 274 "Lost Ac Hysteresis" 275 "Imm Shutdown Threshold" 276 "Imm Shutdown Hysteresis" 277 "Charger Shutdown Threshold" 278 "Charger Shutdown Hysteresis" 279 "Charger Warning Threshold" 280 "Charger Warning Hysteresis" 281 "Inverter Shutdown Threshold" 282 "Inverter Shutdown Hysteresis" 283 "Inverter Warning Threshold" 284 "Inverter Warning Hysteresis" 285 "Charger Derating Temp Start Point" 286 "Charger Derating Temp End Point" 287 "Charger Recharge Threshold" 300 "Ags Exercise Start" 301 "Ags Exercise Stop" 302 "Ags Quiet Time Begin" 303 "Ags Quiet Time End" 304 "Ags Battery Soc Start" 305 "Ags Battery Soc Stop" 306 "Ags Dc V Start" 307 "Ags Dc V Stop" 308 "Ags Ac I Start" 309 "Ags Ac I Stop" 310 "Ags Contact Start" 311 "Ags Contact Stop" 312 "Ags Float Stop" 313 "Ags Absorp Stop" 314 "Ags Manual On" 315 "Ags Manual Off" 316 "Ags Auto" 317 "Ags External On" 318 "Ags External Off" 319 "Gen External On" 320 "Gen External Off" 321 "Ags External Shutdown" 322 "Ags Auto Off" 323 "Ags Dc I Start" 324 "Ags Dc I Stop" 325 "Ags Ac Power Start" 326 "Ags Ac Power Stop" 400 "Sps Manual Off" 401 "Sps Manual On" 410 "Sps Auto Off" 411 "Sps Auto On" 420 "Sps Auto Off Batt V Low" 421 "Sps Auto On Batt V Low" 422 "Sps Auto Off Batt V High" 423 "Sps Auto On Batt V High" 424 "Sps Auto Off Array V High" 425 "Sps Auto On Array V High" 426 "Sps Auto Off Batt Temp Low" 427 "Sps Auto On Batt Temp Low" 428 "Sps Auto Off Batt Temp High" 429 "Sps Auto On Batt Temp High" 430 "Sps Auto Off Heat Sink Temp High" 431 "Sps Auto On Heat Sink Temp High" 432 "Sps Auto Off Fault" 433 "Sps Auto On Fault" 434 "Aps Check Timeout" 435 "Aps Qualify Timeout" 512 "Resume From Safe" 513 "AC Fault Set" 514 "Invert Fault Set" 515 "Charge Fault Set" 516 "Charger Enable" 517 "Charger Disable" 518 "Inverter Enable" 519 "Inverter Disable" 520 "Charge Suspend On" 521 "Charge Suspend Off" 522 "AC Good" 523 "AC Bad" 524 "Load Sense Enable" 525 "Load Sense Active" 526 "Invert Active" 527 "Bulk Exit" 528 "Absorption Exit" 529 "Float Exit" 530 "Float 3-Stage Set" 531 "Float 2-Stage Set" 532 "Equalize Enable" 533 "Equalize Disable" 534 "Equalize Exit" 535 "Load Sense Disable" 536 "Sell To Grid Enabled" 537 "Sell To Grid Disabled" 538 "Grid Support Enable" 539 "Grid Support Disable" 540 "Gen Support Enable" 541 "Gen Support Disable" 542 "Peak Load Shaving Enable" 543 "Peak Load Shaving Disable" 544 "Peak Load Shaving Tod Start" 545 "Peak Load Shaving Tod Stop" 546 "Unit Off" 547 "System Absorption Exit" 548 "System Inverter Enable" 549 "System AC Good" 550 "Anti Islanding Condition" 551 "Hibernate Timeout" 552 "External Sync Error" 553 "External Suspend Request" 554 "Engaging Charger" 555 "Engaging Gen Support" 556 "Grid Tie Engage Timeout" 557 "Gen Support Engage Timeout" 558 "Charge Engage Timeout" 559 "Inverter Engage Timeout" 560 "Charge Exit Timeout" 561 "Grid Support Entry Amps" 562 "Grid Support Exit Amps" 563 "Gen Support Entry Amps" 564 "Gen Support Exit Amps" 565 "Grid Support Entry Vdc" 566 "Grid Support Exit Vdc" 567 "Low Batt Cut Off Entry Vdc" 568 "Low Batt Recharge Vdc" 569 "Low Batt Cut Off Exit Vdc" 570 "Invert To Bypass Timeout" 571 "Force Charge" 572 "System Engage Bulk Charge" 441 "SPS Auto On External Shutdown Flt" 442 "SPS Auto Off Input Over Volt Flt" 443 "SPS Auto On Input Over Volt Flt" 444 "SPS Auto Off Input Over Volt Err" 445 "SPS Auto On Input Over Volt Err" 446 "SPS Auto Off Input Over Volt Wrn" 447 "SPS Auto On Input Over Volt Wrn" 448 "SPS Auto Off Output Over Volt Err" 449 "SPS Auto On Output Over Volt Err" 450 "SPS Auto Off Output Over Volt Wrn" 451 "SPS Auto On Output Over Volt Wrn" 452 "SPS Auto Off Output Under Volt Err" 453 "SPS Auto On Output Under Volt Err" 454 "SPS Auto Off Output Under Volt Wrn" 455 "SPS Auto On Output Under Volt Wrn" 456 "SPS Auto Off Output Over Curr Err" 457 "SPS Auto On Output Over Curr Err" 458 "SPS Auto Off Batt Over Temp Err" 459 "SPS Auto On Batt Over Temp Err" 460 "SPS Auto Off Batt Over Temp Wrn" 461 "SPS Auto On Batt Over Temp Wrn" 462 "SPS Auto Off Batt Under Temp Wrn" 463 "SPS Auto On Batt Under Temp Wrn" 464 "SPS Auto Off Heatsink Over Temp Err" 465 "SPS Auto On Heatsink Over Temp Err" 466 "SPS Auto Off Heatsink Over Temp Wrn" 467 "SPS Auto On Heatsink Over Temp Wrn" 468 "SPS Auto Off Ambient Over Temp Err" 469 "SPS Auto On Ambient Over Temp Err" 470 "SPS Auto Off Ambient Over Temp Wrn" 471 "SPS Auto On Ambient Over Temp Wrn" 472 "SPS Auto Off Capacitor Over Temp Err" 473 "SPS Auto On Capacitor Over Temp Err" 474 "SPS Auto Off Fan Flt" 475 "SPS Auto On Fan Flt" 476 "SPS Auto Off Fan Err" 477 "SPS Auto On Fan Err" 478 "SPS Auto Off Input Over Curr Err" 479 "SPS Auto On Input Over Curr Err" 480 "SPS Auto Off Output Over Curr Flt" 481 "SPS Auto On Output Over Curr Flt" 482 "SPS Auto Off Network PS Flt" 483 "SPS Auto On Network PS Flt" 484 "SPS Auto Off Setup Flt" 485 "SPS Auto On Setup Flt" 38 "Clear Command User Stats" 573 "AC Good Pending" 574 "Grid Safe" 585 "PLS Time In Float Ready" 575 "Power Conversion Fault" 576 "Low Battery Support Exit" 577 "Grid Support Exit" 578 "GFS Enable" 579 "GFS Disable" 580 "Force Sell" 486 "SPS Auto On Bulk Exit" 487 "SPS Auto Off Bulk Exit" 488 "SPS Auto On Absorption Exit" 489 "SPS Auto Off Absorption Exit" 490 "SPS Auto On State Of Charge Low" 491 "SPS Auto Off State Of Charge Low" 492 "SPS Auto On Time Of Day" 493 "SPS Auto Off Time Of Day" 581 "Sell Time Of Day Start" 582 "Sell Time Of Day Stop" 583 "Aux Port Time Of Day Start" 584 "Aux Port Time Of Day Stop" ;
VAL_ 2147553792 CfgType 0 "User" 1 "OEM" 2 "Factory" 3 "Reserved" ;
VAL_ 2147610660 OpState 1408 "Translating" 1409 "Disabled" ;
VAL_ 2147571968 CfgType 0 "User" 1 "OEM" 2 "Factory" 3 "Reserved" ;
VAL_ 2147571968 AllowedEnDis 0 "Off" 1 "On" 2 "Error" 3 "Unknown" ;
VAL_ 2147572224 CfgType 0 "User" 1 "OEM" 2 "Factory" 3 "Reserved" ;
VAL_ 2147572224 AllowedEnDis 0 "Off" 1 "On" 2 "Error" 3 "Unknown" ;
VAL_ 2147572992 SrcType 0 "Reserved" 1 "AC" 2 "DC" 3 "Generator" 4 "External Temperature" 5 "Internal Temperature" ;
VAL_ 2147572992 CfgType 0 "User" 1 "OEM" 2 "Factory" 3 "Reserved" ;
VAL_ 2147571712 XbDeviceFunction 128 "User Interface" 129 "Inverter Charger" 130 "Inverter" 131 "Charger" 132 "Battery Monitor" 133 "AGS" 134 "Diagnostic Terminal" 135 "Gateway" 136 "Energy Management System" 137 "Battery Management System" ;
VAL_ 2147571712 XbDeviceClass 30 "Power Management" ;
VAL_ 2147571712 OthDeviceFunction 128 "User Interface" 129 "Inverter Charger" 130 "Inverter" 131 "Charger" 132 "Battery Monitor" 133 "AGS" 134 "Diagnostic Terminal" 135 "Gateway" 136 "Energy Management System" 137 "Battery Management System" ;
VAL_ 2147571712 OthDeviceClass 30 "Power Management" ;
VAL_ 2147571712 CfgType 0 "User" 1 "OEM" 2 "Factory" 3 "Reserved" ;
VAL_ 2147572480 XbDeviceFunction 128 "User Interface" 129 "Inverter Charger" 130 "Inverter" 131 "Charger" 132 "Battery Monitor" 133 "AGS" 134 "Diagnostic Terminal" 135 "Gateway" 136 "Energy Management System" 137 "Battery Management System" ;
VAL_ 2147572480 XbDeviceClass 30 "Power Management" ;
VAL_ 2147572480 OthDeviceFunction 128 "User Interface" 129 "Inverter Charger" 130 "Inverter" 131 "Charger" 132 "Battery Monitor" 133 "AGS" 134 "Diagnostic Terminal" 135 "Gateway" 136 "Energy Management System" 137 "Battery Management System" ;
VAL_ 2147572480 OthDeviceClass 30 "Power Management" ;
VAL_ 2147572480 CfgType 0 "User" 1 "OEM" 2 "Factory" 3 "Reserved" ;
VAL_ 2147572736 Mode 0 "Power System Spoof" 1 "True Gateway" 2 "Disabled" ;
VAL_ 2147572736 CfgType 0 "User" 1 "OEM" 2 "Factory" 3 "Reserved" ;
VAL_ 2147576320 GvsEnDis 0 "Off" 1 "On" 2 "Reserved" 3 "No Change" ;
VAL_ 2147576320 CfgType 0 "User" 1 "OEM" 2 "Factory" 3 "Reserved" ;
VAL_ 2147576320 AcSrcId 0 "Invalid" 1 "None" 2 "Anonymous" 3 "Shore1" 4 "Shore2" 5 "Shore3" 6 "Shore4" 7 "Shore5" 8 "Shore6" 9 "Shore7" 10 "Shore8" 11 "Shore9" 12 "Shore10" 13 "Shore11" 14 "Shore12" 15 "Shore13" 16 "Shore14" 17 "Shore15" 18 "Shore16" 19 "Gen1" 20 "Gen2" 21 "Gen3" 22 "Gen4" 23 "Gen5" 24 "Gen6" 25 "Gen7" 26 "Gen8" 27 "Gen9" 28 "Gen10" 29 "Gen11" 30 "Gen12" 31 "Gen13" 32 "Gen14" 33 "Gen15" 34 "Gen16" 35 "AC1" 36 "AC2" 37 "AC3" 38 "AC4" 39 "AC5" 40 "AC6" 41 "AC7" 42 "AC8" 43 "AC9" 44 "AC10" 45 "AC11" 46 "AC12" 47 "AC13" 48 "AC14" 49 "AC15" 50 "AC16" 51 "AC Load1" 52 "AC Load2" 53 "AC Load3" 54 "AC Load4" 55 "AC Load5" 56 "AC Load6" 57 "AC Load7" 58 "AC Load8" 59 "AC Load9" 60 "AC Load10" 61 "AC Load11" 62 "AC Load12" 63 "AC Load13" 64 "AC Load14" 65 "AC Load15" 66 "AC Load16" 67 "Grid1" 68 "Grid2" 69 "Grid3" 70 "Grid4" 71 "Grid5" 72 "Grid6" 73 "Grid7" 74 "Grid8" 75 "Grid9" 76 "Grid10" 77 "Grid11" 78 "Grid12" 79 "Grid13" 80 "Grid14" 81 "Grid15" 82 "Grid16" 252 "All" 253 "Reserved" 254 "Out Of Range" 255 "Data Not Available Do Not Change" ;
VAL_ 2147575296 AcSrcId 0 "Invalid" 1 "None" 2 "Anonymous" 3 "Shore1" 4 "Shore2" 5 "Shore3" 6 "Shore4" 7 "Shore5" 8 "Shore6" 9 "Shore7" 10 "Shore8" 11 "Shore9" 12 "Shore10" 13 "Shore11" 14 "Shore12" 15 "Shore13" 16 "Shore14" 17 "Shore15" 18 "Shore16" 19 "Gen1" 20 "Gen2" 21 "Gen3" 22 "Gen4" 23 "Gen5" 24 "Gen6" 25 "Gen7" 26 "Gen8" 27 "Gen9" 28 "Gen10" 29 "Gen11" 30 "Gen12" 31 "Gen13" 32 "Gen14" 33 "Gen15" 34 "Gen16" 35 "AC1" 36 "AC2" 37 "AC3" 38 "AC4" 39 "AC5" 40 "AC6" 41 "AC7" 42 "AC8" 43 "AC9" 44 "AC10" 45 "AC11" 46 "AC12" 47 "AC13" 48 "AC14" 49 "AC15" 50 "AC16" 51 "AC Load1" 52 "AC Load2" 53 "AC Load3" 54 "AC Load4" 55 "AC Load5" 56 "AC Load6" 57 "AC Load7" 58 "AC Load8" 59 "AC Load9" 60 "AC Load10" 61 "AC Load11" 62 "AC Load12" 63 "AC Load13" 64 "AC Load14" 65 "AC Load15" 66 "AC Load16" 67 "Grid1" 68 "Grid2" 69 "Grid3" 70 "Grid4" 71 "Grid5" 72 "Grid6" 73 "Grid7" 74 "Grid8" 75 "Grid9" 76 "Grid10" 77 "Grid11" 78 "Grid12" 79 "Grid13" 80 "Grid14" 81 "Grid15" 82 "Grid16" 252 "All" 253 "Reserved" 254 "Out Of Range" 255 "Data Not Available Do Not Change" ;
VAL_ 2147576576 GridTieSocEnDis 0 "Off" 1 "On" 2 "Reserved" 3 "No Change" ;
VAL_ 2147576576 CfgType 0 "User" 1 "OEM" 2 "Factory" 3 "Reserved" ;
VAL_ 2147576576 AcSrcId 0 "Invalid" 1 "None" 2 "Anonymous" 3 "Shore1" 4 "Shore2" 5 "Shore3" 6 "Shore4" 7 "Shore5" 8 "Shore6" 9 "Shore7" 10 "Shore8" 11 "Shore9" 12 "Shore10" 13 "Shore11" 14 "Shore12" 15 "Shore13" 16 "Shore14" 17 "Shore15" 18 "Shore16" 19 "Gen1" 20 "Gen2" 21 "Gen3" 22 "Gen4" 23 "Gen5" 24 "Gen6" 25 "Gen7" 26 "Gen8" 27 "Gen9" 28 "Gen10" 29 "Gen11" 30 "Gen12" 31 "Gen13" 32 "Gen14" 33 "Gen15" 34 "Gen16" 35 "AC1" 36 "AC2" 37 "AC3" 38 "AC4" 39 "AC5" 40 "AC6" 41 "AC7" 42 "AC8" 43 "AC9" 44 "AC10" 45 "AC11" 46 "AC12" 47 "AC13" 48 "AC14" 49 "AC15" 50 "AC16" 51 "AC Load1" 52 "AC Load2" 53 "AC Load3" 54 "AC Load4" 55 "AC Load5" 56 "AC Load6" 57 "AC Load7" 58 "AC Load8" 59 "AC Load9" 60 "AC Load10" 61 "AC Load11" 62 "AC Load12" 63 "AC Load13" 64 "AC Load14" 65 "AC Load15" 66 "AC Load16" 67 "Grid1" 68 "Grid2" 69 "Grid3" 70 "Grid4" 71 "Grid5" 72 "Grid6" 73 "Grid7" 74 "Grid8" 75 "Grid9" 76 "Grid10" 77 "Grid11" 78 "Grid12" 79 "Grid13" 80 "Grid14" 81 "Grid15" 82 "Grid16" 252 "All" 253 "Reserved" 254 "Out Of Range" 255 "Data Not Available Do Not Change" ;
VAL_ 2147598336 SellMode 0 "Automatic" 1 "Manual" ;
VAL_ 2147598336 PeakLoadShavingEnDis 0 "Off" 1 "On" 2 "Error" 3 "Unknown" ;
VAL_ 2147598336 GridTieEnDis 0 "Off" 1 "On" 2 "Reserved" 3 "No Change" ;
VAL_ 2147598336 CfgType 0 "User" 1 "OEM" 2 "Factory" 3 "Reserved" ;
VAL_ 2147598336 AntiIslandingEnDis 0 "Off" 1 "On" 2 "Error" 3 "Unknown" ;
VAL_ 2147598336 AcSrcId 0 "Invalid" 1 "None" 2 "Anonymous" 3 "Shore1" 4 "Shore2" 5 "Shore3" 6 "Shore4" 7 "Shore5" 8 "Shore6" 9 "Shore7" 10 "Shore8" 11 "Shore9" 12 "Shore10" 13 "Shore11" 14 "Shore12" 15 "Shore13" 16 "Shore14" 17 "Shore15" 18 "Shore16" 19 "Gen1" 20 "Gen2" 21 "Gen3" 22 "Gen4" 23 "Gen5" 24 "Gen6" 25 "Gen7" 26 "Gen8" 27 "Gen9" 28 "Gen10" 29 "Gen11" 30 "Gen12" 31 "Gen13" 32 "Gen14" 33 "Gen15" 34 "Gen16" 35 "AC1" 36 "AC2" 37 "AC3" 38 "AC4" 39 "AC5" 40 "AC6" 41 "AC7" 42 "AC8" 43 "AC9" 44 "AC10" 45 "AC11" 46 "AC12" 47 "AC13" 48 "AC14" 49 "AC15" 50 "AC16" 51 "AC Load1" 52 "AC Load2" 53 "AC Load3" 54 "AC Load4" 55 "AC Load5" 56 "AC Load6" 57 "AC Load7" 58 "AC Load8" 59 "AC Load9" 60 "AC Load10" 61 "AC Load11" 62 "AC Load12" 63 "AC Load13" 64 "AC Load14" 65 "AC Load15" 66 "AC Load16" 67 "Grid1" 68 "Grid2" 69 "Grid3" 70 "Grid4" 71 "Grid5" 72 "Grid6" 73 "Grid7" 74 "Grid8" 75 "Grid9" 76 "Grid10" 77 "Grid11" 78 "Grid12" 79 "Grid13" 80 "Grid14" 81 "Grid15" 82 "Grid16" 252 "All" 253 "Reserved" 254 "Out Of Range" 255 "Data Not Available Do Not Change" ;
VAL_ 2147598848 DcSrcId 0 "Invalid" 1 "None" 2 "Anonymous" 3 "HouseBatBank1" 4 "HouseBatBank2" 5 "HouseBatBank3" 6 "HouseBatBank4" 7 "HouseBatBank5" 8 "HouseBatBank6" 9 "StartBatBank1" 10 "StartBatBank2" 11 "StartBatBank3" 12 "StartBatBank4" 13 "StartBatBank5" 14 "StartBatBank6" 21 "SolarArray1" 22 "SolarArray2" 23 "SolarArray3" 24 "SolarArray4" 25 "SolarArray5" 26 "SolarArray6" 27 "SolarArray7" 28 "SolarArray8" 29 "SolarArray9" 30 "SolarArray10" 31 "SolarArray11" 32 "SolarArray12" 33 "SolarArray13" 34 "SolarArray14" 35 "SolarArray15" 36 "SolarArray16" 252 "All" 253 "Reserved" 254 "Out of Range" 255 "Data Not Available Do Not Change" ;
VAL_ 2147598848 AcSrcId 0 "Invalid" 1 "None" 2 "Anonymous" 3 "Shore1" 4 "Shore2" 5 "Shore3" 6 "Shore4" 7 "Shore5" 8 "Shore6" 9 "Shore7" 10 "Shore8" 11 "Shore9" 12 "Shore10" 13 "Shore11" 14 "Shore12" 15 "Shore13" 16 "Shore14" 17 "Shore15" 18 "Shore16" 19 "Gen1" 20 "Gen2" 21 "Gen3" 22 "Gen4" 23 "Gen5" 24 "Gen6" 25 "Gen7" 26 "Gen8" 27 "Gen9" 28 "Gen10" 29 "Gen11" 30 "Gen12" 31 "Gen13" 32 "Gen14" 33 "Gen15" 34 "Gen16" 35 "AC1" 36 "AC2" 37 "AC3" 38 "AC4" 39 "AC5" 40 "AC6" 41 "AC7" 42 "AC8" 43 "AC9" 44 "AC10" 45 "AC11" 46 "AC12" 47 "AC13" 48 "AC14" 49 "AC15" 50 "AC16" 51 "AC Load1" 52 "AC Load2" 53 "AC Load3" 54 "AC Load4" 55 "AC Load5" 56 "AC Load6" 57 "AC Load7" 58 "AC Load8" 59 "AC Load9" 60 "AC Load10" 61 "AC Load11" 62 "AC Load12" 63 "AC Load13" 64 "AC Load14" 65 "AC Load15" 66 "AC Load16" 67 "Grid1" 68 "Grid2" 69 "Grid3" 70 "Grid4" 71 "Grid5" 72 "Grid6" 73 "Grid7" 74 "Grid8" 75 "Grid9" 76 "Grid10" 77 "Grid11" 78 "Grid12" 79 "Grid13" 80 "Grid14" 81 "Grid15" 82 "Grid16" 252 "All" 253 "Reserved" 254 "Out Of Range" 255 "Data Not Available Do Not Change" ;
VAL_ 2147574016 GfsEnDis 0 "Off" 1 "On" 2 "Reserved" 3 "No Change" ;
VAL_ 2147574016 CfgType 0 "User" 1 "OEM" 2 "Factory" 3 "Reserved" ;
VAL_ 2147574016 AcSrcId 0 "Invalid" 1 "None" 2 "Anonymous" 3 "Shore1" 4 "Shore2" 5 "Shore3" 6 "Shore4" 7 "Shore5" 8 "Shore6" 9 "Shore7" 10 "Shore8" 11 "Shore9" 12 "Shore10" 13 "Shore11" 14 "Shore12" 15 "Shore13" 16 "Shore14" 17 "Shore15" 18 "Shore16" 19 "Gen1" 20 "Gen2" 21 "Gen3" 22 "Gen4" 23 "Gen5" 24 "Gen6" 25 "Gen7" 26 "Gen8" 27 "Gen9" 28 "Gen10" 29 "Gen11" 30 "Gen12" 31 "Gen13" 32 "Gen14" 33 "Gen15" 34 "Gen16" 35 "AC1" 36 "AC2" 37 "AC3" 38 "AC4" 39 "AC5" 40 "AC6" 41 "AC7" 42 "AC8" 43 "AC9" 44 "AC10" 45 "AC11" 46 "AC12" 47 "AC13" 48 "AC14" 49 "AC15" 50 "AC16" 51 "AC Load1" 52 "AC Load2" 53 "AC Load3" 54 "AC Load4" 55 "AC Load5" 56 "AC Load6" 57 "AC Load7" 58 "AC Load8" 59 "AC Load9" 60 "AC Load10" 61 "AC Load11" 62 "AC Load12" 63 "AC Load13" 64 "AC Load14" 65 "AC Load15" 66 "AC Load16" 67 "Grid1" 68 "Grid2" 69 "Grid3" 70 "Grid4" 71 "Grid5" 72 "Grid6" 73 "Grid7" 74 "Grid8" 75 "Grid9" 76 "Grid10" 77 "Grid11" 78 "Grid12" 79 "Grid13" 80 "Grid14" 81 "Grid15" 82 "Grid16" 252 "All" 253 "Reserved" 254 "Out Of Range" 255 "Data Not Available Do Not Change" ;
VAL_ 2147564288 ResultCode 0 "No Error" 1 "Invalid File DL Inf" 2 "Invalid File DL Blk" 3 "Blk Write Err" 4 "File CRC Err" ;
VAL_ 2147564288 OpState 0 "Wait File DL Inf" 1 "Wait File DL Blk" 2 "Writing Blk" 3 "Checking File" 4 "Wait Reboot" 5 "Erasing Blk" ;
VAL_ 2147561984 SwModId 0 "XanBus" 1 "OperatingSystem" 2 "Application" 3 "Loader" 4 "Reserved2" 5 "Other1" 6 "Other2" 253 "Reserved" 254 "Out Of Range" 255 "Data Not Available Do Not Change" ;
VAL_ 2147561984 DeviceFunction 128 "User Interface" 129 "Inverter Charger" 130 "Inverter" 131 "Charger" 132 "Battery Monitor" 133 "AGS" 134 "Diagnostic Terminal" 135 "Gateway" 136 "Energy Management System" 137 "Battery Management System" ;
VAL_ 2147567872 FeatureId 0 "Invalid" 1 "Remote Power Off" 2 "No Load Derating" 3 "Restore Invert Mode On Power Up" 4 "Prot Input Over Voltage" 5 "Prot External Shutdown" 6 "Prot Input Under Voltage" 7 "Prot Output Over Voltage" 8 "Prot Fast Output Under Voltage" 9 "Prot Fast Output Over Current" 10 "Prot Slow Output Over Current" 11 "Prot HS Over Temperature" 12 "Prot Ambient Over Temperature" 13 "Prot Capacitor Over Temperature" 14 "Prot Battery Over Temperature" 15 "Prot Ground Fault" 16 "Prot Slow Output Under Voltage" 19 "Main Fan Enable" 20 "Auxiliary Fan Enable" 21 "Digital Control Enable" 22 "Prot Input Over Voltage 2" 17 "Prot Fan Err" 18 "Prot Fan Flt" 23 "Network Power Night Time Disable" 24 "Low Power At Night Enable" 25 "Temperature Derating Enable" 26 "Cli Over Xanbus Enable" 27 "Frequency Select Enable" 28 "Long Sell Delay" 29 "Gen Balance" 30 "Remote Sell" 31 "AC Coupling Frequency Shift" 32 "Multiple Battery Energy Balance" 33 "External Transfer Switch" 34 "Time In Float" 35 "Store Invert State" 36 "Transient Over Voltage" 37 "Enhanced AC Support" 38 "California Rule21" ;
VAL_ 2147567872 FeatureEnDis 0 "Off" 1 "On" 2 "Reserved" 3 "No Change" ;
VAL_ 2147567872 CfgType 0 "User" 1 "OEM" 2 "Factory" 3 "Reserved" ;
VAL_ 2147612872 FaultType 0 "Auto Reset Escalating Fault" 1 "Auto Reset Non Escalating Fault" 2 "Manual Fault" 5 "Reserved" 6 "Out Of Range" 7 "No Change Data NA" ;
VAL_ 2147612872 FaultId 73 "DC Over Current Shutdown 2" 74 "DC Over Voltage Shutdown 3" 0 "Transistor Over Temperature Shutdown 1" 1 "Transistor Over Temperature Shutdown 2" 2 "Capacitor Over Temperature Shutdown 1" 3 "Transformer Over Temperature Shutdown 1" 4 "Battery Over Temperature Shutdown 1" 5 "Ambient Over Temperature Shutdown 1" 6 "AC Output Overload Shutdown 1" 7 "AC Output Overload Peak Current Shutdown 1" 8 "Neutral Loss Shutdown" 9 "DC Over Voltage Shutdown 1" 10 "DC Under Voltage Immediate Shutdown 1" 11 "DC Under Voltage Shutdown 1" 12 "AC Input Line 1 Over Voltage Shutdown" 13 "AC Input Line 1 Under Voltage Shutdown" 14 "AC Input Line 2 Over Voltage Shutdown" 15 "AC Input Line 2 Under Voltage Shutdown" 16 "AC Input Line 1 Over Frequency Shutdown" 17 "AC Input Line 1 Under Frequency Shutdown" 18 "AC Input Line 2 Over Frequency Shutdown" 19 "AC Input Line 2 Under Frequency Shutdown" 22 "ADC Conversion Timeout" 23 "AC Output Over Voltage Shutdown 1" 24 "AC Output Under Voltage Shutdown 1" 25 "APS Over Voltage" 26 "APS Under Voltage" 27 "OPS Over Voltage" 28 "OPS Under Voltage" 29 "AC Backfeed Shutdown" 30 "Battery Under Temperature" 31 "Echo Charger Short Circuit" 32 "Echo Charger Reverse Polarity" 33 "Echo Charger Input Over Voltage" 34 "Echo Charger Input Under Voltage" 35 "Echo Charger Over Temperature" 36 "Echo Charger Under Temperature" 37 "Echo Charger Not Communicating" 40 "Lost Interprocessor Communications" 41 "Dead Battery Charge Timeout" 42 "AC Output Over Voltage Shutdown 2" 43 "AC Output Under Voltage Shutdown 2" 44 "Generator Line 1 Input Over Voltage Shutdown" 45 "Generator Line 1 Input Under Voltage Shutdown" 46 "Generator Line 2 Input Over Voltage Shutdown" 47 "Generator Line 2 Input Under Voltage Shutdown" 48 "Generator Line 1 Input Over Frequency Shutdown" 49 "Generator Line 1 Input Under Frequency Shutdown" 50 "Generator Line 2 Input Over Frequency Shutdown" 51 "Generator Line 2 Input Under Frequency Shutdown" 52 "AC Input L1 L2 120 Over Frequency Shutdown" 53 "AC Input L1 L2 120 Under Frequency Shutdown" 54 "APS 1 Off" 55 "Heatsink 1 Over Temperature Shutdown" 56 "Ground Fault" 57 "External Shutdown" 58 "AC Output 1 Voltage Shutdown" 59 "AC Output 1 Frequency Shutdown" 60 "AC Output 1 Impedance Shutdown" 61 "Reconnecting 1" 62 "DC-DC 1 Saturated" 63 "User Shutdown" 64 "Neutral Over Current 1" 65 "Over Voltage Antiislanding" 66 "Under Voltage Antiislanding" 67 "Over Frequency Antiislanding" 68 "Under Frequency Antiislanding" 69 "Battery Conflicting Setup" 70 "DC Over Voltage Shutdown 2" 71 "DC Over Current Shutdown" 72 "SPS Overload" 200 "Max Start Retries" 201 "Unable to Stop Generator" 203 "Gen Stop by Ext Shutdown" 250 "Clock Not Set" 251 "Device Lost" 252 "New Device" 500 "Silicon Serial ID Failure" 501 "Non-Volatile Error" 502 "Watchdog Reset" 503 "Real-time Clock Failure" 504 "Lost Network Connection" 505 "Controller Failure" 506 "Wrong Fault Identifier" 507 "Wrong Warning Identifier" 508 "Invalid Interrupt" 599 "Associations Invalid" 8189 "Reserved" 8190 "Out Of Range" 8191 "No Change Data NA" 75 "Fan Problem 1" 76 "Fan Problem 2" 77 "DC Over Current Shutdown 3" 78 "DC Over Current Shutdown 4" 79 "Fan Problem 3" 80 "Fan Problem 4" 81 "Fan Problem 5" 82 "Network Power Supply Failure" 83 "Battery Discharge Over Current" ;
VAL_ 2147610643 FaultType 0 "Auto Reset Escalating Fault" 1 "Auto Reset Non Escalating Fault" 2 "Manual Fault" 5 "Reserved" 6 "Out Of Range" 7 "No Change Data NA" ;
VAL_ 2147610643 FaultId 73 "DC Over Current Shutdown 2" 74 "DC Over Voltage Shutdown 3" 0 "Transistor Over Temperature Shutdown 1" 1 "Transistor Over Temperature Shutdown 2" 2 "Capacitor Over Temperature Shutdown 1" 3 "Transformer Over Temperature Shutdown 1" 4 "Battery Over Temperature Shutdown 1" 5 "Ambient Over Temperature Shutdown 1" 6 "AC Output Overload Shutdown 1" 7 "AC Output Overload Peak Current Shutdown 1" 8 "Neutral Loss Shutdown" 9 "DC Over Voltage Shutdown 1" 10 "DC Under Voltage Immediate Shutdown 1" 11 "DC Under Voltage Shutdown 1" 12 "AC Input Line 1 Over Voltage Shutdown" 13 "AC Input Line 1 Under Voltage Shutdown" 14 "AC Input Line 2 Over Voltage Shutdown" 15 "AC Input Line 2 Under Voltage Shutdown" 16 "AC Input Line 1 Over Frequency Shutdown" 17 "AC Input Line 1 Under Frequency Shutdown" 18 "AC Input Line 2 Over Frequency Shutdown" 19 "AC Input Line 2 Under Frequency Shutdown" 22 "ADC Conversion Timeout" 23 "AC Output Over Voltage Shutdown 1" 24 "AC Output Under Voltage Shutdown 1" 25 "APS Over Voltage" 26 "APS Under Voltage" 27 "OPS Over Voltage" 28 "OPS Under Voltage" 29 "AC Backfeed Shutdown" 30 "Battery Under Temperature" 31 "Echo Charger Short Circuit" 32 "Echo Charger Reverse Polarity" 33 "Echo Charger Input Over Voltage" 34 "Echo Charger Input Under Voltage" 35 "Echo Charger Over Temperature" 36 "Echo Charger Under Temperature" 37 "Echo Charger Not Communicating" 40 "Lost Interprocessor Communications" 41 "Dead Battery Charge Timeout" 42 "AC Output Over Voltage Shutdown 2" 43 "AC Output Under Voltage Shutdown 2" 44 "Generator Line 1 Input Over Voltage Shutdown" 45 "Generator Line 1 Input Under Voltage Shutdown" 46 "Generator Line 2 Input Over Voltage Shutdown" 47 "Generator Line 2 Input Under Voltage Shutdown" 48 "Generator Line 1 Input Over Frequency Shutdown" 49 "Generator Line 1 Input Under Frequency Shutdown" 50 "Generator Line 2 Input Over Frequency Shutdown" 51 "Generator Line 2 Input Under Frequency Shutdown" 52 "AC Input L1 L2 120 Over Frequency Shutdown" 53 "AC Input L1 L2 120 Under Frequency Shutdown" 54 "APS 1 Off" 55 "Heatsink 1 Over Temperature Shutdown" 56 "Ground Fault" 57 "External Shutdown" 58 "AC Output 1 Voltage Shutdown" 59 "AC Output 1 Frequency Shutdown" 60 "AC Output 1 Impedance Shutdown" 61 "Reconnecting 1" 62 "DC-DC 1 Saturated" 63 "User Shutdown" 64 "Neutral Over Current 1" 65 "Over Voltage Antiislanding" 66 "Under Voltage Antiislanding" 67 "Over Frequency Antiislanding" 68 "Under Frequency Antiislanding" 69 "Battery Conflicting Setup" 70 "DC Over Voltage Shutdown 2" 71 "DC Over Current Shutdown" 72 "SPS Overload" 200 "Max Start Retries" 201 "Unable to Stop Generator" 203 "Gen Stop by Ext Shutdown" 250 "Clock Not Set" 251 "Device Lost" 252 "New Device" 500 "Silicon Serial ID Failure" 501 "Non-Volatile Error" 502 "Watchdog Reset" 503 "Real-time Clock Failure" 504 "Lost Network Connection" 505 "Controller Failure" 506 "Wrong Fault Identifier" 507 "Wrong Warning Identifier" 508 "Invalid Interrupt" 599 "Associations Invalid" 8189 "Reserved" 8190 "Out Of Range" 8191 "No Change Data NA" 75 "Fan Problem 1" 76 "Fan Problem 2" 77 "DC Over Current Shutdown 3" 78 "DC Over Current Shutdown 4" 79 "Fan Problem 3" 80 "Fan Problem 4" 81 "Fan Problem 5" 82 "Network Power Supply Failure" 83 "Battery Discharge Over Current" ;
VAL_ 2147610827 FanId 0 "Main" 1 "Auxiliary" ;
VAL_ 2147610828 FanId 0 "Main" 1 "Auxiliary" ;
VAL_ 2147610636 TempSensId 0 "Battery 1" 1 "Battery 2" 2 "Battery 3" 3 "Battery 4" 4 "Battery 5" 5 "Battery 6" 10 "Ambient 1" 11 "Ambient 2" 12 "Ambient 3" 13 "Ambient 4" 14 "Shunt 1" 15 "Shunt 2" 16 "Shunt 3" 17 "Shunt 4" 253 "Reserved" 254 "Out of Range" 255 "Data Not Available Do Not Change" ;
VAL_ 2147610823 TempSensId 0 "Battery 1" 1 "Battery 2" 2 "Battery 3" 3 "Battery 4" 4 "Battery 5" 5 "Battery 6" 10 "Ambient 1" 11 "Ambient 2" 12 "Ambient 3" 13 "Ambient 4" 14 "Shunt 1" 15 "Shunt 2" 16 "Shunt 3" 17 "Shunt 4" 253 "Reserved" 254 "Out of Range" 255 "Data Not Available Do Not Change" ;
VAL_ 2147610823 PreviousPeriod 0 "Life" 1 "Year" 2 "Month" 3 "Week" 4 "Day" 5 "Hour" 6 "User" ;
VAL_ 2147554048 TempSensId 0 "Battery 1" 1 "Battery 2" 2 "Battery 3" 3 "Battery 4" 4 "Battery 5" 5 "Battery 6" 10 "Ambient 1" 11 "Ambient 2" 12 "Ambient 3" 13 "Ambient 4" 14 "Shunt 1" 15 "Shunt 2" 16 "Shunt 3" 17 "Shunt 4" 253 "Reserved" 254 "Out of Range" 255 "Data Not Available Do Not Change" ;
VAL_ 2147554048 RefEvtId 436 "SPS Auto Off Array V Low" 437 "SPS Auto On Array V Low" 438 "SPS Auto Off Ground Flt" 439 "SPS Auto On Ground Flt" 440 "SPS Auto Off External Shutdown Flt" 0 "None" 10 "Control Command Hibernate" 11 "Control Command Safe" 12 "Control Command Power Save" 13 "Control Command Operating" 14 "Control Command Diagnostic" 15 "Control Command Last Mode" 20 "Reset Command Reboot" 21 "Reset Command Download" 22 "Reset Command Oem" 23 "Reset Command Factory" 24 "Reset Command Reboot Clear Nv" 25 "Powered Up" 30 "Clear Command Active Faults" 31 "Clear Command Fault Log" 32 "Clear Command Active Warns" 33 "Clear Command Warn Log" 34 "Clear Command State Event Log" 35 "Clear Command Comm Stats" 36 "Clear Command Stats" 37 "Clear Command All" 40 "Date Time Configured" 50 "Warn Cleared" 51 "Fault Cleared" 52 "Fault Set" 60 "User Cfg Changed" 61 "Oem Cfg Changed" 70 "Triggered Fault" 250 "Shutdown Threshold" 251 "Shutdown Hysteresis" 252 "Warning Threshold" 253 "Warning Hysteresis" 254 "Transfer Threshold" 255 "Fan 0 Threshold" 256 "Fan 10 Threshold" 257 "Fan 20 Threshold" 258 "Fan 30 Threshold" 259 "Fan 40 Threshold" 260 "Fan 50 Threshold" 261 "Fan 60 Threshold" 262 "Fan 70 Threshold" 263 "Fan 80 Threshold" 264 "Fan 90 Threshold" 265 "Fan 100 Threshold" 266 "Relay Open Threshold" 267 "Relay Close Threshold" 268 "Charger Derating Ac In V" 269 "Charger Derating Ac In I" 270 "Charger Derating Ext Temp" 271 "Charger Derating Int Temp" 272 "Charger Derating Ripple V" 273 "Lost Ac Threshold" 274 "Lost Ac Hysteresis" 275 "Imm Shutdown Threshold" 276 "Imm Shutdown Hysteresis" 277 "Charger Shutdown Threshold" 278 "Charger Shutdown Hysteresis" 279 "Charger Warning Threshold" 280 "Charger Warning Hysteresis" 281 "Inverter Shutdown Threshold" 282 "Inverter Shutdown Hysteresis" 283 "Inverter Warning Threshold" 284 "Inverter Warning Hysteresis" 285 "Charger Derating Temp Start Point" 286 "Charger Derating Temp End Point" 287 "Charger Recharge Threshold" 300 "Ags Exercise Start" 301 "Ags Exercise Stop" 302 "Ags Quiet Time Begin" 303 "Ags Quiet Time End" 304 "Ags Battery Soc Start" 305 "Ags Battery Soc Stop" 306 "Ags Dc V Start" 307 "Ags Dc V Stop" 308 "Ags Ac I Start" 309 "Ags Ac I Stop" 310 "Ags Contact Start" 311 "Ags Contact Stop" 312 "Ags Float Stop" 313 "Ags Absorp Stop" 314 "Ags Manual On" 315 "Ags Manual Off" 316 "Ags Auto" 317 "Ags External On" 318 "Ags External Off" 319 "Gen External On" 320 "Gen External Off" 321 "Ags External Shutdown" 322 "Ags Auto Off" 323 "Ags Dc I Start" 324 "Ags Dc I Stop" 325 "Ags Ac Power Start" 326 "Ags Ac Power Stop" 400 "Sps Manual Off" 401 "Sps Manual On" 410 "Sps Auto Off" 411 "Sps Auto On" 420 "Sps Auto Off Batt V Low" 421 "Sps Auto On Batt V Low" 422 "Sps Auto Off Batt V High" 423 "Sps Auto On Batt V High" 424 "Sps Auto Off Array V High" 425 "Sps Auto On Array V High" 426 "Sps Auto Off Batt Temp Low" 427 "Sps Auto On Batt Temp Low" 428 "Sps Auto Off Batt Temp High" 429 "Sps Auto On Batt Temp High" 430 "Sps Auto Off Heat Sink Temp High" 431 "Sps Auto On Heat Sink Temp High" 432 "Sps Auto Off Fault" 433 "Sps Auto On Fault" 434 "Aps Check Timeout" 435 "Aps Qualify Timeout" 512 "Resume From Safe" 513 "AC Fault Set" 514 "Invert Fault Set" 515 "Charge Fault Set" 516 "Charger Enable" 517 "Charger Disable" 518 "Inverter Enable" 519 "Inverter Disable" 520 "Charge Suspend On" 521 "Charge Suspend Off" 522 "AC Good" 523 "AC Bad" 524 "Load Sense Enable" 525 "Load Sense Active" 526 "Invert Active" 527 "Bulk Exit" 528 "Absorption Exit" 529 "Float Exit" 530 "Float 3-Stage Set" 531 "Float 2-Stage Set" 532 "Equalize Enable" 533 "Equalize Disable" 534 "Equalize Exit" 535 "Load Sense Disable" 536 "Sell To Grid Enabled" 537 "Sell To Grid Disabled" 538 "Grid Support Enable" 539 "Grid Support Disable" 540 "Gen Support Enable" 541 "Gen Support Disable" 542 "Peak Load Shaving Enable" 543 "Peak Load Shaving Disable" 544 "Peak Load Shaving Tod Start" 545 "Peak Load Shaving Tod Stop" 546 "Unit Off" 547 "System Absorption Exit" 548 "System Inverter Enable" 549 "System AC Good" 550 "Anti Islanding Condition" 551 "Hibernate Timeout" 552 "External Sync Error" 553 "External Suspend Request" 554 "Engaging Charger" 555 "Engaging Gen Support" 556 "Grid Tie Engage Timeout" 557 "Gen Support Engage Timeout" 558 "Charge Engage Timeout" 559 "Inverter Engage Timeout" 560 "Charge Exit Timeout" 561 "Grid Support Entry Amps" 562 "Grid Support Exit Amps" 563 "Gen Support Entry Amps" 564 "Gen Support Exit Amps" 565 "Grid Support Entry Vdc" 566 "Grid Support Exit Vdc" 567 "Low Batt Cut Off Entry Vdc" 568 "Low Batt Recharge Vdc" 569 "Low Batt Cut Off Exit Vdc" 570 "Invert To Bypass Timeout" 571 "Force Charge" 572 "System Engage Bulk Charge" 441 "SPS Auto On External Shutdown Flt" 442 "SPS Auto Off Input Over Volt Flt" 443 "SPS Auto On Input Over Volt Flt" 444 "SPS Auto Off Input Over Volt Err" 445 "SPS Auto On Input Over Volt Err" 446 "SPS Auto Off Input Over Volt Wrn" 447 "SPS Auto On Input Over Volt Wrn" 448 "SPS Auto Off Output Over Volt Err" 449 "SPS Auto On Output Over Volt Err" 450 "SPS Auto Off Output Over Volt Wrn" 451 "SPS Auto On Output Over Volt Wrn" 452 "SPS Auto Off Output Under Volt Err" 453 "SPS Auto On Output Under Volt Err" 454 "SPS Auto Off Output Under Volt Wrn" 455 "SPS Auto On Output Under Volt Wrn" 456 "SPS Auto Off Output Over Curr Err" 457 "SPS Auto On Output Over Curr Err" 458 "SPS Auto Off Batt Over Temp Err" 459 "SPS Auto On Batt Over Temp Err" 460 "SPS Auto Off Batt Over Temp Wrn" 461 "SPS Auto On Batt Over Temp Wrn" 462 "SPS Auto Off Batt Under Temp Wrn" 463 "SPS Auto On Batt Under Temp Wrn" 464 "SPS Auto Off Heatsink Over Temp Err" 465 "SPS Auto On Heatsink Over Temp Err" 466 "SPS Auto Off Heatsink Over Temp Wrn" 467 "SPS Auto On Heatsink Over Temp Wrn" 468 "SPS Auto Off Ambient Over Temp Err" 469 "SPS Auto On Ambient Over Temp Err" 470 "SPS Auto Off Ambient Over Temp Wrn" 471 "SPS Auto On Ambient Over Temp Wrn" 472 "SPS Auto Off Capacitor Over Temp Err" 473 "SPS Auto On Capacitor Over Temp Err" 474 "SPS Auto Off Fan Flt" 475 "SPS Auto On Fan Flt" 476 "SPS Auto Off Fan Err" 477 "SPS Auto On Fan Err" 478 "SPS Auto Off Input Over Curr Err" 479 "SPS Auto On Input Over Curr Err" 480 "SPS Auto Off Output Over Curr Flt" 481 "SPS Auto On Output Over Curr Flt" 482 "SPS Auto Off Network PS Flt" 483 "SPS Auto On Network PS Flt" 484 "SPS Auto Off Setup Flt" 485 "SPS Auto On Setup Flt" 38 "Clear Command User Stats" 573 "AC Good Pending" 574 "Grid Safe" 585 "PLS Time In Float Ready" 575 "Power Conversion Fault" 576 "Low Battery Support Exit" 577 "Grid Support Exit" 578 "GFS Enable" 579 "GFS Disable" 580 "Force Sell" 486 "SPS Auto On Bulk Exit" 487 "SPS Auto Off Bulk Exit" 488 "SPS Auto On Absorption Exit" 489 "SPS Auto Off Absorption Exit" 490 "SPS Auto On State Of Charge Low" 491 "SPS Auto Off State Of Charge Low" 492 "SPS Auto On Time Of Day" 493 "SPS Auto Off Time Of Day" 581 "Sell Time Of Day Start" 582 "Sell Time Of Day Stop" 583 "Aux Port Time Of Day Start" 584 "Aux Port Time Of Day Stop" ;
VAL_ 2147554048 EvtId 436 "SPS Auto Off Array V Low" 437 "SPS Auto On Array V Low" 438 "SPS Auto Off Ground Flt" 439 "SPS Auto On Ground Flt" 440 "SPS Auto Off External Shutdown Flt" 0 "None" 10 "Control Command Hibernate" 11 "Control Command Safe" 12 "Control Command Power Save" 13 "Control Command Operating" 14 "Control Command Diagnostic" 15 "Control Command Last Mode" 20 "Reset Command Reboot" 21 "Reset Command Download" 22 "Reset Command Oem" 23 "Reset Command Factory" 24 "Reset Command Reboot Clear Nv" 25 "Powered Up" 30 "Clear Command Active Faults" 31 "Clear Command Fault Log" 32 "Clear Command Active Warns" 33 "Clear Command Warn Log" 34 "Clear Command State Event Log" 35 "Clear Command Comm Stats" 36 "Clear Command Stats" 37 "Clear Command All" 40 "Date Time Configured" 50 "Warn Cleared" 51 "Fault Cleared" 52 "Fault Set" 60 "User Cfg Changed" 61 "Oem Cfg Changed" 70 "Triggered Fault" 250 "Shutdown Threshold" 251 "Shutdown Hysteresis" 252 "Warning Threshold" 253 "Warning Hysteresis" 254 "Transfer Threshold" 255 "Fan 0 Threshold" 256 "Fan 10 Threshold" 257 "Fan 20 Threshold" 258 "Fan 30 Threshold" 259 "Fan 40 Threshold" 260 "Fan 50 Threshold" 261 "Fan 60 Threshold" 262 "Fan 70 Threshold" 263 "Fan 80 Threshold" 264 "Fan 90 Threshold" 265 "Fan 100 Threshold" 266 "Relay Open Threshold" 267 "Relay Close Threshold" 268 "Charger Derating Ac In V" 269 "Charger Derating Ac In I" 270 "Charger Derating Ext Temp" 271 "Charger Derating Int Temp" 272 "Charger Derating Ripple V" 273 "Lost Ac Threshold" 274 "Lost Ac Hysteresis" 275 "Imm Shutdown Threshold" 276 "Imm Shutdown Hysteresis" 277 "Charger Shutdown Threshold" 278 "Charger Shutdown Hysteresis" 279 "Charger Warning Threshold" 280 "Charger Warning Hysteresis" 281 "Inverter Shutdown Threshold" 282 "Inverter Shutdown Hysteresis" 283 "Inverter Warning Threshold" 284 "Inverter Warning Hysteresis" 285 "Charger Derating Temp Start Point" 286 "Charger Derating Temp End Point" 287 "Charger Recharge Threshold" 300 "Ags Exercise Start" 301 "Ags Exercise Stop" 302 "Ags Quiet Time Begin" 303 "Ags Quiet Time End" 304 "Ags Battery Soc Start" 305 "Ags Battery Soc Stop" 306 "Ags Dc V Start" 307 "Ags Dc V Stop" 308 "Ags Ac I Start" 309 "Ags Ac I Stop" 310 "Ags Contact Start" 311 "Ags Contact Stop" 312 "Ags Float Stop" 313 "Ags Absorp Stop" 314 "Ags Manual On" 315 "Ags Manual Off" 316 "Ags Auto" 317 "Ags External On" 318 "Ags External Off" 319 "Gen External On" 320 "Gen External Off" 321 "Ags External Shutdown" 322 "Ags Auto Off" 323 "Ags Dc I Start" 324 "Ags Dc I Stop" 325 "Ags Ac Power Start" 326 "Ags Ac Power Stop" 400 "Sps Manual Off" 401 "Sps Manual On" 410 "Sps Auto Off" 411 "Sps Auto On" 420 "Sps Auto Off Batt V Low" 421 "Sps Auto On Batt V Low" 422 "Sps Auto Off Batt V High" 423 "Sps Auto On Batt V High" 424 "Sps Auto Off Array V High" 425 "Sps Auto On Array V High" 426 "Sps Auto Off Batt Temp Low" 427 "Sps Auto On Batt Temp Low" 428 "Sps Auto Off Batt Temp High" 429 "Sps Auto On Batt Temp High" 430 "Sps Auto Off Heat Sink Temp High" 431 "Sps Auto On Heat Sink Temp High" 432 "Sps Auto Off Fault" 433 "Sps Auto On Fault" 434 "Aps Check Timeout" 435 "Aps Qualify Timeout" 512 "Resume From Safe" 513 "AC Fault Set" 514 "Invert Fault Set" 515 "Charge Fault Set" 516 "Charger Enable" 517 "Charger Disable" 518 "Inverter Enable" 519 "Inverter Disable" 520 "Charge Suspend On" 521 "Charge Suspend Off" 522 "AC Good" 523 "AC Bad" 524 "Load Sense Enable" 525 "Load Sense Active" 526 "Invert Active" 527 "Bulk Exit" 528 "Absorption Exit" 529 "Float Exit" 530 "Float 3-Stage Set" 531 "Float 2-Stage Set" 532 "Equalize Enable" 533 "Equalize Disable" 534 "Equalize Exit" 535 "Load Sense Disable" 536 "Sell To Grid Enabled" 537 "Sell To Grid Disabled" 538 "Grid Support Enable" 539 "Grid Support Disable" 540 "Gen Support Enable" 541 "Gen Support Disable" 542 "Peak Load Shaving Enable" 543 "Peak Load Shaving Disable" 544 "Peak Load Shaving Tod Start" 545 "Peak Load Shaving Tod Stop" 546 "Unit Off" 547 "System Absorption Exit" 548 "System Inverter Enable" 549 "System AC Good" 550 "Anti Islanding Condition" 551 "Hibernate Timeout" 552 "External Sync Error" 553 "External Suspend Request" 554 "Engaging Charger" 555 "Engaging Gen Support" 556 "Grid Tie Engage Timeout" 557 "Gen Support Engage Timeout" 558 "Charge Engage Timeout" 559 "Inverter Engage Timeout" 560 "Charge Exit Timeout" 561 "Grid Support Entry Amps" 562 "Grid Support Exit Amps" 563 "Gen Support Entry Amps" 564 "Gen Support Exit Amps" 565 "Grid Support Entry Vdc" 566 "Grid Support Exit Vdc" 567 "Low Batt Cut Off Entry Vdc" 568 "Low Batt Recharge Vdc" 569 "Low Batt Cut Off Exit Vdc" 570 "Invert To Bypass Timeout" 571 "Force Charge" 572 "System Engage Bulk Charge" 441 "SPS Auto On External Shutdown Flt" 442 "SPS Auto Off Input Over Volt Flt" 443 "SPS Auto On Input Over Volt Flt" 444 "SPS Auto Off Input Over Volt Err" 445 "SPS Auto On Input Over Volt Err" 446 "SPS Auto Off Input Over Volt Wrn" 447 "SPS Auto On Input Over Volt Wrn" 448 "SPS Auto Off Output Over Volt Err" 449 "SPS Auto On Output Over Volt Err" 450 "SPS Auto Off Output Over Volt Wrn" 451 "SPS Auto On Output Over Volt Wrn" 452 "SPS Auto Off Output Under Volt Err" 453 "SPS Auto On Output Under Volt Err" 454 "SPS Auto Off Output Under Volt Wrn" 455 "SPS Auto On Output Under Volt Wrn" 456 "SPS Auto Off Output Over Curr Err" 457 "SPS Auto On Output Over Curr Err" 458 "SPS Auto Off Batt Over Temp Err" 459 "SPS Auto On Batt Over Temp Err" 460 "SPS Auto Off Batt Over Temp Wrn" 461 "SPS Auto On Batt Over Temp Wrn" 462 "SPS Auto Off Batt Under Temp Wrn" 463 "SPS Auto On Batt Under Temp Wrn" 464 "SPS Auto Off Heatsink Over Temp Err" 465 "SPS Auto On Heatsink Over Temp Err" 466 "SPS Auto Off Heatsink Over Temp Wrn" 467 "SPS Auto On Heatsink Over Temp Wrn" 468 "SPS Auto Off Ambient Over Temp Err" 469 "SPS Auto On Ambient Over Temp Err" 470 "SPS Auto Off Ambient Over Temp Wrn" 471 "SPS Auto On Ambient Over Temp Wrn" 472 "SPS Auto Off Capacitor Over Temp Err" 473 "SPS Auto On Capacitor Over Temp Err" 474 "SPS Auto Off Fan Flt" 475 "SPS Auto On Fan Flt" 476 "SPS Auto Off Fan Err" 477 "SPS Auto On Fan Err" 478 "SPS Auto Off Input Over Curr Err" 479 "SPS Auto On Input Over Curr Err" 480 "SPS Auto Off Output Over Curr Flt" 481 "SPS Auto On Output Over Curr Flt" 482 "SPS Auto Off Network PS Flt" 483 "SPS Auto On Network PS Flt" 484 "SPS Auto Off Setup Flt" 485 "SPS Auto On Setup Flt" 38 "Clear Command User Stats" 573 "AC Good Pending" 574 "Grid Safe" 585 "PLS Time In Float Ready" 575 "Power Conversion Fault" 576 "Low Battery Support Exit" 577 "Grid Support Exit" 578 "GFS Enable" 579 "GFS Disable" 580 "Force Sell" 486 "SPS Auto On Bulk Exit" 487 "SPS Auto Off Bulk Exit" 488 "SPS Auto On Absorption Exit" 489 "SPS Auto Off Absorption Exit" 490 "SPS Auto On State Of Charge Low" 491 "SPS Auto Off State Of Charge Low" 492 "SPS Auto On Time Of Day" 493 "SPS Auto Off Time Of Day" 581 "Sell Time Of Day Start" 582 "Sell Time Of Day Stop" 583 "Aux Port Time Of Day Start" 584 "Aux Port Time Of Day Stop" ;
VAL_ 2147554048 CfgType 0 "User" 1 "OEM" 2 "Factory" 3 "Reserved" ;
VAL_ 2147554304 TempSensId 0 "Battery 1" 1 "Battery 2" 2 "Battery 3" 3 "Battery 4" 4 "Battery 5" 5 "Battery 6" 10 "Ambient 1" 11 "Ambient 2" 12 "Ambient 3" 13 "Ambient 4" 14 "Shunt 1" 15 "Shunt 2" 16 "Shunt 3" 17 "Shunt 4" 253 "Reserved" 254 "Out of Range" 255 "Data Not Available Do Not Change" ;
VAL_ 2147554304 RefEvtId 436 "SPS Auto Off Array V Low" 437 "SPS Auto On Array V Low" 438 "SPS Auto Off Ground Flt" 439 "SPS Auto On Ground Flt" 440 "SPS Auto Off External Shutdown Flt" 0 "None" 10 "Control Command Hibernate" 11 "Control Command Safe" 12 "Control Command Power Save" 13 "Control Command Operating" 14 "Control Command Diagnostic" 15 "Control Command Last Mode" 20 "Reset Command Reboot" 21 "Reset Command Download" 22 "Reset Command Oem" 23 "Reset Command Factory" 24 "Reset Command Reboot Clear Nv" 25 "Powered Up" 30 "Clear Command Active Faults" 31 "Clear Command Fault Log" 32 "Clear Command Active Warns" 33 "Clear Command Warn Log" 34 "Clear Command State Event Log" 35 "Clear Command Comm Stats" 36 "Clear Command Stats" 37 "Clear Command All" 40 "Date Time Configured" 50 "Warn Cleared" 51 "Fault Cleared" 52 "Fault Set" 60 "User Cfg Changed" 61 "Oem Cfg Changed" 70 "Triggered Fault" 250 "Shutdown Threshold" 251 "Shutdown Hysteresis" 252 "Warning Threshold" 253 "Warning Hysteresis" 254 "Transfer Threshold" 255 "Fan 0 Threshold" 256 "Fan 10 Threshold" 257 "Fan 20 Threshold" 258 "Fan 30 Threshold" 259 "Fan 40 Threshold" 260 "Fan 50 Threshold" 261 "Fan 60 Threshold" 262 "Fan 70 Threshold" 263 "Fan 80 Threshold" 264 "Fan 90 Threshold" 265 "Fan 100 Threshold" 266 "Relay Open Threshold" 267 "Relay Close Threshold" 268 "Charger Derating Ac In V" 269 "Charger Derating Ac In I" 270 "Charger Derating Ext Temp" 271 "Charger Derating Int Temp" 272 "Charger Derating Ripple V" 273 "Lost Ac Threshold" 274 "Lost Ac Hysteresis" 275 "Imm Shutdown Threshold" 276 "Imm Shutdown Hysteresis" 277 "Charger Shutdown Threshold" 278 "Charger Shutdown Hysteresis" 279 "Charger Warning Threshold" 280 "Charger Warning Hysteresis" 281 "Inverter Shutdown Threshold" 282 "Inverter Shutdown Hysteresis" 283 "Inverter Warning Threshold" 284 "Inverter Warning Hysteresis" 285 "Charger Derating Temp Start Point" 286 "Charger Derating Temp End Point" 287 "Charger Recharge Threshold" 300 "Ags Exercise Start" 301 "Ags Exercise Stop" 302 "Ags Quiet Time Begin" 303 "Ags Quiet Time End" 304 "Ags Battery Soc Start" 305 "Ags Battery Soc Stop" 306 "Ags Dc V Start" 307 "Ags Dc V Stop" 308 "Ags Ac I Start" 309 "Ags Ac I Stop" 310 "Ags Contact Start" 311 "Ags Contact Stop" 312 "Ags Float Stop" 313 "Ags Absorp Stop" 314 "Ags Manual On" 315 "Ags Manual Off" 316 "Ags Auto" 317 "Ags External On" 318 "Ags External Off" 319 "Gen External On" 320 "Gen External Off" 321 "Ags External Shutdown" 322 "Ags Auto Off" 323 "Ags Dc I Start" 324 "Ags Dc I Stop" 325 "Ags Ac Power Start" 326 "Ags Ac Power Stop" 400 "Sps Manual Off" 401 "Sps Manual On" 410 "Sps Auto Off" 411 "Sps Auto On" 420 "Sps Auto Off Batt V Low" 421 "Sps Auto On Batt V Low" 422 "Sps Auto Off Batt V High" 423 "Sps Auto On Batt V High" 424 "Sps Auto Off Array V High" 425 "Sps Auto On Array V High" 426 "Sps Auto Off Batt Temp Low" 427 "Sps Auto On Batt Temp Low" 428 "Sps Auto Off Batt Temp High" 429 "Sps Auto On Batt Temp High" 430 "Sps Auto Off Heat Sink Temp High" 431 "Sps Auto On Heat Sink Temp High" 432 "Sps Auto Off Fault" 433 "Sps Auto On Fault" 434 "Aps Check Timeout" 435 "Aps Qualify Timeout" 512 "Resume From Safe" 513 "AC Fault Set" 514 "Invert Fault Set" 515 "Charge Fault Set" 516 "Charger Enable" 517 "Charger Disable" 518 "Inverter Enable" 519 "Inverter Disable" 520 "Charge Suspend On" 521 "Charge Suspend Off" 522 "AC Good" 523 "AC Bad" 524 "Load Sense Enable" 525 "Load Sense Active" 526 "Invert Active" 527 "Bulk Exit" 528 "Absorption Exit" 529 "Float Exit" 530 "Float 3-Stage Set" 531 "Float 2-Stage Set" 532 "Equalize Enable" 533 "Equalize Disable" 534 "Equalize Exit" 535 "Load Sense Disable" 536 "Sell To Grid Enabled" 537 "Sell To Grid Disabled" 538 "Grid Support Enable" 539 "Grid Support Disable" 540 "Gen Support Enable" 541 "Gen Support Disable" 542 "Peak Load Shaving Enable" 543 "Peak Load Shaving Disable" 544 "Peak Load Shaving Tod Start" 545 "Peak Load Shaving Tod Stop" 546 "Unit Off" 547 "System Absorption Exit" 548 "System Inverter Enable" 549 "System AC Good" 550 "Anti Islanding Condition" 551 "Hibernate Timeout" 552 "External Sync Error" 553 "External Suspend Request" 554 "Engaging Charger" 555 "Engaging Gen Support" 556 "Grid Tie Engage Timeout" 557 "Gen Support Engage Timeout" 558 "Charge Engage Timeout" 559 "Inverter Engage Timeout" 560 "Charge Exit Timeout" 561 "Grid Support Entry Amps" 562 "Grid Support Exit Amps" 563 "Gen Support Entry Amps" 564 "Gen Support Exit Amps" 565 "Grid Support Entry Vdc" 566 "Grid Support Exit Vdc" 567 "Low Batt Cut Off Entry Vdc" 568 "Low Batt Recharge Vdc" 569 "Low Batt Cut Off Exit Vdc" 570 "Invert To Bypass Timeout" 571 "Force Charge" 572 "System Engage Bulk Charge" 441 "SPS Auto On External Shutdown Flt" 442 "SPS Auto Off Input Over Volt Flt" 443 "SPS Auto On Input Over Volt Flt" 444 "SPS Auto Off Input Over Volt Err" 445 "SPS Auto On Input Over Volt Err" 446 "SPS Auto Off Input Over Volt Wrn" 447 "SPS Auto On Input Over Volt Wrn" 448 "SPS Auto Off Output Over Volt Err" 449 "SPS Auto On Output Over Volt Err" 450 "SPS Auto Off Output Over Volt Wrn" 451 "SPS Auto On Output Over Volt Wrn" 452 "SPS Auto Off Output Under Volt Err" 453 "SPS Auto On Output Under Volt Err" 454 "SPS Auto Off Output Under Volt Wrn" 455 "SPS Auto On Output Under Volt Wrn" 456 "SPS Auto Off Output Over Curr Err" 457 "SPS Auto On Output Over Curr Err" 458 "SPS Auto Off Batt Over Temp Err" 459 "SPS Auto On Batt Over Temp Err" 460 "SPS Auto Off Batt Over Temp Wrn" 461 "SPS Auto On Batt Over Temp Wrn" 462 "SPS Auto Off Batt Under Temp Wrn" 463 "SPS Auto On Batt Under Temp Wrn" 464 "SPS Auto Off Heatsink Over Temp Err" 465 "SPS Auto On Heatsink Over Temp Err" 466 "SPS Auto Off Heatsink Over Temp Wrn" 467 "SPS Auto On Heatsink Over Temp Wrn" 468 "SPS Auto Off Ambient Over Temp Err" 469 "SPS Auto On Ambient Over Temp Err" 470 "SPS Auto Off Ambient Over Temp Wrn" 471 "SPS Auto On Ambient Over Temp Wrn" 472 "SPS Auto Off Capacitor Over Temp Err" 473 "SPS Auto On Capacitor Over Temp Err" 474 "SPS Auto Off Fan Flt" 475 "SPS Auto On Fan Flt" 476 "SPS Auto Off Fan Err" 477 "SPS Auto On Fan Err" 478 "SPS Auto Off Input Over Curr Err" 479 "SPS Auto On Input Over Curr Err" 480 "SPS Auto Off Output Over Curr Flt" 481 "SPS Auto On Output Over Curr Flt" 482 "SPS Auto Off Network PS Flt" 483 "SPS Auto On Network PS Flt" 484 "SPS Auto Off Setup Flt" 485 "SPS Auto On Setup Flt" 38 "Clear Command User Stats" 573 "AC Good Pending" 574 "Grid Safe" 585 "PLS Time In Float Ready" 575 "Power Conversion Fault" 576 "Low Battery Support Exit" 577 "Grid Support Exit" 578 "GFS Enable" 579 "GFS Disable" 580 "Force Sell" 486 "SPS Auto On Bulk Exit" 487 "SPS Auto Off Bulk Exit" 488 "SPS Auto On Absorption Exit" 489 "SPS Auto Off Absorption Exit" 490 "SPS Auto On State Of Charge Low" 491 "SPS Auto Off State Of Charge Low" 492 "SPS Auto On Time Of Day" 493 "SPS Auto Off Time Of Day" 581 "Sell Time Of Day Start" 582 "Sell Time Of Day Stop" 583 "Aux Port Time Of Day Start" 584 "Aux Port Time Of Day Stop" ;
VAL_ 2147554304 EvtId 436 "SPS Auto Off Array V Low" 437 "SPS Auto On Array V Low" 438 "SPS Auto Off Ground Flt" 439 "SPS Auto On Ground Flt" 440 "SPS Auto Off External Shutdown Flt" 0 "None" 10 "Control Command Hibernate" 11 "Control Command Safe" 12 "Control Command Power Save" 13 "Control Command Operating" 14 "Control Command Diagnostic" 15 "Control Command Last Mode" 20 "Reset Command Reboot" 21 "Reset Command Download" 22 "Reset Command Oem" 23 "Reset Command Factory" 24 "Reset Command Reboot Clear Nv" 25 "Powered Up" 30 "Clear Command Active Faults" 31 "Clear Command Fault Log" 32 "Clear Command Active Warns" 33 "Clear Command Warn Log" 34 "Clear Command State Event Log" 35 "Clear Command Comm Stats" 36 "Clear Command Stats" 37 "Clear Command All" 40 "Date Time Configured" 50 "Warn Cleared" 51 "Fault Cleared" 52 "Fault Set" 60 "User Cfg Changed" 61 "Oem Cfg Changed" 70 "Triggered Fault" 250 "Shutdown Threshold" 251 "Shutdown Hysteresis" 252 "Warning Threshold" 253 "Warning Hysteresis" 254 "Transfer Threshold" 255 "Fan 0 Threshold" 256 "Fan 10 Threshold" 257 "Fan 20 Threshold" 258 "Fan 30 Threshold" 259 "Fan 40 Threshold" 260 "Fan 50 Threshold" 261 "Fan 60 Threshold" 262 "Fan 70 Threshold" 263 "Fan 80 Threshold" 264 "Fan 90 Threshold" 265 "Fan 100 Threshold" 266 "Relay Open Threshold" 267 "Relay Close Threshold" 268 "Charger Derating Ac In V" 269 "Charger Derating Ac In I" 270 "Charger Derating Ext Temp" 271 "Charger Derating Int Temp" 272 "Charger Derating Ripple V" 273 "Lost Ac Threshold" 274 "Lost Ac Hysteresis" 275 "Imm Shutdown Threshold" 276 "Imm Shutdown Hysteresis" 277 "Charger Shutdown Threshold" 278 "Charger Shutdown Hysteresis" 279 "Charger Warning Threshold" 280 "Charger Warning Hysteresis" 281 "Inverter Shutdown Threshold" 282 "Inverter Shutdown Hysteresis" 283 "Inverter Warning Threshold" 284 "Inverter Warning Hysteresis" 285 "Charger Derating Temp Start Point" 286 "Charger Derating Temp End Point" 287 "Charger Recharge Threshold" 300 "Ags Exercise Start" 301 "Ags Exercise Stop" 302 "Ags Quiet Time Begin" 303 "Ags Quiet Time End" 304 "Ags Battery Soc Start" 305 "Ags Battery Soc Stop" 306 "Ags Dc V Start" 307 "Ags Dc V Stop" 308 "Ags Ac I Start" 309 "Ags Ac I Stop" 310 "Ags Contact Start" 311 "Ags Contact Stop" 312 "Ags Float Stop" 313 "Ags Absorp Stop" 314 "Ags Manual On" 315 "Ags Manual Off" 316 "Ags Auto" 317 "Ags External On" 318 "Ags External Off" 319 "Gen External On" 320 "Gen External Off" 321 "Ags External Shutdown" 322 "Ags Auto Off" 323 "Ags Dc I Start" 324 "Ags Dc I Stop" 325 "Ags Ac Power Start" 326 "Ags Ac Power Stop" 400 "Sps Manual Off" 401 "Sps Manual On" 410 "Sps Auto Off" 411 "Sps Auto On" 420 "Sps Auto Off Batt V Low" 421 "Sps Auto On Batt V Low" 422 "Sps Auto Off Batt V High" 423 "Sps Auto On Batt V High" 424 "Sps Auto Off Array V High" 425 "Sps Auto On Array V High" 426 "Sps Auto Off Batt Temp Low" 427 "Sps Auto On Batt Temp Low" 428 "Sps Auto Off Batt Temp High" 429 "Sps Auto On Batt Temp High" 430 "Sps Auto Off Heat Sink Temp High" 431 "Sps Auto On Heat Sink Temp High" 432 "Sps Auto Off Fault" 433 "Sps Auto On Fault" 434 "Aps Check Timeout" 435 "Aps Qualify Timeout" 512 "Resume From Safe" 513 "AC Fault Set" 514 "Invert Fault Set" 515 "Charge Fault Set" 516 "Charger Enable" 517 "Charger Disable" 518 "Inverter Enable" 519 "Inverter Disable" 520 "Charge Suspend On" 521 "Charge Suspend Off" 522 "AC Good" 523 "AC Bad" 524 "Load Sense Enable" 525 "Load Sense Active" 526 "Invert Active" 527 "Bulk Exit" 528 "Absorption Exit" 529 "Float Exit" 530 "Float 3-Stage Set" 531 "Float 2-Stage Set" 532 "Equalize Enable" 533 "Equalize Disable" 534 "Equalize Exit" 535 "Load Sense Disable" 536 "Sell To Grid Enabled" 537 "Sell To Grid Disabled" 538 "Grid Support Enable" 539 "Grid Support Disable" 540 "Gen Support Enable" 541 "Gen Support Disable" 542 "Peak Load Shaving Enable" 543 "Peak Load Shaving Disable" 544 "Peak Load Shaving Tod Start" 545 "Peak Load Shaving Tod Stop" 546 "Unit Off" 547 "System Absorption Exit" 548 "System Inverter Enable" 549 "System AC Good" 550 "Anti Islanding Condition" 551 "Hibernate Timeout" 552 "External Sync Error" 553 "External Suspend Request" 554 "Engaging Charger" 555 "Engaging Gen Support" 556 "Grid Tie Engage Timeout" 557 "Gen Support Engage Timeout" 558 "Charge Engage Timeout" 559 "Inverter Engage Timeout" 560 "Charge Exit Timeout" 561 "Grid Support Entry Amps" 562 "Grid Support Exit Amps" 563 "Gen Support Entry Amps" 564 "Gen Support Exit Amps" 565 "Grid Support Entry Vdc" 566 "Grid Support Exit Vdc" 567 "Low Batt Cut Off Entry Vdc" 568 "Low Batt Recharge Vdc" 569 "Low Batt Cut Off Exit Vdc" 570 "Invert To Bypass Timeout" 571 "Force Charge" 572 "System Engage Bulk Charge" 441 "SPS Auto On External Shutdown Flt" 442 "SPS Auto Off Input Over Volt Flt" 443 "SPS Auto On Input Over Volt Flt" 444 "SPS Auto Off Input Over Volt Err" 445 "SPS Auto On Input Over Volt Err" 446 "SPS Auto Off Input Over Volt Wrn" 447 "SPS Auto On Input Over Volt Wrn" 448 "SPS Auto Off Output Over Volt Err" 449 "SPS Auto On Output Over Volt Err" 450 "SPS Auto Off Output Over Volt Wrn" 451 "SPS Auto On Output Over Volt Wrn" 452 "SPS Auto Off Output Under Volt Err" 453 "SPS Auto On Output Under Volt Err" 454 "SPS Auto Off Output Under Volt Wrn" 455 "SPS Auto On Output Under Volt Wrn" 456 "SPS Auto Off Output Over Curr Err" 457 "SPS Auto On Output Over Curr Err" 458 "SPS Auto Off Batt Over Temp Err" 459 "SPS Auto On Batt Over Temp Err" 460 "SPS Auto Off Batt Over Temp Wrn" 461 "SPS Auto On Batt Over Temp Wrn" 462 "SPS Auto Off Batt Under Temp Wrn" 463 "SPS Auto On Batt Under Temp Wrn" 464 "SPS Auto Off Heatsink Over Temp Err" 465 "SPS Auto On Heatsink Over Temp Err" 466 "SPS Auto Off Heatsink Over Temp Wrn" 467 "SPS Auto On Heatsink Over Temp Wrn" 468 "SPS Auto Off Ambient Over Temp Err" 469 "SPS Auto On Ambient Over Temp Err" 470 "SPS Auto Off Ambient Over Temp Wrn" 471 "SPS Auto On Ambient Over Temp Wrn" 472 "SPS Auto Off Capacitor Over Temp Err" 473 "SPS Auto On Capacitor Over Temp Err" 474 "SPS Auto Off Fan Flt" 475 "SPS Auto On Fan Flt" 476 "SPS Auto Off Fan Err" 477 "SPS Auto On Fan Err" 478 "SPS Auto Off Input Over Curr Err" 479 "SPS Auto On Input Over Curr Err" 480 "SPS Auto Off Output Over Curr Flt" 481 "SPS Auto On Output Over Curr Flt" 482 "SPS Auto Off Network PS Flt" 483 "SPS Auto On Network PS Flt" 484 "SPS Auto Off Setup Flt" 485 "SPS Auto On Setup Flt" 38 "Clear Command User Stats" 573 "AC Good Pending" 574 "Grid Safe" 585 "PLS Time In Float Ready" 575 "Power Conversion Fault" 576 "Low Battery Support Exit" 577 "Grid Support Exit" 578 "GFS Enable" 579 "GFS Disable" 580 "Force Sell" 486 "SPS Auto On Bulk Exit" 487 "SPS Auto Off Bulk Exit" 488 "SPS Auto On Absorption Exit" 489 "SPS Auto Off Absorption Exit" 490 "SPS Auto On State Of Charge Low" 491 "SPS Auto Off State Of Charge Low" 492 "SPS Auto On Time Of Day" 493 "SPS Auto Off Time Of Day" 581 "Sell Time Of Day Start" 582 "Sell Time Of Day Stop" 583 "Aux Port Time Of Day Start" 584 "Aux Port Time Of Day Stop" ;
VAL_ 2147554304 CfgType 0 "User" 1 "OEM" 2 "Factory" 3 "Reserved" ;
VAL_ 2147598592 FeatureOverride 1 "Charging Disabled" 2 "Load Shaving Disabled" 3 "Force Sell Disabled" 253 "Reserved" 254 "Out Of Range" 255 "Data Not Available Do Not Change" 4 "Inverting Disabled" 5 "Aux Port Disabled" ;
VAL_ 2147598592 EvtDowMask 0 "Sunday" 1 "Monday" 2 "Tuesday" 3 "Wednesday" 4 "Thursday" 5 "Friday" 6 "Saturday" 7 "Invalid" 11 "Daily" 12 "Weekdays" 13 "Weekends" ;
VAL_ 2147598592 CfgType 0 "User" 1 "OEM" 2 "Factory" 3 "Reserved" ;
VAL_ 2147562496 PerTxEnDis 0 "Off" 1 "On" 2 "Reserved" 3 "No Change" ;
VAL_ 2147562496 IdentEnDis 0 "Off" 1 "On" 2 "Reserved" 3 "No Change" ;
VAL_ 2147562496 CfgType 0 "User" 1 "OEM" 2 "Factory" 3 "Reserved" ;
VAL_ 2147610663 RequestAcDisqualify 0 "Off" 1 "On" 2 "Reserved" 3 "No Change" ;
VAL_ 2147610663 AcSrcType 0 "Invalid" 1 "Single Phase" 2 "Split Phase" 253 "Reserved" 254 "Out Of Range" 255 "Data Not Available Do Not Change" ;
VAL_ 2147610663 AcLine 0 "Invalid" 1 "Line 1" 2 "Line 2" 3 "Line 3" 253 "Reserved" 254 "Out Of Range" 255 "Data Not Available Do Not Change" ;
VAL_ 2147610664 EnDisSts 0 "Off" 1 "On" 2 "Reserved" 3 "No Change" ;
VAL_ 2147610664 DcSrcId 0 "Invalid" 1 "None" 2 "Anonymous" 3 "HouseBatBank1" 4 "HouseBatBank2" 5 "HouseBatBank3" 6 "HouseBatBank4" 7 "HouseBatBank5" 8 "HouseBatBank6" 9 "StartBatBank1" 10 "StartBatBank2" 11 "StartBatBank3" 12 "StartBatBank4" 13 "StartBatBank5" 14 "StartBatBank6" 21 "SolarArray1" 22 "SolarArray2" 23 "SolarArray3" 24 "SolarArray4" 25 "SolarArray5" 26 "SolarArray6" 27 "SolarArray7" 28 "SolarArray8" 29 "SolarArray9" 30 "SolarArray10" 31 "SolarArray11" 32 "SolarArray12" 33 "SolarArray13" 34 "SolarArray14" 35 "SolarArray15" 36 "SolarArray16" 252 "All" 253 "Reserved" 254 "Out of Range" 255 "Data Not Available Do Not Change" ;
VAL_ 2147610664 CircuitId 0 "Invalid" 1 "Circuit 1" 2 "Circuit 2" 3 "Circuit 3" 4 "Circuit 4" 5 "Circuit 5" 6 "Circuit 6" 7 "Circuit 7" 8 "Circuit 8" 9 "Circuit 9" 10 "Circuit 10" 11 "Circuit 11" 12 "Circuit 12" 13 "Circuit 13" 14 "Circuit 14" 15 "Circuit 15" 16 "Circuit 16" 17 "Circuit 17" 18 "Circuit 18" 19 "Circuit 19" 20 "Circuit 20" 253 "Reserved" 254 "Out Of Range" 255 "Data Not Available/Do Not Change" ;
VAL_ 2147610664 AssocType 0 "Invalid" 1 "DCInput" 2 "DCOut" 3 "DCInputOut" 4 "Reserved" 5 "ACInput" 6 "ACOut" 7 "ACInputOut" ;
VAL_ 2147610664 AcSrcId 0 "Invalid" 1 "None" 2 "Anonymous" 3 "Shore1" 4 "Shore2" 5 "Shore3" 6 "Shore4" 7 "Shore5" 8 "Shore6" 9 "Shore7" 10 "Shore8" 11 "Shore9" 12 "Shore10" 13 "Shore11" 14 "Shore12" 15 "Shore13" 16 "Shore14" 17 "Shore15" 18 "Shore16" 19 "Gen1" 20 "Gen2" 21 "Gen3" 22 "Gen4" 23 "Gen5" 24 "Gen6" 25 "Gen7" 26 "Gen8" 27 "Gen9" 28 "Gen10" 29 "Gen11" 30 "Gen12" 31 "Gen13" 32 "Gen14" 33 "Gen15" 34 "Gen16" 35 "AC1" 36 "AC2" 37 "AC3" 38 "AC4" 39 "AC5" 40 "AC6" 41 "AC7" 42 "AC8" 43 "AC9" 44 "AC10" 45 "AC11" 46 "AC12" 47 "AC13" 48 "AC14" 49 "AC15" 50 "AC16" 51 "AC Load1" 52 "AC Load2" 53 "AC Load3" 54 "AC Load4" 55 "AC Load5" 56 "AC Load6" 57 "AC Load7" 58 "AC Load8" 59 "AC Load9" 60 "AC Load10" 61 "AC Load11" 62 "AC Load12" 63 "AC Load13" 64 "AC Load14" 65 "AC Load15" 66 "AC Load16" 67 "Grid1" 68 "Grid2" 69 "Grid3" 70 "Grid4" 71 "Grid5" 72 "Grid6" 73 "Grid7" 74 "Grid8" 75 "Grid9" 76 "Grid10" 77 "Grid11" 78 "Grid12" 79 "Grid13" 80 "Grid14" 81 "Grid15" 82 "Grid16" 252 "All" 253 "Reserved" 254 "Out Of Range" 255 "Data Not Available Do Not Change" ;
VAL_ 2147610664 AcLine 0 "Invalid" 1 "Line 1" 2 "Line 2" 3 "Line 3" 253 "Reserved" 254 "Out Of Range" 255 "Data Not Available Do Not Change" ;
VAL_ 2147573504 GenSoftStart 0 "Disable" 1 "Enable" 2 "Bypass" 3 "No Change" ;
VAL_ 2147573504 EnDisCircuit 0 "Off" 1 "On" 2 "Reserved" 3 "No Change" ;
VAL_ 2147573504 DcSrcId 0 "Invalid" 1 "None" 2 "Anonymous" 3 "HouseBatBank1" 4 "HouseBatBank2" 5 "HouseBatBank3" 6 "HouseBatBank4" 7 "HouseBatBank5" 8 "HouseBatBank6" 9 "StartBatBank1" 10 "StartBatBank2" 11 "StartBatBank3" 12 "StartBatBank4" 13 "StartBatBank5" 14 "StartBatBank6" 21 "SolarArray1" 22 "SolarArray2" 23 "SolarArray3" 24 "SolarArray4" 25 "SolarArray5" 26 "SolarArray6" 27 "SolarArray7" 28 "SolarArray8" 29 "SolarArray9" 30 "SolarArray10" 31 "SolarArray11" 32 "SolarArray12" 33 "SolarArray13" 34 "SolarArray14" 35 "SolarArray15" 36 "SolarArray16" 252 "All" 253 "Reserved" 254 "Out of Range" 255 "Data Not Available Do Not Change" ;
VAL_ 2147573504 CircuitId 0 "Invalid" 1 "Circuit 1" 2 "Circuit 2" 3 "Circuit 3" 4 "Circuit 4" 5 "Circuit 5" 6 "Circuit 6" 7 "Circuit 7" 8 "Circuit 8" 9 "Circuit 9" 10 "Circuit 10" 11 "Circuit 11" 12 "Circuit 12" 13 "Circuit 13" 14 "Circuit 14" 15 "Circuit 15" 16 "Circuit 16" 17 "Circuit 17" 18 "Circuit 18" 19 "Circuit 19" 20 "Circuit 20" 253 "Reserved" 254 "Out Of Range" 255 "Data Not Available/Do Not Change" ;
VAL_ 2147573504 CfgType 0 "User" 1 "OEM" 2 "Factory" 3 "Reserved" ;
VAL_ 2147573504 AssocType 0 "Invalid" 1 "DCInput" 2 "DCOut" 3 "DCInputOut" 4 "Reserved" 5 "ACInput" 6 "ACOut" 7 "ACInputOut" ;
VAL_ 2147573504 AcSrcId 0 "Invalid" 1 "None" 2 "Anonymous" 3 "Shore1" 4 "Shore2" 5 "Shore3" 6 "Shore4" 7 "Shore5" 8 "Shore6" 9 "Shore7" 10 "Shore8" 11 "Shore9" 12 "Shore10" 13 "Shore11" 14 "Shore12" 15 "Shore13" 16 "Shore14" 17 "Shore15" 18 "Shore16" 19 "Gen1" 20 "Gen2" 21 "Gen3" 22 "Gen4" 23 "Gen5" 24 "Gen6" 25 "Gen7" 26 "Gen8" 27 "Gen9" 28 "Gen10" 29 "Gen11" 30 "Gen12" 31 "Gen13" 32 "Gen14" 33 "Gen15" 34 "Gen16" 35 "AC1" 36 "AC2" 37 "AC3" 38 "AC4" 39 "AC5" 40 "AC6" 41 "AC7" 42 "AC8" 43 "AC9" 44 "AC10" 45 "AC11" 46 "AC12" 47 "AC13" 48 "AC14" 49 "AC15" 50 "AC16" 51 "AC Load1" 52 "AC Load2" 53 "AC Load3" 54 "AC Load4" 55 "AC Load5" 56 "AC Load6" 57 "AC Load7" 58 "AC Load8" 59 "AC Load9" 60 "AC Load10" 61 "AC Load11" 62 "AC Load12" 63 "AC Load13" 64 "AC Load14" 65 "AC Load15" 66 "AC Load16" 67 "Grid1" 68 "Grid2" 69 "Grid3" 70 "Grid4" 71 "Grid5" 72 "Grid6" 73 "Grid7" 74 "Grid8" 75 "Grid9" 76 "Grid10" 77 "Grid11" 78 "Grid12" 79 "Grid13" 80 "Grid14" 81 "Grid15" 82 "Grid16" 252 "All" 253 "Reserved" 254 "Out Of Range" 255 "Data Not Available Do Not Change" ;
VAL_ 2147573504 AcLine 0 "Invalid" 1 "Line 1" 2 "Line 2" 3 "Line 3" 253 "Reserved" 254 "Out Of Range" 255 "Data Not Available Do Not Change" ;
